VERSION ""

NS_ :

BS_:

BU_: XXX DSU HCU EPS IPAS XX X

BO_ 359 STEERING_IPAS_COMMA: 8 IPAS

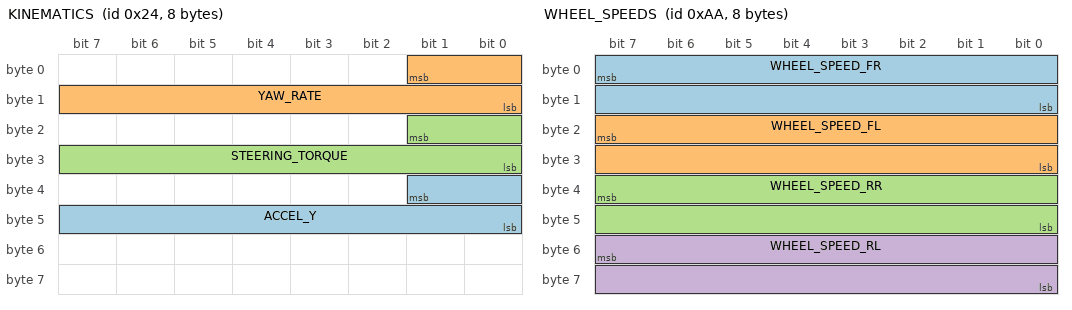
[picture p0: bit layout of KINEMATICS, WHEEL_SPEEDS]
BO_ 36 KINEMATICS: 8 XXX
 SG_ ACCEL_Y : 33|10@0+ (1,-512) [0|65535] "" XXX
 SG_ YAW_RATE : 1|10@0+ (1,-512) [0|65535] "" XXX
 SG_ STEERING_TORQUE : 17|10@0+ (1,-512) [0|65535] "" XXX

BO_ 166 BRAKE: 8 XXX
 SG_ BRAKE_AMOUNT : 7|8@0+ (1,0) [0|255] "" XXX
 SG_ BRAKE_PEDAL : 23|8@0+ (1,0) [0|255] "" XXX

BO_ 170 WHEEL_SPEEDS: 8 XXX
 SG_ WHEEL_SPEED_FR : 7|16@0+ (0.01,-67.67) [0|250] "kph" XXX
 SG_ WHEEL_SPEED_FL : 23|16@0+ (0.01,-67.67) [0|250] "kph" XXX
 SG_ WHEEL_SPEED_RR : 39|16@0+ (0.01,-67.67) [0|250] "kph" XXX
 SG_ WHEEL_SPEED_RL : 55|16@0+ (0.01,-67.67) [0|250] "kph" XXX

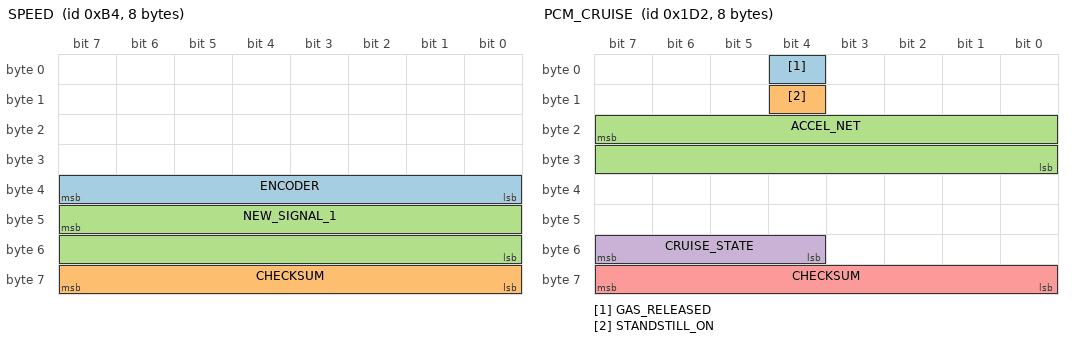
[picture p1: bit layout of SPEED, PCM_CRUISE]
BO_ 180 SPEED: 8 XXX
 SG_ ENCODER : 39|8@0+ (1,0) [0|255] "" XXX
 SG_ CHECKSUM : 63|8@0+ (1,0) [0|255] "" XXX
 SG_ NEW_SIGNAL_1 : 47|16@0+ (0.01,0) [0|65535] "" XXX

BO_ 466 PCM_CRUISE: 8 XXX
 SG_ GAS_RELEASED : 4|1@0+ (1,0) [0|1] "" XXX
 SG_ STANDSTILL_ON : 12|1@0+ (1,0) [0|1] "" XXX
 SG_ ACCEL_NET : 23|16@0- (0.001,0) [-20|20] "m/s2" XXX
 SG_ CRUISE_STATE : 55|4@0+ (1,0) [0|15] "" XXX
 SG_ CHECKSUM : 63|8@0+ (1,0) [0|255] "" XXX

BO_ 552 ACCELEROMETER: 8 XXX
 SG_ ACCEL_Z : 22|15@0- (1,0) [0|32767] "" XXX
 SG_ ACCEL_X : 6|15@0- (0.001,0) [-20|20] "m/s2" XXX

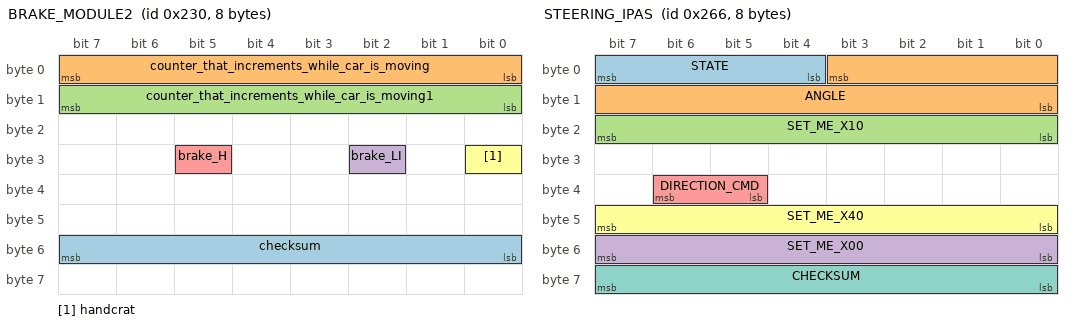
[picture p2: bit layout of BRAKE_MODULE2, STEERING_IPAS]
BO_ 560 BRAKE_MODULE2: 8 XXX
 SG_ checksum : 55|8@0+ (1,0) [0|255] "" XXX
 SG_ counter_that_increments_while_car_is_moving : 7|8@0+ (1,0) [0|255] "" XXX
 SG_ counter_that_increments_while_car_is_moving1 : 15|8@0+ (1,0) [0|255] "" XXX
 SG_ brake_LI : 26|1@1+ (1,0) [0|1] "" XXX
 SG_ brake_H : 29|1@0+ (1,0) [0|1] "" XXX
 SG_ handcrat : 24|1@1+ (1,0) [0|3] "" XXX

BO_ 614 STEERING_IPAS: 8 IPAS
 SG_ STATE : 7|4@0+ (1,0) [0|15] "" XXX
 SG_ ANGLE : 3|12@0- (1.5,0) [-510|510] "deg" XXX
 SG_ SET_ME_X10 : 23|8@0+ (1,0) [0|255] "" XXX
 SG_ SET_ME_X00 : 55|8@0+ (1,0) [0|255] "" XXX
 SG_ DIRECTION_CMD : 38|2@0+ (1,0) [0|3] "" XXX
 SG_ SET_ME_X40 : 47|8@0+ (1,0) [0|255] "" XXX
 SG_ CHECKSUM : 63|8@0+ (1,0) [0|255] "" XXX

BO_ 643 PRE_COLLISION: 8 XXX

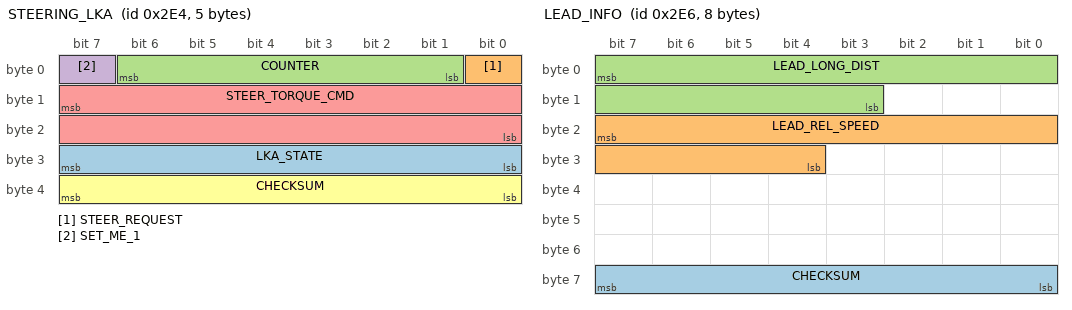
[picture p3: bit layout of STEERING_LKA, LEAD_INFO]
BO_ 740 STEERING_LKA: 5 XXX
 SG_ LKA_STATE : 31|8@0+ (1,0) [0|255] "" XXX
 SG_ STEER_REQUEST : 0|1@0+ (1,0) [0|1] "" XXX
 SG_ COUNTER : 6|6@0+ (1,0) [0|63] "" XXX
 SG_ SET_ME_1 : 7|1@0+ (1,0) [0|1] "" XXX
 SG_ STEER_TORQUE_CMD : 15|16@0- (1,0) [0|65535] "" XXX
 SG_ CHECKSUM : 39|8@0+ (1,0) [0|255] "" XXX

BO_ 742 LEAD_INFO: 8 DSU
 SG_ CHECKSUM : 63|8@0+ (1,0) [0|255] "" HCU
 SG_ LEAD_REL_SPEED : 23|12@0- (0.025,0) [-100|100] "m/s" HCU
 SG_ LEAD_LONG_DIST : 7|13@0+ (0.05,0) [0|300] "m" HCU

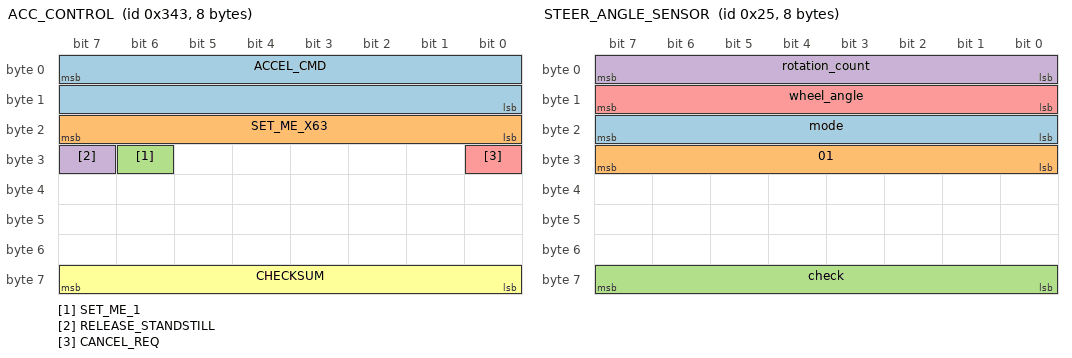
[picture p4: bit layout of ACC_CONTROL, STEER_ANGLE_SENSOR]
BO_ 835 ACC_CONTROL: 8 DSU
 SG_ ACCEL_CMD : 7|16@0- (0.001,0) [-20|20] "m/s2" HCU
 SG_ SET_ME_X63 : 23|8@0+ (1,0) [0|255] "" HCU
 SG_ SET_ME_1 : 30|1@0+ (1,0) [0|1] "" HCU
 SG_ RELEASE_STANDSTILL : 31|1@0+ (1,0) [0|1] "" HCU
 SG_ CANCEL_REQ : 24|1@0+ (1,0) [0|1] "" HCU
 SG_ CHECKSUM : 63|8@0+ (1,0) [0|255] "" XXX

BO_ 1556 STEERING_LEVERS: 8 XXX
 SG_ TURN_SIGNALS : 29|2@0+ (1,0) [0|3] "" XXX

BO_ 37 STEER_ANGLE_SENSOR: 8 XXX
 SG_ mode : 23|8@0+ (1,0) [0|255] "" XXX
 SG_ 01 : 31|8@0+ (1,0) [0|255] "" XXX
 SG_ check : 63|8@0+ (1,0) [0|255] "" XXX
 SG_ rotation_count : 7|8@0+ (1,0) [0|255] "" XXX
 SG_ wheel_angle : 15|8@0- (1,0) [0|255] "" XXX

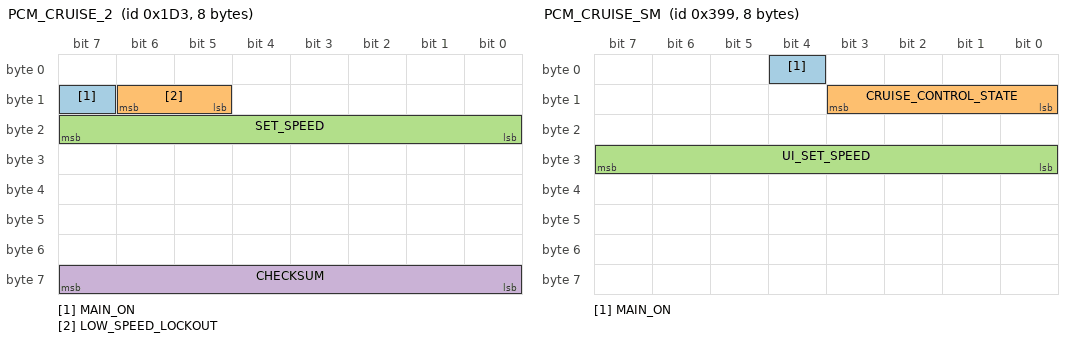
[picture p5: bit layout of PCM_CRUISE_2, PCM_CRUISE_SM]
BO_ 467 PCM_CRUISE_2: 8 XXX
 SG_ MAIN_ON : 15|1@0+ (1,0) [0|1] "" XXX
 SG_ LOW_SPEED_LOCKOUT : 14|2@0+ (1,0) [0|3] "kph" XXX
 SG_ SET_SPEED : 23|8@0+ (1,0) [0|255] "kph" XXX
 SG_ CHECKSUM : 63|8@0+ (1,0) [0|255] "" XXX

BO_ 921 PCM_CRUISE_SM: 8 XXX
 SG_ MAIN_ON : 4|1@0+ (1,0) [0|1] "" XXX
 SG_ CRUISE_CONTROL_STATE : 11|4@0+ (1,0) [0|15] "" XXX
 SG_ UI_SET_SPEED : 31|8@0+ (1,0) [0|255] "" XXX

BO_ 951 ESP_CONTROL: 8 ESP
 SG_ TC_DISABLED : 13|1@0+ (1,0) [0|1] "" XXX
 SG_ BRAKE_LIGHTS_ACC : 18|1@0+ (1,0) [0|1] "" XXX

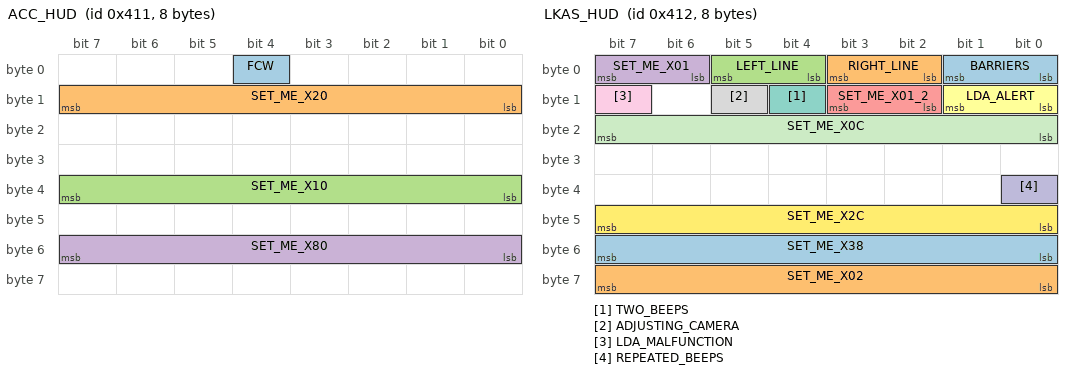
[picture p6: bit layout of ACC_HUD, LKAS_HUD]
BO_ 1041 ACC_HUD: 8 DSU
 SG_ FCW : 4|1@0+ (1,0) [0|1] "" XXX
 SG_ SET_ME_X20 : 15|8@0+ (1,0) [0|1] "" XXX
 SG_ SET_ME_X10 : 39|8@0+ (1,0) [0|1] "" XXX
 SG_ SET_ME_X80 : 55|8@0+ (1,0) [0|1] "" XXX

BO_ 1042 LKAS_HUD: 8 XXX
 SG_ BARRIERS : 1|2@0+ (1,0) [0|3] "" XXX
 SG_ RIGHT_LINE : 3|2@0+ (1,0) [0|3] "" XXX
 SG_ LEFT_LINE : 5|2@0+ (1,0) [0|3] "" XXX
 SG_ SET_ME_X01 : 7|2@0+ (1,0) [0|3] "" XXX
 SG_ SET_ME_X01_2 : 11|2@0+ (1,0) [0|3] "" XXX
 SG_ LDA_ALERT : 9|2@0+ (1,0) [0|3] "" XXX
 SG_ TWO_BEEPS : 12|1@0+ (1,0) [0|1] "" XXX
 SG_ ADJUSTING_CAMERA : 13|1@0+ (1,0) [0|1] "" XXX
 SG_ LDA_MALFUNCTION : 15|1@0+ (1,0) [0|1] "" XXX
 SG_ REPEATED_BEEPS : 32|1@0+ (1,0) [0|1] "" XXX
 SG_ SET_ME_X0C : 23|8@0+ (1,0) [0|1] "" XXX
 SG_ SET_ME_X2C : 47|8@0+ (1,0) [0|1] "" XXX
 SG_ SET_ME_X38 : 55|8@0+ (1,0) [0|1] "" XXX
 SG_ SET_ME_X02 : 63|8@0+ (1,0) [0|1] "" XXX

BO_ 1553 UI_SEETING: 8 XXX
 SG_ UNITS : 26|2@0+ (1,0) [0|3] "" XXX

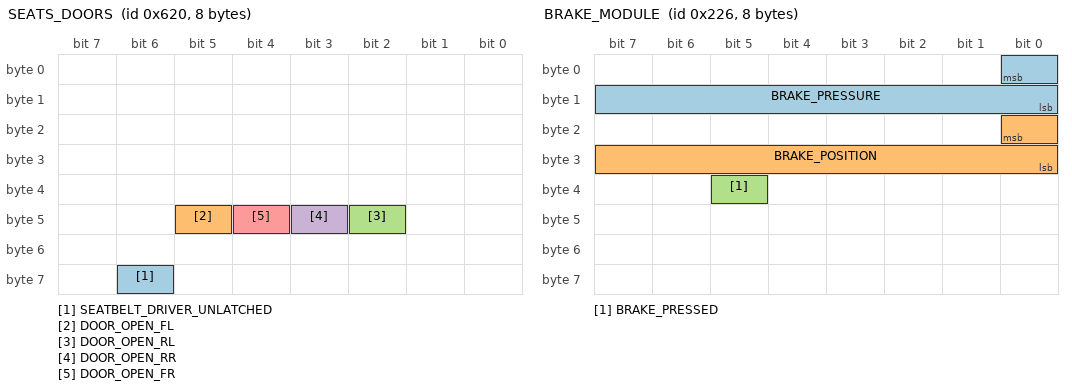
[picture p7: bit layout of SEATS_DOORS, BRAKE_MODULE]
BO_ 1568 SEATS_DOORS: 8 XXX
 SG_ SEATBELT_DRIVER_UNLATCHED : 62|1@0+ (1,0) [0|1] "" XXX
 SG_ DOOR_OPEN_FL : 45|1@0+ (1,0) [0|1] "" XXX
 SG_ DOOR_OPEN_RL : 42|1@0+ (1,0) [0|1] "" XXX
 SG_ DOOR_OPEN_RR : 43|1@0+ (1,0) [0|1] "" XXX
 SG_ DOOR_OPEN_FR : 44|1@0+ (1,0) [0|1] "" XXX

BO_ 1570 LIGHT_STALK: 8 SCM
 SG_ AUTO_HIGH_BEAM : 37|1@0+ (1,0) [0|1] "" XXX

BO_ 295 GEAR_PACKET: 8 XXX

BO_ 550 BRAKE_MODULE: 8 XXX
 SG_ BRAKE_PRESSURE : 0|9@0+ (1,0) [0|511] "" XXX
 SG_ BRAKE_POSITION : 16|9@0+ (1,0) [0|511] "" XXX
 SG_ BRAKE_PRESSED : 37|1@0+ (1,0) [0|1] "" XXX

BO_ 581 GAS_PEDAL: 8 XXX
 SG_ GAS_PEDAL : 23|8@0+ (0.005,0) [0|1] "" XXX

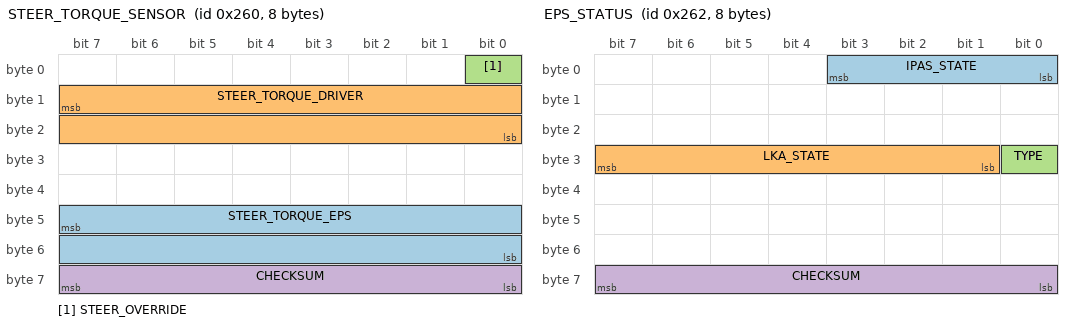
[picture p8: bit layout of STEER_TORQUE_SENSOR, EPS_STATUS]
BO_ 608 STEER_TORQUE_SENSOR: 8 XXX
 SG_ STEER_TORQUE_EPS : 47|16@0- (0.66,0) [-20000|20000] "" XXX
 SG_ STEER_TORQUE_DRIVER : 15|16@0- (1,0) [-32768|32767] "" XXX
 SG_ STEER_OVERRIDE : 0|1@0+ (1,0) [0|1] "" XXX
 SG_ CHECKSUM : 63|8@0+ (1,0) [0|255] "" XXX

BO_ 610 EPS_STATUS: 8 EPS
 SG_ IPAS_STATE : 3|4@0+ (1,0) [0|15] "" XXX
 SG_ LKA_STATE : 31|7@0+ (1,0) [0|127] "" XXX
 SG_ TYPE : 24|1@0+ (1,0) [0|1] "" XXX
 SG_ CHECKSUM : 63|8@0+ (1,0) [0|255] "" XXX

BO_ 1083 AUTOPARK_STATUS: 8 IPAS
 SG_ STATE : 7|4@0+ (1,0) [0|15] "" XXX

BO_ 179 SPEED_2: 8 XXX
 SG_ SPEED : 7|16@0+ (1,0) [0|65535] "" XXX
 SG_ CHECKSUM : 47|8@0+ (1,0) [0|255] "" XXX

BO_ 177 SPEED_1: 8 XXX
 SG_ SPEED : 7|16@0+ (1,0) [0|65535] "" XXX
 SG_ CHECKSUM : 47|8@0+ (1,0) [0|255] "" XXX
 SG_ Uncertain_gear1 : 15|8@0+ (1,0) [0|255] "" XXX
 SG_ Uncertain_gear2 : 35|4@0+ (1,0) [0|255] "" XXX
 SG_ speed : 23|8@0+ (2.5,0) [0|255] "" XXX

BO_ 1792 NEW_MSG_2: 8 XXX
 SG_ NEW_SIGNAL_1 : 7|24@0+ (1,0) [0|16777215] "" XXX

BO_ 1872 NEW_MSG_3: 8 XXX
 SG_ NEW_SIGNAL_1 : 7|24@0+ (1,0) [0|16777215] "" XXX

BO_ 2016 NEW_MSG_4: 8 XXX
 SG_ NEW_SIGNAL_1 : 7|24@0+ (1,0) [0|16777215] "" XXX

BO_ 2018 NEW_MSG_5: 8 XXX
 SG_ NEW_SIGNAL_1 : 7|24@0+ (1,0) [0|16777215] "" XXX

BO_ 2019 NEW_MSG_6: 8 XXX
 SG_ NEW_SIGNAL_1 : 7|24@0+ (1,0) [0|16777215] "" XXX

BO_ 2027 NEW_MSG_7: 8 XXX
 SG_ NEW_SIGNAL_1 : 7|24@0+ (1,0) [0|16777215] "" XXX

BO_ 1462 door: 8 XXX
 SG_ doorpause : 7|8@0+ (1,0) [0|255] "" XXX
 SG_ door_80off : 15|8@0+ (1,0) [0|255] "" XXX

BO_ 1517 NEW_MSG_8: 8 XXX

BO_ 1528 NEW_MSG_9: 8 XXX

BO_ 1538 NEW_MSG_10: 8 XXX

BO_ 1425 NEW_MSG_11: 8 XXX

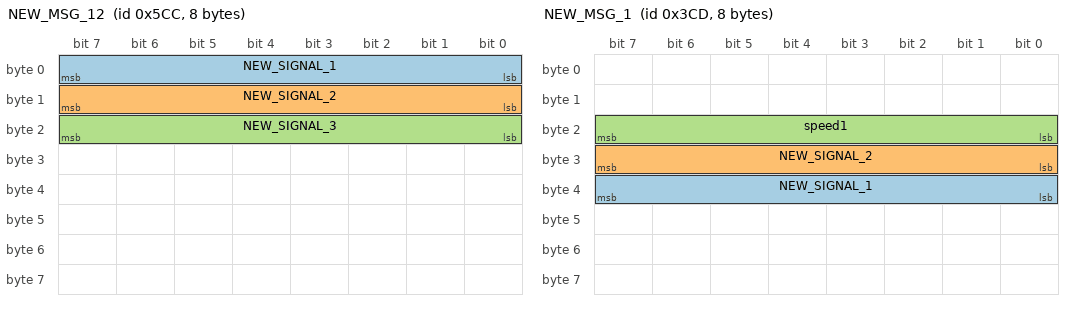
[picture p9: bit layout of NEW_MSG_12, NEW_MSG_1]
BO_ 1484 NEW_MSG_12: 8 XXX
 SG_ NEW_SIGNAL_1 : 7|8@0+ (1,0) [0|255] "" XXX
 SG_ NEW_SIGNAL_2 : 15|8@0+ (1,0) [0|255] "" XXX
 SG_ NEW_SIGNAL_3 : 23|8@0+ (1,0) [0|255] "" XXX

BO_ 1407 NEW_MSG_13: 8 XXX
 SG_ Headlamps_1 : 12|1@0+ (1,0) [0|3] "" XXX
 SG_ Headlamps_3 : 11|1@1+ (1,0) [0|3] "" XXX
 SG_ pause : 7|8@0+ (1,0) [0|255] "" XXX
 SG_ Headlamps_2 : 13|2@0+ (1,0) [0|3] "" XXX
 SG_ dimmed : 20|2@0+ (1,0) [0|3] "" XXX

BO_ 580 NEW_MSG_14: 8 XXX
 SG_ NEW_SIGNAL_1 : 40|8@1+ (1,0) [0|255] "" XXX
 SG_ NEW_SIGNAL_2 : 56|8@1+ (1,0) [0|255] "" XXX

BO_ 840 NEW_MSG_15: 8 XXX
 SG_ NEW_SIGNAL_2 : 15|16@0+ (1,0) [0|255] "" XXX
 SG_ NEW_SIGNAL_1 : 39|16@0+ (0.0012,0) [0|255] "" XXX

BO_ 288 gear: 8 XXX
 SG_ gear_1 : 47|8@0+ (1,0) [0|255] "" XXX
 SG_ gear_2 : 63|8@0+ (1,0) [0|255] "" XXX

BO_ 973 NEW_MSG_1: 8 XXX
 SG_ NEW_SIGNAL_1 : 39|8@0+ (1,0) [0|255] "" XXX
 SG_ NEW_SIGNAL_2 : 31|8@0+ (1,0) [0|255] "" XXX
 SG_ speed1 : 23|8@0+ (2.3,0) [0|255] "" XXX

BO_ 970 speedkm: 8 XXX
 SG_ speedkm : 23|8@0+ (2.4,0) [0|255] "" XXX

BO_ 1324 Engine_coolant_temp: 8 XXX
 SG_ Engine_coolant_temp : 15|8@0+ (0.5,0) [0|255] "" XXX

BO_ 1344 Shift_lever: 8 XXX
 SG_ gear : 15|8@0+ (1,0) [0|255] "" XXX

CM_ SG_ 36 ACCEL_Y "unit is tbd";
CM_ SG_ 36 YAW_RATE "verify";
CM_ SG_ 36 STEERING_TORQUE "does not seem the steer torque, tbd";
CM_ SG_ 466 ACCEL_NET "net acceleration produced by the system, given ACCEL_CMD, road grade and other factors";
CM_ SG_ 614 ANGLE "set to measured angle when ipas control isn't active";
CM_ SG_ 467 LOW_SPEED_LOCKOUT "in low speed lockout, system would always disengage below 28mph";
CM_ SG_ 467 SET_SPEED "43 kph are shown as 28mph, so conversion isnt perfect";
CM_ SG_ 921 UI_SET_SPEED "set speed shown in UI with user set unit";
CM_ SG_ 951 BRAKE_LIGHTS_ACC "brake lights when ACC commands decel";
CM_ SG_ 1042 REPEATED_BEEPS "recommended for fcw and other important alerts";
CM_ SG_ 550 BRAKE_PRESSURE "seems prop to pedal force";
CM_ SG_ 550 BRAKE_POSITION "seems proportional to pedal displacement, unclear the max value of 0x1c8";
CM_ SG_ 581 GAS_PEDAL "it seems slightly filtered";
CM_ SG_ 610 TYPE "seems 1 on Corolla, 0 on all others";
CM_ SG_ 1083 STATE "when the dashboard button is pressed, the value changes from zero to non-zero";
VAL_ 466 CRUISE_STATE 8 "active" 7 "standstill" 1 "off" ;
VAL_ 614 STATE 3 "enabled" 1 "disabled" ;
VAL_ 614 DIRECTION_CMD 3 "right" 2 "center" 1 "left" ;
VAL_ 1556 TURN_SIGNALS 3 "none" 2 "right" 1 "left" ;
VAL_ 467 LOW_SPEED_LOCKOUT 2 "low speed locked" 1 "ok" ;
VAL_ 921 CRUISE_CONTROL_STATE 2 "disabled" 11 "hold" 10 "hold_waiting_user_cmd" 6 "enabled" 5 "faulted" ;
VAL_ 1042 BARRIERS 3 "both" 2 "right" 1 "left" 0 "none" ;
VAL_ 1042 RIGHT_LINE 3 "orange" 2 "double" 1 "solid" 0 "none" ;
VAL_ 1042 LEFT_LINE 3 "orange" 2 "double" 1 "solid" 0 "none" ;
VAL_ 1042 LDA_ALERT 3 "hold with continuous beep" 2 "LDA unavailable" 1 "hold" 0 "none" ;
VAL_ 1553 UNITS 1 "km" 2 "miles" ;
VAL_ 610 IPAS_STATE 5 "override" 3 "enabled" 1 "disabled" ;
VAL_ 610 LKA_STATE 25 "temporary_fault" 9 "temporary_fault2" 5 "active" 1 "standby" ;
CM_ "AUTOGENERATED FILE, DO NOT EDIT"
CM_ "Imported file _comma.dbc s";
CM_ "Imported file _comma.dbc st
CM_ "Imported file _comma.dbc st";
CM_ "Imported file _comma.dbc sta
CM_ "Imported file _comma.dbc st";
CM_ "Imported file _comma.dbc sta
CM_ "Imported file _comma.dbc sta";
CM_ "Imported file _comma.dbc star
CM_ "Imported file _comma.dbc st";
CM_ "Imported file _comma.dbc sta
CM_ "Imported file _comma.dbc sta";
CM_ "Imported file _comma.dbc star
CM_ "Imported file _comma.dbc sta";
CM_ "Imported file _comma.dbc star
CM_ "Imported file _comma.dbc star";
CM_ "Imported file _comma.dbc start
CM_ "Imported file _comma.dbc st";
CM_ "Imported file _comma.dbc sta
CM_ "Imported file _comma.dbc sta";
CM_ "Imported file _comma.dbc star
CM_ "Imported file _comma.dbc sta";
CM_ "Imported file _comma.dbc star
CM_ "Imported file _comma.dbc star";
CM_ "Imported file _comma.dbc start
CM_ "Imported file _comma.dbc sta";
CM_ "Imported file _comma.dbc star
CM_ "Imported file _comma.dbc star";
CM_ "Imported file _comma.dbc start
CM_ "Imported file _comma.dbc star";
CM_ "Imported file _comma.dbc start
CM_ "Imported file _comma.dbc start";
CM_ "Imported file _comma.dbc starts
CM_ "Imported file _comma.dbc s";
CM_ "Imported file _comma.dbc st
CM_ "Imported file _comma.dbc st";
CM_ "Imported file _comma.dbc sta
CM_ "Imported file _comma.dbc st";
CM_ "Imported file _comma.dbc sta
CM_ "Imported file _comma.dbc sta";
CM_ "Imported file _comma.dbc star
CM_ "Imported file _comma.dbc st";
CM_ "Imported file _comma.dbc sta
CM_ "Imported file _comma.dbc sta";
CM_ "Imported file _comma.dbc star
CM_ "Imported file _comma.dbc sta";
CM_ "Imported file _comma.dbc star
CM_ "Imported file _comma.dbc star";
CM_ "Imported file _comma.dbc start
CM_ "Imported file _comma.dbc st";
CM_ "Imported file _comma.dbc sta
CM_ "Imported file _comma.dbc sta";
CM_ "Imported file _comma.dbc star
CM_ "Imported file _comma.dbc sta";
CM_ "Imported file _comma.dbc star
CM_ "Imported file _comma.dbc star";
CM_ "Imported file _comma.dbc start
CM_ "Imported file _comma.dbc sta";
CM_ "Imported file _comma.dbc star
CM_ "Imported file _comma.dbc star";
CM_ "Imported file _comma.dbc start
CM_ "Imported file _comma.dbc star";
CM_ "Imported file _comma.dbc start
CM_ "Imported file _comma.dbc start";
CM_ "Imported file _comma.dbc starts
CM_ "Imported file _comma.dbc st";
CM_ "Imported file _comma.dbc sta
CM_ "Imported file _comma.dbc sta";
CM_ "Imported file _comma.dbc star
CM_ "Imported file _comma.dbc sta";
CM_ "Imported file _comma.dbc star
CM_ "Imported file _comma.dbc star";
CM_ "Imported file _comma.dbc start
CM_ "Imported file _comma.dbc sta";
CM_ "Imported file _comma.dbc star
CM_ "Imported file _comma.dbc star";
CM_ "Imported file _comma.dbc start
CM_ "Imported file _comma.dbc star";
CM_ "Imported file _comma.dbc start
CM_ "Imported file _comma.dbc start";
CM_ "Imported file _comma.dbc starts
CM_ "Imported file _comma.dbc st";
CM_ "Imported file _comma.dbc sta
CM_ "Imported file _comma.dbc sta";
CM_ "Imported file _comma.dbc star
CM_ "Imported file _comma.dbc sta";
CM_ "Imported file _comma.dbc star
CM_ "Imported file _comma.dbc star";
CM_ "Imported file _comma.dbc start
CM_ "Imported file _comma.dbc sta";
CM_ "Imported file _comma.dbc star
CM_ "Imported file _comma.dbc star";
CM_ "Imported file _comma.dbc start
CM_ "Imported file _comma.dbc star";
CM_ "Imported file _comma.dbc start
CM_ "Imported file _comma.dbc start";
CM_ "Imported file _comma.dbc starts
CM_ "Imported file _comma.dbc sta";
CM_ "Imported file _comma.dbc star
CM_ "Imported file _comma.dbc star";
CM_ "Imported file _comma.dbc start
CM_ "Imported file _comma.dbc star";
CM_ "Imported file _comma.dbc start
CM_ "Imported file _comma.dbc start";
CM_ "Imported file _comma.dbc starts
CM_ "Imported file _comma.dbc sta";
CM_ "Imported file _comma.dbc star
CM_ "Imported file _comma.dbc star";
CM_ "Imported file _comma.dbc start
CM_ "Imported file _comma.dbc star";
CM_ "Imported file _comma.dbc start
CM_ "Imported file _comma.dbc start";
CM_ "Imported file _comma.dbc starts
CM_ "Imported file _comma.dbc star";
CM_ "Imported file _comma.dbc start
CM_ "Imported file _comma.dbc start";
CM_ "Imported file _comma.dbc starts
CM_ "Imported file _comma.dbc star";
CM_ "Imported file _comma.dbc start
CM_ "Imported file _comma.dbc start";
CM_ "Imported file _comma.dbc starts
CM_ "Imported file _comma.dbc start";
CM_ "Imported file _comma.dbc starts
CM_ "Imported file _comma.dbc start";
CM_ "Imported file _comma.dbc starts
CM_ "Imported file _comma.dbc starts";
CM_ "Imported file _comma.dbc starts 
CM_ "Imported file _comma.dbc starts ";
CM_ "Imported file _comma.dbc starts h
CM_ "Imported file _comma.dbc st";
CM_ "Imported file _comma.dbc sta
CM_ "Imported file _comma.dbc sta";
CM_ "Imported file _comma.dbc star
CM_ "Imported file _comma.dbc sta";
CM_ "Imported file _comma.dbc star
CM_ "Imported file _comma.dbc star";
CM_ "Imported file _comma.dbc start
CM_ "Imported file _comma.dbc sta";
CM_ "Imported file _comma.dbc star
CM_ "Imported file _comma.dbc star";
CM_ "Imported file _comma.dbc start
CM_ "Imported file _comma.dbc star";
CM_ "Imported file _comma.dbc start
CM_ "Imported file _comma.dbc start";
CM_ "Imported file _comma.dbc starts
CM_ "Imported file _comma.dbc st";
CM_ "Imported file _comma.dbc sta
CM_ "Imported file _comma.dbc sta";
CM_ "Imported file _comma.dbc star
CM_ "Imported file _comma.dbc sta";
CM_ "Imported file _comma.dbc star
CM_ "Imported file _comma.dbc star";
CM_ "Imported file _comma.dbc start
CM_ "Imported file _comma.dbc sta";
CM_ "Imported file _comma.dbc star
CM_ "Imported file _comma.dbc star";
CM_ "Imported file _comma.dbc start
CM_ "Imported file _comma.dbc star";
CM_ "Imported file _comma.dbc start
CM_ "Imported file _comma.dbc start";
CM_ "Imported file _comma.dbc starts
CM_ "Imported file _comma.dbc sta";
CM_ "Imported file _comma.dbc star
CM_ "Imported file _comma.dbc star";
CM_ "Imported file _comma.dbc start
CM_ "Imported file _comma.dbc star";
CM_ "Imported file _comma.dbc start
CM_ "Imported file _comma.dbc start";
CM_ "Imported file _comma.dbc starts
CM_ "Imported file _comma.dbc sta";
CM_ "Imported file _comma.dbc star
CM_ "Imported file _comma.dbc star";
CM_ "Imported file _comma.dbc start
CM_ "Imported file _comma.dbc star";
CM_ "Imported file _comma.dbc start
CM_ "Imported file _comma.dbc start";
CM_ "Imported file _comma.dbc starts
CM_ "Imported file _comma.dbc star";
CM_ "Imported file _comma.dbc start
CM_ "Imported file _comma.dbc start";
CM_ "Imported file _comma.dbc starts
CM_ "Imported file _comma.dbc star";
CM_ "Imported file _comma.dbc start
CM_ "Imported file _comma.dbc start";
CM_ "Imported file _comma.dbc starts
CM_ "Imported file _comma.dbc start";
CM_ "Imported file _comma.dbc starts
CM_ "Imported file _comma.dbc start";
CM_ "Imported file _comma.dbc starts
CM_ "Imported file _comma.dbc starts";
CM_ "Imported file _comma.dbc starts 
CM_ "Imported file _comma.dbc starts ";
CM_ "Imported file _comma.dbc starts h
CM_ "Imported file _comma.dbc sta";
CM_ "Imported file _comma.dbc star
CM_ "Imported file _comma.dbc star";
CM_ "Imported file _comma.dbc start
CM_ "Imported file _comma.dbc star";
CM_ "Imported file _comma.dbc start
CM_ "Imported file _comma.dbc start";
CM_ "Imported file _comma.dbc starts
CM_ "Imported file _comma.dbc sta";
CM_ "Imported file _comma.dbc star
CM_ "Imported file _comma.dbc star";
CM_ "Imported file _comma.dbc start
CM_ "Imported file _comma.dbc star";
CM_ "Imported file _comma.dbc start
CM_ "Imported file _comma.dbc start";
CM_ "Imported file _comma.dbc starts
CM_ "Imported file _comma.dbc star";
CM_ "Imported file _comma.dbc start
CM_ "Imported file _comma.dbc start";
CM_ "Imported file _comma.dbc starts
CM_ "Imported file _comma.dbc star";
CM_ "Imported file _comma.dbc start
CM_ "Imported file _comma.dbc start";
CM_ "Imported file _comma.dbc starts
CM_ "Imported file _comma.dbc start";
CM_ "Imported file _comma.dbc starts
CM_ "Imported file _comma.dbc start";
CM_ "Imported file _comma.dbc starts
CM_ "Imported file _comma.dbc starts";
CM_ "Imported file _comma.dbc starts 
CM_ "Imported file _comma.dbc starts ";
CM_ "Imported file _comma.dbc starts h
CM_ "Imported file _comma.dbc star";
CM_ "Imported file _comma.dbc start
CM_ "Imported file _comma.dbc start";
CM_ "Imported file _comma.dbc starts
CM_ "Imported file _comma.dbc star";
CM_ "Imported file _comma.dbc start
CM_ "Imported file _comma.dbc start";
CM_ "Imported file _comma.dbc starts
CM_ "Imported file _comma.dbc start";
CM_ "Imported file _comma.dbc starts
CM_ "Imported file _comma.dbc start";
CM_ "Imported file _comma.dbc starts
CM_ "Imported file _comma.dbc starts";
CM_ "Imported file _comma.dbc starts 
CM_ "Imported file _comma.dbc starts ";
CM_ "Imported file _comma.dbc starts h
CM_ "Imported file _comma.dbc start";
CM_ "Imported file _comma.dbc starts
CM_ "Imported file _comma.dbc start";
CM_ "Imported file _comma.dbc starts
CM_ "Imported file _comma.dbc starts";
CM_ "Imported file _comma.dbc starts 
CM_ "Imported file _comma.dbc starts ";
CM_ "Imported file _comma.dbc starts h
CM_ "Imported file _comma.dbc starts";
CM_ "Imported file _comma.dbc starts 
CM_ "Imported file _comma.dbc starts ";
CM_ "Imported file _comma.dbc starts h
CM_ "Imported file _comma.dbc starts ";
CM_ "Imported file _comma.dbc starts h
CM_ "Imported file _comma.dbc starts h";
CM_ "Imported file _comma.dbc starts he
CM_ "Imported file _comma.dbc st";
CM_ "Imported file _comma.dbc sta
CM_ "Imported file _comma.dbc sta";
CM_ "Imported file _comma.dbc star
CM_ "Imported file _comma.dbc sta";
CM_ "Imported file _comma.dbc star
CM_ "Imported file _comma.dbc star";
CM_ "Imported file _comma.dbc start
CM_ "Imported file _comma.dbc sta";
CM_ "Imported file _comma.dbc star
CM_ "Imported file _comma.dbc star";
CM_ "Imported file _comma.dbc start
CM_ "Imported file _comma.dbc star";
CM_ "Imported file _comma.dbc start
CM_ "Imported file _comma.dbc start";
CM_ "Imported file _comma.dbc starts
CM_ "Imported file _comma.dbc st";
CM_ "Imported file _comma.dbc sta
CM_ "Imported file _comma.dbc sta";
CM_ "Imported file _comma.dbc star
CM_ "Imported file _comma.dbc sta";
CM_ "Imported file _comma.dbc star
CM_ "Imported file _comma.dbc star";
CM_ "Imported file _comma.dbc start
CM_ "Imported file _comma.dbc sta";
CM_ "Imported file _comma.dbc star
CM_ "Imported file _comma.dbc star";
CM_ "Imported file _comma.dbc start
CM_ "Imported file _comma.dbc star";
CM_ "Imported file _comma.dbc start
CM_ "Imported file _comma.dbc start";
CM_ "Imported file _comma.dbc starts
CM_ "Imported file _comma.dbc sta";
CM_ "Imported file _comma.dbc star
CM_ "Imported file _comma.dbc star";
CM_ "Imported file _comma.dbc start
CM_ "Imported file _comma.dbc star";
CM_ "Imported file _comma.dbc start
CM_ "Imported file _comma.dbc start";
CM_ "Imported file _comma.dbc starts
CM_ "Imported file _comma.dbc sta";
CM_ "Imported file _comma.dbc star
CM_ "Imported file _comma.dbc star";
CM_ "Imported file _comma.dbc start
CM_ "Imported file _comma.dbc star";
CM_ "Imported file _comma.dbc start
CM_ "Imported file _comma.dbc start";
CM_ "Imported file _comma.dbc starts
CM_ "Imported file _comma.dbc star";
CM_ "Imported file _comma.dbc start
CM_ "Imported file _comma.dbc start";
CM_ "Imported file _comma.dbc starts
CM_ "Imported file _comma.dbc star";
CM_ "Imported file _comma.dbc start
CM_ "Imported file _comma.dbc start";
CM_ "Imported file _comma.dbc starts
CM_ "Imported file _comma.dbc start";
CM_ "Imported file _comma.dbc starts
CM_ "Imported file _comma.dbc start";
CM_ "Imported file _comma.dbc starts
CM_ "Imported file _comma.dbc starts";
CM_ "Imported file _comma.dbc starts 
CM_ "Imported file _comma.dbc starts ";
CM_ "Imported file _comma.dbc starts h
CM_ "Imported file _comma.dbc sta";
CM_ "Imported file _comma.dbc star
CM_ "Imported file _comma.dbc star";
CM_ "Imported file _comma.dbc start
CM_ "Imported file _comma.dbc star";
CM_ "Imported file _comma.dbc start
CM_ "Imported file _comma.dbc start";
CM_ "Imported file _comma.dbc starts
CM_ "Imported file _comma.dbc sta";
CM_ "Imported file _comma.dbc star
CM_ "Imported file _comma.dbc star";
CM_ "Imported file _comma.dbc start
CM_ "Imported file _comma.dbc star";
CM_ "Imported file _comma.dbc start
CM_ "Imported file _comma.dbc start";
CM_ "Imported file _comma.dbc starts
CM_ "Imported file _comma.dbc star";
CM_ "Imported file _comma.dbc start
CM_ "Imported file _comma.dbc start";
CM_ "Imported file _comma.dbc starts
CM_ "Imported file _comma.dbc star";
CM_ "Imported file _comma.dbc start
CM_ "Imported file _comma.dbc start";
CM_ "Imported file _comma.dbc starts
CM_ "Imported file _comma.dbc start";
CM_ "Imported file _comma.dbc starts
CM_ "Imported file _comma.dbc start";
CM_ "Imported file _comma.dbc starts
CM_ "Imported file _comma.dbc starts";
CM_ "Imported file _comma.dbc starts 
CM_ "Imported file _comma.dbc starts ";
CM_ "Imported file _comma.dbc starts h
CM_ "Imported file _comma.dbc star";
CM_ "Imported file _comma.dbc start
CM_ "Imported file _comma.dbc start";
CM_ "Imported file _comma.dbc starts
CM_ "Imported file _comma.dbc star";
CM_ "Imported file _comma.dbc start
CM_ "Imported file _comma.dbc start";
CM_ "Imported file _comma.dbc starts
CM_ "Imported file _comma.dbc start";
CM_ "Imported file _comma.dbc starts
CM_ "Imported file _comma.dbc start";
CM_ "Imported file _comma.dbc starts
CM_ "Imported file _comma.dbc starts";
CM_ "Imported file _comma.dbc starts 
CM_ "Imported file _comma.dbc starts ";
CM_ "Imported file _comma.dbc starts h
CM_ "Imported file _comma.dbc start";
CM_ "Imported file _comma.dbc starts
CM_ "Imported file _comma.dbc start";
CM_ "Imported file _comma.dbc starts
CM_ "Imported file _comma.dbc starts";
CM_ "Imported file _comma.dbc starts 
CM_ "Imported file _comma.dbc starts ";
CM_ "Imported file _comma.dbc starts h
CM_ "Imported file _comma.dbc starts";
CM_ "Imported file _comma.dbc starts 
CM_ "Imported file _comma.dbc starts ";
CM_ "Imported file _comma.dbc starts h
CM_ "Imported file _comma.dbc starts ";
CM_ "Imported file _comma.dbc starts h
CM_ "Imported file _comma.dbc starts h";
CM_ "Imported file _comma.dbc starts he
CM_ "Imported file _comma.dbc sta";
CM_ "Imported file _comma.dbc star
CM_ "Imported file _comma.dbc star";
CM_ "Imported file _comma.dbc start
CM_ "Imported file _comma.dbc star";
CM_ "Imported file _comma.dbc start
CM_ "Imported file _comma.dbc start";
CM_ "Imported file _comma.dbc starts
CM_ "Imported file _comma.dbc sta";
CM_ "Imported file _comma.dbc star
CM_ "Imported file _comma.dbc star";
CM_ "Imported file _comma.dbc start
CM_ "Imported file _comma.dbc star";
CM_ "Imported file _comma.dbc start
CM_ "Imported file _comma.dbc start";
CM_ "Imported file _comma.dbc starts
CM_ "Imported file _comma.dbc star";
CM_ "Imported file _comma.dbc start
CM_ "Imported file _comma.dbc start";
CM_ "Imported file _comma.dbc starts
CM_ "Imported file _comma.dbc star";
CM_ "Imported file _comma.dbc start
CM_ "Imported file _comma.dbc start";
CM_ "Imported file _comma.dbc starts
CM_ "Imported file _comma.dbc start";
CM_ "Imported file _comma.dbc starts
CM_ "Imported file _comma.dbc start";
CM_ "Imported file _comma.dbc starts
CM_ "Imported file _comma.dbc starts";
CM_ "Imported file _comma.dbc starts 
CM_ "Imported file _comma.dbc starts ";
CM_ "Imported file _comma.dbc starts h
CM_ "Imported file _comma.dbc star";
CM_ "Imported file _comma.dbc start
CM_ "Imported file _comma.dbc start";
CM_ "Imported file _comma.dbc starts
CM_ "Imported file _comma.dbc star";
CM_ "Imported file _comma.dbc start
CM_ "Imported file _comma.dbc start";
CM_ "Imported file _comma.dbc starts
CM_ "Imported file _comma.dbc start";
CM_ "Imported file _comma.dbc starts
CM_ "Imported file _comma.dbc start";
CM_ "Imported file _comma.dbc starts
CM_ "Imported file _comma.dbc starts";
CM_ "Imported file _comma.dbc starts 
CM_ "Imported file _comma.dbc starts ";
CM_ "Imported file _comma.dbc starts h
CM_ "Imported file _comma.dbc start";
CM_ "Imported file _comma.dbc starts
CM_ "Imported file _comma.dbc start";
CM_ "Imported file _comma.dbc starts
CM_ "Imported file _comma.dbc starts";
CM_ "Imported file _comma.dbc starts 
CM_ "Imported file _comma.dbc starts ";
CM_ "Imported file _comma.dbc starts h
CM_ "Imported file _comma.dbc starts";
CM_ "Imported file _comma.dbc starts 
CM_ "Imported file _comma.dbc starts ";
CM_ "Imported file _comma.dbc starts h
CM_ "Imported file _comma.dbc starts ";
CM_ "Imported file _comma.dbc starts h
CM_ "Imported file _comma.dbc starts h";
CM_ "Imported file _comma.dbc starts he
CM_ "Imported file _comma.dbc star";
CM_ "Imported file _comma.dbc start
CM_ "Imported file _comma.dbc start";
CM_ "Imported file _comma.dbc starts
CM_ "Imported file _comma.dbc star";
CM_ "Imported file _comma.dbc start
CM_ "Imported file _comma.dbc start";
CM_ "Imported file _comma.dbc starts
CM_ "Imported file _comma.dbc start";
CM_ "Imported file _comma.dbc starts
CM_ "Imported file _comma.dbc start";
CM_ "Imported file _comma.dbc starts
CM_ "Imported file _comma.dbc starts";
CM_ "Imported file _comma.dbc starts 
CM_ "Imported file _comma.dbc starts ";
CM_ "Imported file _comma.dbc starts h
CM_ "Imported file _comma.dbc start";
CM_ "Imported file _comma.dbc starts
CM_ "Imported file _comma.dbc start";
CM_ "Imported file _comma.dbc starts
CM_ "Imported file _comma.dbc starts";
CM_ "Imported file _comma.dbc starts 
CM_ "Imported file _comma.dbc starts ";
CM_ "Imported file _comma.dbc starts h
CM_ "Imported file _comma.dbc starts";
CM_ "Imported file _comma.dbc starts 
CM_ "Imported file _comma.dbc starts ";
CM_ "Imported file _comma.dbc starts h
CM_ "Imported file _comma.dbc starts ";
CM_ "Imported file _comma.dbc starts h
CM_ "Imported file _comma.dbc starts h";
CM_ "Imported file _comma.dbc starts he
CM_ "Imported file _comma.dbc start";
CM_ "Imported file _comma.dbc starts
CM_ "Imported file _comma.dbc start";
CM_ "Imported file _comma.dbc starts
CM_ "Imported file _comma.dbc starts";
CM_ "Imported file _comma.dbc starts 
CM_ "Imported file _comma.dbc starts ";
CM_ "Imported file _comma.dbc starts h
CM_ "Imported file _comma.dbc starts";
CM_ "Imported file _comma.dbc starts 
CM_ "Imported file _comma.dbc starts ";
CM_ "Imported file _comma.dbc starts h
CM_ "Imported file _comma.dbc starts ";
CM_ "Imported file _comma.dbc starts h
CM_ "Imported file _comma.dbc starts h";
CM_ "Imported file _comma.dbc starts he
CM_ "Imported file _comma.dbc starts";
CM_ "Imported file _comma.dbc starts 
CM_ "Imported file _comma.dbc starts ";
CM_ "Imported file _comma.dbc starts h
CM_ "Imported file _comma.dbc starts ";
CM_ "Imported file _comma.dbc starts h
CM_ "Imported file _comma.dbc starts h";
CM_ "Imported file _comma.dbc starts he
CM_ "Imported file _comma.dbc starts ";
CM_ "Imported file _comma.dbc starts h
CM_ "Imported file _comma.dbc starts h";
CM_ "Imported file _comma.dbc starts he
CM_ "Imported file _comma.dbc starts h";
CM_ "Imported file _comma.dbc starts he
CM_ "Imported file _comma.dbc starts he";
CM_ "Imported file _comma.dbc starts her
CM_ "Imported file _comma.dbc st";
CM_ "Imported file _comma.dbc sta
CM_ "Imported file _comma.dbc sta";
CM_ "Imported file _comma.dbc star
CM_ "Imported file _comma.dbc sta";
CM_ "Imported file _comma.dbc star
CM_ "Imported file _comma.dbc star";
CM_ "Imported file _comma.dbc start
CM_ "Imported file _comma.dbc sta";
CM_ "Imported file _comma.dbc star
CM_ "Imported file _comma.dbc star";
CM_ "Imported file _comma.dbc start
CM_ "Imported file _comma.dbc star";
CM_ "Imported file _comma.dbc start
CM_ "Imported file _comma.dbc start";
CM_ "Imported file _comma.dbc starts
CM_ "Imported file _comma.dbc st";
CM_ "Imported file _comma.dbc sta
CM_ "Imported file _comma.dbc sta";
CM_ "Imported file _comma.dbc star
CM_ "Imported file _comma.dbc sta";
CM_ "Imported file _comma.dbc star
CM_ "Imported file _comma.dbc star";
CM_ "Imported file _comma.dbc start
CM_ "Imported file _comma.dbc sta";
CM_ "Imported file _comma.dbc star
CM_ "Imported file _comma.dbc star";
CM_ "Imported file _comma.dbc start
CM_ "Imported file _comma.dbc star";
CM_ "Imported file _comma.dbc start
CM_ "Imported file _comma.dbc start";
CM_ "Imported file _comma.dbc starts
CM_ "Imported file _comma.dbc sta";
CM_ "Imported file _comma.dbc star
CM_ "Imported file _comma.dbc star";
CM_ "Imported file _comma.dbc start
CM_ "Imported file _comma.dbc star";
CM_ "Imported file _comma.dbc start
CM_ "Imported file _comma.dbc start";
CM_ "Imported file _comma.dbc starts
CM_ "Imported file _comma.dbc sta";
CM_ "Imported file _comma.dbc star
CM_ "Imported file _comma.dbc star";
CM_ "Imported file _comma.dbc start
CM_ "Imported file _comma.dbc star";
CM_ "Imported file _comma.dbc start
CM_ "Imported file _comma.dbc start";
CM_ "Imported file _comma.dbc starts
CM_ "Imported file _comma.dbc star";
CM_ "Imported file _comma.dbc start
CM_ "Imported file _comma.dbc start";
CM_ "Imported file _comma.dbc starts
CM_ "Imported file _comma.dbc star";
CM_ "Imported file _comma.dbc start
CM_ "Imported file _comma.dbc start";
CM_ "Imported file _comma.dbc starts
CM_ "Imported file _comma.dbc start";
CM_ "Imported file _comma.dbc starts
CM_ "Imported file _comma.dbc start";
CM_ "Imported file _comma.dbc starts
CM_ "Imported file _comma.dbc starts";
CM_ "Imported file _comma.dbc starts 
CM_ "Imported file _comma.dbc starts ";
CM_ "Imported file _comma.dbc starts h
CM_ "Imported file _comma.dbc sta";
CM_ "Imported file _comma.dbc star
CM_ "Imported file _comma.dbc star";
CM_ "Imported file _comma.dbc start
CM_ "Imported file _comma.dbc star";
CM_ "Imported file _comma.dbc start
CM_ "Imported file _comma.dbc start";
CM_ "Imported file _comma.dbc starts
CM_ "Imported file _comma.dbc sta";
CM_ "Imported file _comma.dbc star
CM_ "Imported file _comma.dbc star";
CM_ "Imported file _comma.dbc start
CM_ "Imported file _comma.dbc star";
CM_ "Imported file _comma.dbc start
CM_ "Imported file _comma.dbc start";
CM_ "Imported file _comma.dbc starts
CM_ "Imported file _comma.dbc star";
CM_ "Imported file _comma.dbc start
CM_ "Imported file _comma.dbc start";
CM_ "Imported file _comma.dbc starts
CM_ "Imported file _comma.dbc star";
CM_ "Imported file _comma.dbc start
CM_ "Imported file _comma.dbc start";
CM_ "Imported file _comma.dbc starts
CM_ "Imported file _comma.dbc start";
CM_ "Imported file _comma.dbc starts
CM_ "Imported file _comma.dbc start";
CM_ "Imported file _comma.dbc starts
CM_ "Imported file _comma.dbc starts";
CM_ "Imported file _comma.dbc starts 
CM_ "Imported file _comma.dbc starts ";
CM_ "Imported file _comma.dbc starts h
CM_ "Imported file _comma.dbc star";
CM_ "Imported file _comma.dbc start
CM_ "Imported file _comma.dbc start";
CM_ "Imported file _comma.dbc starts
CM_ "Imported file _comma.dbc star";
CM_ "Imported file _comma.dbc start
CM_ "Imported file _comma.dbc start";
CM_ "Imported file _comma.dbc starts
CM_ "Imported file _comma.dbc start";
CM_ "Imported file _comma.dbc starts
CM_ "Imported file _comma.dbc start";
CM_ "Imported file _comma.dbc starts
CM_ "Imported file _comma.dbc starts";
CM_ "Imported file _comma.dbc starts 
CM_ "Imported file _comma.dbc starts ";
CM_ "Imported file _comma.dbc starts h
CM_ "Imported file _comma.dbc start";
CM_ "Imported file _comma.dbc starts
CM_ "Imported file _comma.dbc start";
CM_ "Imported file _comma.dbc starts
CM_ "Imported file _comma.dbc starts";
CM_ "Imported file _comma.dbc starts 
CM_ "Imported file _comma.dbc starts ";
CM_ "Imported file _comma.dbc starts h
CM_ "Imported file _comma.dbc starts";
CM_ "Imported file _comma.dbc starts 
CM_ "Imported file _comma.dbc starts ";
CM_ "Imported file _comma.dbc starts h
CM_ "Imported file _comma.dbc starts ";
CM_ "Imported file _comma.dbc starts h
CM_ "Imported file _comma.dbc starts h";
CM_ "Imported file _comma.dbc starts he
CM_ "Imported file _comma.dbc sta";
CM_ "Imported file _comma.dbc star
CM_ "Imported file _comma.dbc star";
CM_ "Imported file _comma.dbc start
CM_ "Imported file _comma.dbc star";
CM_ "Imported file _comma.dbc start
CM_ "Imported file _comma.dbc start";
CM_ "Imported file _comma.dbc starts
CM_ "Imported file _comma.dbc sta";
CM_ "Imported file _comma.dbc star
CM_ "Imported file _comma.dbc star";
CM_ "Imported file _comma.dbc start
CM_ "Imported file _comma.dbc star";
CM_ "Imported file _comma.dbc start
CM_ "Imported file _comma.dbc start";
CM_ "Imported file _comma.dbc starts
CM_ "Imported file _comma.dbc star";
CM_ "Imported file _comma.dbc start
CM_ "Imported file _comma.dbc start";
CM_ "Imported file _comma.dbc starts
CM_ "Imported file _comma.dbc star";
CM_ "Imported file _comma.dbc start
CM_ "Imported file _comma.dbc start";
CM_ "Imported file _comma.dbc starts
CM_ "Imported file _comma.dbc start";
CM_ "Imported file _comma.dbc starts
CM_ "Imported file _comma.dbc start";
CM_ "Imported file _comma.dbc starts
CM_ "Imported file _comma.dbc starts";
CM_ "Imported file _comma.dbc starts 
CM_ "Imported file _comma.dbc starts ";
CM_ "Imported file _comma.dbc starts h
CM_ "Imported file _comma.dbc star";
CM_ "Imported file _comma.dbc start
CM_ "Imported file _comma.dbc start";
CM_ "Imported file _comma.dbc starts
CM_ "Imported file _comma.dbc star";
CM_ "Imported file _comma.dbc start
CM_ "Imported file _comma.dbc start";
CM_ "Imported file _comma.dbc starts
CM_ "Imported file _comma.dbc start";
CM_ "Imported file _comma.dbc starts
CM_ "Imported file _comma.dbc start";
CM_ "Imported file _comma.dbc starts
CM_ "Imported file _comma.dbc starts";
CM_ "Imported file _comma.dbc starts 
CM_ "Imported file _comma.dbc starts ";
CM_ "Imported file _comma.dbc starts h
CM_ "Imported file _comma.dbc start";
CM_ "Imported file _comma.dbc starts
CM_ "Imported file _comma.dbc start";
CM_ "Imported file _comma.dbc starts
CM_ "Imported file _comma.dbc starts";
CM_ "Imported file _comma.dbc starts 
CM_ "Imported file _comma.dbc starts ";
CM_ "Imported file _comma.dbc starts h
CM_ "Imported file _comma.dbc starts";
CM_ "Imported file _comma.dbc starts 
CM_ "Imported file _comma.dbc starts ";
CM_ "Imported file _comma.dbc starts h
CM_ "Imported file _comma.dbc starts ";
CM_ "Imported file _comma.dbc starts h
CM_ "Imported file _comma.dbc starts h";
CM_ "Imported file _comma.dbc starts he
CM_ "Imported file _comma.dbc star";
CM_ "Imported file _comma.dbc start
CM_ "Imported file _comma.dbc start";
CM_ "Imported file _comma.dbc starts
CM_ "Imported file _comma.dbc star";
CM_ "Imported file _comma.dbc start
CM_ "Imported file _comma.dbc start";
CM_ "Imported file _comma.dbc starts
CM_ "Imported file _comma.dbc start";
CM_ "Imported file _comma.dbc starts
CM_ "Imported file _comma.dbc start";
CM_ "Imported file _comma.dbc starts
CM_ "Imported file _comma.dbc starts";
CM_ "Imported file _comma.dbc starts 
CM_ "Imported file _comma.dbc starts ";
CM_ "Imported file _comma.dbc starts h
CM_ "Imported file _comma.dbc start";
CM_ "Imported file _comma.dbc starts
CM_ "Imported file _comma.dbc start";
CM_ "Imported file _comma.dbc starts
CM_ "Imported file _comma.dbc starts";
CM_ "Imported file _comma.dbc starts 
CM_ "Imported file _comma.dbc starts ";
CM_ "Imported file _comma.dbc starts h
CM_ "Imported file _comma.dbc starts";
CM_ "Imported file _comma.dbc starts 
CM_ "Imported file _comma.dbc starts ";
CM_ "Imported file _comma.dbc starts h
CM_ "Imported file _comma.dbc starts ";
CM_ "Imported file _comma.dbc starts h
CM_ "Imported file _comma.dbc starts h";
CM_ "Imported file _comma.dbc starts he
CM_ "Imported file _comma.dbc start";
CM_ "Imported file _comma.dbc starts
CM_ "Imported file _comma.dbc start";
CM_ "Imported file _comma.dbc starts
CM_ "Imported file _comma.dbc starts";
CM_ "Imported file _comma.dbc starts 
CM_ "Imported file _comma.dbc starts ";
CM_ "Imported file _comma.dbc starts h
CM_ "Imported file _comma.dbc starts";
CM_ "Imported file _comma.dbc starts 
CM_ "Imported file _comma.dbc starts ";
CM_ "Imported file _comma.dbc starts h
CM_ "Imported file _comma.dbc starts ";
CM_ "Imported file _comma.dbc starts h
CM_ "Imported file _comma.dbc starts h";
CM_ "Imported file _comma.dbc starts he
CM_ "Imported file _comma.dbc starts";
CM_ "Imported file _comma.dbc starts 
CM_ "Imported file _comma.dbc starts ";
CM_ "Imported file _comma.dbc starts h
CM_ "Imported file _comma.dbc starts ";
CM_ "Imported file _comma.dbc starts h
CM_ "Imported file _comma.dbc starts h";
CM_ "Imported file _comma.dbc starts he
CM_ "Imported file _comma.dbc starts ";
CM_ "Imported file _comma.dbc starts h
CM_ "Imported file _comma.dbc starts h";
CM_ "Imported file _comma.dbc starts he
CM_ "Imported file _comma.dbc starts h";
CM_ "Imported file _comma.dbc starts he
CM_ "Imported file _comma.dbc starts he";
CM_ "Imported file _comma.dbc starts her
CM_ "Imported file _comma.dbc sta";
CM_ "Imported file _comma.dbc star
CM_ "Imported file _comma.dbc star";
CM_ "Imported file _comma.dbc start
CM_ "Imported file _comma.dbc star";
CM_ "Imported file _comma.dbc start
CM_ "Imported file _comma.dbc start";
CM_ "Imported file _comma.dbc starts
CM_ "Imported file _comma.dbc sta";
CM_ "Imported file _comma.dbc star
CM_ "Imported file _comma.dbc star";
CM_ "Imported file _comma.dbc start
CM_ "Imported file _comma.dbc star";
CM_ "Imported file _comma.dbc start
CM_ "Imported file _comma.dbc start";
CM_ "Imported file _comma.dbc starts
CM_ "Imported file _comma.dbc star";
CM_ "Imported file _comma.dbc start
CM_ "Imported file _comma.dbc start";
CM_ "Imported file _comma.dbc starts
CM_ "Imported file _comma.dbc star";
CM_ "Imported file _comma.dbc start
CM_ "Imported file _comma.dbc start";
CM_ "Imported file _comma.dbc starts
CM_ "Imported file _comma.dbc start";
CM_ "Imported file _comma.dbc starts
CM_ "Imported file _comma.dbc start";
CM_ "Imported file _comma.dbc starts
CM_ "Imported file _comma.dbc starts";
CM_ "Imported file _comma.dbc starts 
CM_ "Imported file _comma.dbc starts ";
CM_ "Imported file _comma.dbc starts h
CM_ "Imported file _comma.dbc star";
CM_ "Imported file _comma.dbc start
CM_ "Imported file _comma.dbc start";
CM_ "Imported file _comma.dbc starts
CM_ "Imported file _comma.dbc star";
CM_ "Imported file _comma.dbc start
CM_ "Imported file _comma.dbc start";
CM_ "Imported file _comma.dbc starts
CM_ "Imported file _comma.dbc start";
CM_ "Imported file _comma.dbc starts
CM_ "Imported file _comma.dbc start";
CM_ "Imported file _comma.dbc starts
CM_ "Imported file _comma.dbc starts";
CM_ "Imported file _comma.dbc starts 
CM_ "Imported file _comma.dbc starts ";
CM_ "Imported file _comma.dbc starts h
CM_ "Imported file _comma.dbc start";
CM_ "Imported file _comma.dbc starts
CM_ "Imported file _comma.dbc start";
CM_ "Imported file _comma.dbc starts
CM_ "Imported file _comma.dbc starts";
CM_ "Imported file _comma.dbc starts 
CM_ "Imported file _comma.dbc starts ";
CM_ "Imported file _comma.dbc starts h
CM_ "Imported file _comma.dbc starts";
CM_ "Imported file _comma.dbc starts 
CM_ "Imported file _comma.dbc starts ";
CM_ "Imported file _comma.dbc starts h
CM_ "Imported file _comma.dbc starts ";
CM_ "Imported file _comma.dbc starts h
CM_ "Imported file _comma.dbc starts h";
CM_ "Imported file _comma.dbc starts he
CM_ "Imported file _comma.dbc star";
CM_ "Imported file _comma.dbc start
CM_ "Imported file _comma.dbc start";
CM_ "Imported file _comma.dbc starts
CM_ "Imported file _comma.dbc star";
CM_ "Imported file _comma.dbc start
CM_ "Imported file _comma.dbc start";
CM_ "Imported file _comma.dbc starts
CM_ "Imported file _comma.dbc start";
CM_ "Imported file _comma.dbc starts
CM_ "Imported file _comma.dbc start";
CM_ "Imported file _comma.dbc starts
CM_ "Imported file _comma.dbc starts";
CM_ "Imported file _comma.dbc starts 
CM_ "Imported file _comma.dbc starts ";
CM_ "Imported file _comma.dbc starts h
CM_ "Imported file _comma.dbc start";
CM_ "Imported file _comma.dbc starts
CM_ "Imported file _comma.dbc start";
CM_ "Imported file _comma.dbc starts
CM_ "Imported file _comma.dbc starts";
CM_ "Imported file _comma.dbc starts 
CM_ "Imported file _comma.dbc starts ";
CM_ "Imported file _comma.dbc starts h
CM_ "Imported file _comma.dbc starts";
CM_ "Imported file _comma.dbc starts 
CM_ "Imported file _comma.dbc starts ";
CM_ "Imported file _comma.dbc starts h
CM_ "Imported file _comma.dbc starts ";
CM_ "Imported file _comma.dbc starts h
CM_ "Imported file _comma.dbc starts h";
CM_ "Imported file _comma.dbc starts he
CM_ "Imported file _comma.dbc start";
CM_ "Imported file _comma.dbc starts
CM_ "Imported file _comma.dbc start";
CM_ "Imported file _comma.dbc starts
CM_ "Imported file _comma.dbc starts";
CM_ "Imported file _comma.dbc starts 
CM_ "Imported file _comma.dbc starts ";
CM_ "Imported file _comma.dbc starts h
CM_ "Imported file _comma.dbc starts";
CM_ "Imported file _comma.dbc starts 
CM_ "Imported file _comma.dbc starts ";
CM_ "Imported file _comma.dbc starts h
CM_ "Imported file _comma.dbc starts ";
CM_ "Imported file _comma.dbc starts h
CM_ "Imported file _comma.dbc starts h";
CM_ "Imported file _comma.dbc starts he
CM_ "Imported file _comma.dbc starts";
CM_ "Imported file _comma.dbc starts 
CM_ "Imported file _comma.dbc starts ";
CM_ "Imported file _comma.dbc starts h
CM_ "Imported file _comma.dbc starts ";
CM_ "Imported file _comma.dbc starts h
CM_ "Imported file _comma.dbc starts h";
CM_ "Imported file _comma.dbc starts he
CM_ "Imported file _comma.dbc starts ";
CM_ "Imported file _comma.dbc starts h
CM_ "Imported file _comma.dbc starts h";
CM_ "Imported file _comma.dbc starts he
CM_ "Imported file _comma.dbc starts h";
CM_ "Imported file _comma.dbc starts he
CM_ "Imported file _comma.dbc starts he";
CM_ "Imported file _comma.dbc starts her
CM_ "Imported file _comma.dbc star";
CM_ "Imported file _comma.dbc start
CM_ "Imported file _comma.dbc start";
CM_ "Imported file _comma.dbc starts
CM_ "Imported file _comma.dbc star";
CM_ "Imported file _comma.dbc start
CM_ "Imported file _comma.dbc start";
CM_ "Imported file _comma.dbc starts
CM_ "Imported file _comma.dbc start";
CM_ "Imported file _comma.dbc starts
CM_ "Imported file _comma.dbc start";
CM_ "Imported file _comma.dbc starts
CM_ "Imported file _comma.dbc starts";
CM_ "Imported file _comma.dbc starts 
CM_ "Imported file _comma.dbc starts ";
CM_ "Imported file _comma.dbc starts h
CM_ "Imported file _comma.dbc start";
CM_ "Imported file _comma.dbc starts
CM_ "Imported file _comma.dbc start";
CM_ "Imported file _comma.dbc starts
CM_ "Imported file _comma.dbc starts";
CM_ "Imported file _comma.dbc starts 
CM_ "Imported file _comma.dbc starts ";
CM_ "Imported file _comma.dbc starts h
CM_ "Imported file _comma.dbc starts";
CM_ "Imported file _comma.dbc starts 
CM_ "Imported file _comma.dbc starts ";
CM_ "Imported file _comma.dbc starts h
CM_ "Imported file _comma.dbc starts ";
CM_ "Imported file _comma.dbc starts h
CM_ "Imported file _comma.dbc starts h";
CM_ "Imported file _comma.dbc starts he
CM_ "Imported file _comma.dbc start";
CM_ "Imported file _comma.dbc starts
CM_ "Imported file _comma.dbc start";
CM_ "Imported file _comma.dbc starts
CM_ "Imported file _comma.dbc starts";
CM_ "Imported file _comma.dbc starts 
CM_ "Imported file _comma.dbc starts ";
CM_ "Imported file _comma.dbc starts h
CM_ "Imported file _comma.dbc starts";
CM_ "Imported file _comma.dbc starts 
CM_ "Imported file _comma.dbc starts ";
CM_ "Imported file _comma.dbc starts h
CM_ "Imported file _comma.dbc starts ";
CM_ "Imported file _comma.dbc starts h
CM_ "Imported file _comma.dbc starts h";
CM_ "Imported file _comma.dbc starts he
CM_ "Imported file _comma.dbc starts";
CM_ "Imported file _comma.dbc starts 
CM_ "Imported file _comma.dbc starts ";
CM_ "Imported file _comma.dbc starts h
CM_ "Imported file _comma.dbc starts ";
CM_ "Imported file _comma.dbc starts h
CM_ "Imported file _comma.dbc starts h";
CM_ "Imported file _comma.dbc starts he
CM_ "Imported file _comma.dbc starts ";
CM_ "Imported file _comma.dbc starts h
CM_ "Imported file _comma.dbc starts h";
CM_ "Imported file _comma.dbc starts he
CM_ "Imported file _comma.dbc starts h";
CM_ "Imported file _comma.dbc starts he
CM_ "Imported file _comma.dbc starts he";
CM_ "Imported file _comma.dbc starts her
CM_ "Imported file _comma.dbc start";
CM_ "Imported file _comma.dbc starts
CM_ "Imported file _comma.dbc start";
CM_ "Imported file _comma.dbc starts
CM_ "Imported file _comma.dbc starts";
CM_ "Imported file _comma.dbc starts 
CM_ "Imported file _comma.dbc starts ";
CM_ "Imported file _comma.dbc starts h
CM_ "Imported file _comma.dbc starts";
CM_ "Imported file _comma.dbc starts 
CM_ "Imported file _comma.dbc starts ";
CM_ "Imported file _comma.dbc starts h
CM_ "Imported file _comma.dbc starts ";
CM_ "Imported file _comma.dbc starts h
CM_ "Imported file _comma.dbc starts h";
CM_ "Imported file _comma.dbc starts he
CM_ "Imported file _comma.dbc starts";
CM_ "Imported file _comma.dbc starts 
CM_ "Imported file _comma.dbc starts ";
CM_ "Imported file _comma.dbc starts h
CM_ "Imported file _comma.dbc starts ";
CM_ "Imported file _comma.dbc starts h
CM_ "Imported file _comma.dbc starts h";
CM_ "Imported file _comma.dbc starts he
CM_ "Imported file _comma.dbc starts ";
CM_ "Imported file _comma.dbc starts h
CM_ "Imported file _comma.dbc starts h";
CM_ "Imported file _comma.dbc starts he
CM_ "Imported file _comma.dbc starts h";
CM_ "Imported file _comma.dbc starts he
CM_ "Imported file _comma.dbc starts he";
CM_ "Imported file _comma.dbc starts her
CM_ "Imported file _comma.dbc starts";
CM_ "Imported file _comma.dbc starts 
CM_ "Imported file _comma.dbc starts ";
CM_ "Imported file _comma.dbc starts h
CM_ "Imported file _comma.dbc starts ";
CM_ "Imported file _comma.dbc starts h
CM_ "Imported file _comma.dbc starts h";
CM_ "Imported file _comma.dbc starts he
CM_ "Imported file _comma.dbc starts ";
CM_ "Imported file _comma.dbc starts h
CM_ "Imported file _comma.dbc starts h";
CM_ "Imported file _comma.dbc starts he
CM_ "Imported file _comma.dbc starts h";
CM_ "Imported file _comma.dbc starts he
CM_ "Imported file _comma.dbc starts he";
CM_ "Imported file _comma.dbc starts her
CM_ "Imported file _comma.dbc starts ";
CM_ "Imported file _comma.dbc starts h
CM_ "Imported file _comma.dbc starts h";
CM_ "Imported file _comma.dbc starts he
CM_ "Imported file _comma.dbc starts h";
CM_ "Imported file _comma.dbc starts he
CM_ "Imported file _comma.dbc starts he";
CM_ "Imported file _comma.dbc starts her
CM_ "Imported file _comma.dbc starts h";
CM_ "Imported file _comma.dbc starts he
CM_ "Imported file _comma.dbc starts he";
CM_ "Imported file _comma.dbc starts her
CM_ "Imported file _comma.dbc starts he";
CM_ "Imported file _comma.dbc starts her
CM_ "Imported file _comma.dbc starts her";
CM_ "Imported file _comma.dbc starts here
CM_ "Imported file _comma.dbc st";
CM_ "Imported file _comma.dbc sta
CM_ "Imported file _comma.dbc sta";
CM_ "Imported file _comma.dbc star
CM_ "Imported file _comma.dbc sta";
CM_ "Imported file _comma.dbc star
CM_ "Imported file _comma.dbc star";
CM_ "Imported file _comma.dbc start
CM_ "Imported file _comma.dbc sta";
CM_ "Imported file _comma.dbc star
CM_ "Imported file _comma.dbc star";
CM_ "Imported file _comma.dbc start
CM_ "Imported file _comma.dbc star";
CM_ "Imported file _comma.dbc start
CM_ "Imported file _comma.dbc start";
CM_ "Imported file _comma.dbc starts
CM_ "Imported file _comma.dbc st";
CM_ "Imported file _comma.dbc sta
CM_ "Imported file _comma.dbc sta";
CM_ "Imported file _comma.dbc star
CM_ "Imported file _comma.dbc sta";
CM_ "Imported file _comma.dbc star
CM_ "Imported file _comma.dbc star";
CM_ "Imported file _comma.dbc start
CM_ "Imported file _comma.dbc sta";
CM_ "Imported file _comma.dbc star
CM_ "Imported file _comma.dbc star";
CM_ "Imported file _comma.dbc start
CM_ "Imported file _comma.dbc star";
CM_ "Imported file _comma.dbc start
CM_ "Imported file _comma.dbc start";
CM_ "Imported file _comma.dbc starts
CM_ "Imported file _comma.dbc sta";
CM_ "Imported file _comma.dbc star
CM_ "Imported file _comma.dbc star";
CM_ "Imported file _comma.dbc start
CM_ "Imported file _comma.dbc star";
CM_ "Imported file _comma.dbc start
CM_ "Imported file _comma.dbc start";
CM_ "Imported file _comma.dbc starts
CM_ "Imported file _comma.dbc sta";
CM_ "Imported file _comma.dbc star
CM_ "Imported file _comma.dbc star";
CM_ "Imported file _comma.dbc start
CM_ "Imported file _comma.dbc star";
CM_ "Imported file _comma.dbc start
CM_ "Imported file _comma.dbc start";
CM_ "Imported file _comma.dbc starts
CM_ "Imported file _comma.dbc star";
CM_ "Imported file _comma.dbc start
CM_ "Imported file _comma.dbc start";
CM_ "Imported file _comma.dbc starts
CM_ "Imported file _comma.dbc star";
CM_ "Imported file _comma.dbc start
CM_ "Imported file _comma.dbc start";
CM_ "Imported file _comma.dbc starts
CM_ "Imported file _comma.dbc start";
CM_ "Imported file _comma.dbc starts
CM_ "Imported file _comma.dbc start";
CM_ "Imported file _comma.dbc starts
CM_ "Imported file _comma.dbc starts";
CM_ "Imported file _comma.dbc starts 
CM_ "Imported file _comma.dbc starts ";
CM_ "Imported file _comma.dbc starts h
CM_ "Imported file _comma.dbc sta";
CM_ "Imported file _comma.dbc star
CM_ "Imported file _comma.dbc star";
CM_ "Imported file _comma.dbc start
CM_ "Imported file _comma.dbc star";
CM_ "Imported file _comma.dbc start
CM_ "Imported file _comma.dbc start";
CM_ "Imported file _comma.dbc starts
CM_ "Imported file _comma.dbc sta";
CM_ "Imported file _comma.dbc star
CM_ "Imported file _comma.dbc star";
CM_ "Imported file _comma.dbc start
CM_ "Imported file _comma.dbc star";
CM_ "Imported file _comma.dbc start
CM_ "Imported file _comma.dbc start";
CM_ "Imported file _comma.dbc starts
CM_ "Imported file _comma.dbc star";
CM_ "Imported file _comma.dbc start
CM_ "Imported file _comma.dbc start";
CM_ "Imported file _comma.dbc starts
CM_ "Imported file _comma.dbc star";
CM_ "Imported file _comma.dbc start
CM_ "Imported file _comma.dbc start";
CM_ "Imported file _comma.dbc starts
CM_ "Imported file _comma.dbc start";
CM_ "Imported file _comma.dbc starts
CM_ "Imported file _comma.dbc start";
CM_ "Imported file _comma.dbc starts
CM_ "Imported file _comma.dbc starts";
CM_ "Imported file _comma.dbc starts 
CM_ "Imported file _comma.dbc starts ";
CM_ "Imported file _comma.dbc starts h
CM_ "Imported file _comma.dbc star";
CM_ "Imported file _comma.dbc start
CM_ "Imported file _comma.dbc start";
CM_ "Imported file _comma.dbc starts
CM_ "Imported file _comma.dbc star";
CM_ "Imported file _comma.dbc start
CM_ "Imported file _comma.dbc start";
CM_ "Imported file _comma.dbc starts
CM_ "Imported file _comma.dbc start";
CM_ "Imported file _comma.dbc starts
CM_ "Imported file _comma.dbc start";
CM_ "Imported file _comma.dbc starts
CM_ "Imported file _comma.dbc starts";
CM_ "Imported file _comma.dbc starts 
CM_ "Imported file _comma.dbc starts ";
CM_ "Imported file _comma.dbc starts h
CM_ "Imported file _comma.dbc start";
CM_ "Imported file _comma.dbc starts
CM_ "Imported file _comma.dbc start";
CM_ "Imported file _comma.dbc starts
CM_ "Imported file _comma.dbc starts";
CM_ "Imported file _comma.dbc starts 
CM_ "Imported file _comma.dbc starts ";
CM_ "Imported file _comma.dbc starts h
CM_ "Imported file _comma.dbc starts";
CM_ "Imported file _comma.dbc starts 
CM_ "Imported file _comma.dbc starts ";
CM_ "Imported file _comma.dbc starts h
CM_ "Imported file _comma.dbc starts ";
CM_ "Imported file _comma.dbc starts h
CM_ "Imported file _comma.dbc starts h";
CM_ "Imported file _comma.dbc starts he
CM_ "Imported file _comma.dbc sta";
CM_ "Imported file _comma.dbc star
CM_ "Imported file _comma.dbc star";
CM_ "Imported file _comma.dbc start
CM_ "Imported file _comma.dbc star";
CM_ "Imported file _comma.dbc start
CM_ "Imported file _comma.dbc start";
CM_ "Imported file _comma.dbc starts
CM_ "Imported file _comma.dbc sta";
CM_ "Imported file _comma.dbc star
CM_ "Imported file _comma.dbc star";
CM_ "Imported file _comma.dbc start
CM_ "Imported file _comma.dbc star";
CM_ "Imported file _comma.dbc start
CM_ "Imported file _comma.dbc start";
CM_ "Imported file _comma.dbc starts
CM_ "Imported file _comma.dbc star";
CM_ "Imported file _comma.dbc start
CM_ "Imported file _comma.dbc start";
CM_ "Imported file _comma.dbc starts
CM_ "Imported file _comma.dbc star";
CM_ "Imported file _comma.dbc start
CM_ "Imported file _comma.dbc start";
CM_ "Imported file _comma.dbc starts
CM_ "Imported file _comma.dbc start";
CM_ "Imported file _comma.dbc starts
CM_ "Imported file _comma.dbc start";
CM_ "Imported file _comma.dbc starts
CM_ "Imported file _comma.dbc starts";
CM_ "Imported file _comma.dbc starts 
CM_ "Imported file _comma.dbc starts ";
CM_ "Imported file _comma.dbc starts h
CM_ "Imported file _comma.dbc star";
CM_ "Imported file _comma.dbc start
CM_ "Imported file _comma.dbc start";
CM_ "Imported file _comma.dbc starts
CM_ "Imported file _comma.dbc star";
CM_ "Imported file _comma.dbc start
CM_ "Imported file _comma.dbc start";
CM_ "Imported file _comma.dbc starts
CM_ "Imported file _comma.dbc start";
CM_ "Imported file _comma.dbc starts
CM_ "Imported file _comma.dbc start";
CM_ "Imported file _comma.dbc starts
CM_ "Imported file _comma.dbc starts";
CM_ "Imported file _comma.dbc starts 
CM_ "Imported file _comma.dbc starts ";
CM_ "Imported file _comma.dbc starts h
CM_ "Imported file _comma.dbc start";
CM_ "Imported file _comma.dbc starts
CM_ "Imported file _comma.dbc start";
CM_ "Imported file _comma.dbc starts
CM_ "Imported file _comma.dbc starts";
CM_ "Imported file _comma.dbc starts 
CM_ "Imported file _comma.dbc starts ";
CM_ "Imported file _comma.dbc starts h
CM_ "Imported file _comma.dbc starts";
CM_ "Imported file _comma.dbc starts 
CM_ "Imported file _comma.dbc starts ";
CM_ "Imported file _comma.dbc starts h
CM_ "Imported file _comma.dbc starts ";
CM_ "Imported file _comma.dbc starts h
CM_ "Imported file _comma.dbc starts h";
CM_ "Imported file _comma.dbc starts he
CM_ "Imported file _comma.dbc star";
CM_ "Imported file _comma.dbc start
CM_ "Imported file _comma.dbc start";
CM_ "Imported file _comma.dbc starts
CM_ "Imported file _comma.dbc star";
CM_ "Imported file _comma.dbc start
CM_ "Imported file _comma.dbc start";
CM_ "Imported file _comma.dbc starts
CM_ "Imported file _comma.dbc start";
CM_ "Imported file _comma.dbc starts
CM_ "Imported file _comma.dbc start";
CM_ "Imported file _comma.dbc starts
CM_ "Imported file _comma.dbc starts";
CM_ "Imported file _comma.dbc starts 
CM_ "Imported file _comma.dbc starts ";
CM_ "Imported file _comma.dbc starts h
CM_ "Imported file _comma.dbc start";
CM_ "Imported file _comma.dbc starts
CM_ "Imported file _comma.dbc start";
CM_ "Imported file _comma.dbc starts
CM_ "Imported file _comma.dbc starts";
CM_ "Imported file _comma.dbc starts 
CM_ "Imported file _comma.dbc starts ";
CM_ "Imported file _comma.dbc starts h
CM_ "Imported file _comma.dbc starts";
CM_ "Imported file _comma.dbc starts 
CM_ "Imported file _comma.dbc starts ";
CM_ "Imported file _comma.dbc starts h
CM_ "Imported file _comma.dbc starts ";
CM_ "Imported file _comma.dbc starts h
CM_ "Imported file _comma.dbc starts h";
CM_ "Imported file _comma.dbc starts he
CM_ "Imported file _comma.dbc start";
CM_ "Imported file _comma.dbc starts
CM_ "Imported file _comma.dbc start";
CM_ "Imported file _comma.dbc starts
CM_ "Imported file _comma.dbc starts";
CM_ "Imported file _comma.dbc starts 
CM_ "Imported file _comma.dbc starts ";
CM_ "Imported file _comma.dbc starts h
CM_ "Imported file _comma.dbc starts";
CM_ "Imported file _comma.dbc starts 
CM_ "Imported file _comma.dbc starts ";
CM_ "Imported file _comma.dbc starts h
CM_ "Imported file _comma.dbc starts ";
CM_ "Imported file _comma.dbc starts h
CM_ "Imported file _comma.dbc starts h";
CM_ "Imported file _comma.dbc starts he
CM_ "Imported file _comma.dbc starts";
CM_ "Imported file _comma.dbc starts 
CM_ "Imported file _comma.dbc starts ";
CM_ "Imported file _comma.dbc starts h
CM_ "Imported file _comma.dbc starts ";
CM_ "Imported file _comma.dbc starts h
CM_ "Imported file _comma.dbc starts h";
CM_ "Imported file _comma.dbc starts he
CM_ "Imported file _comma.dbc starts ";
CM_ "Imported file _comma.dbc starts h
CM_ "Imported file _comma.dbc starts h";
CM_ "Imported file _comma.dbc starts he
CM_ "Imported file _comma.dbc starts h";
CM_ "Imported file _comma.dbc starts he
CM_ "Imported file _comma.dbc starts he";
CM_ "Imported file _comma.dbc starts her
CM_ "Imported file _comma.dbc sta";
CM_ "Imported file _comma.dbc star
CM_ "Imported file _comma.dbc star";
CM_ "Imported file _comma.dbc start
CM_ "Imported file _comma.dbc star";
CM_ "Imported file _comma.dbc start
CM_ "Imported file _comma.dbc start";
CM_ "Imported file _comma.dbc starts
CM_ "Imported file _comma.dbc sta";
CM_ "Imported file _comma.dbc star
CM_ "Imported file _comma.dbc star";
CM_ "Imported file _comma.dbc start
CM_ "Imported file _comma.dbc star";
CM_ "Imported file _comma.dbc start
CM_ "Imported file _comma.dbc start";
CM_ "Imported file _comma.dbc starts
CM_ "Imported file _comma.dbc star";
CM_ "Imported file _comma.dbc start
CM_ "Imported file _comma.dbc start";
CM_ "Imported file _comma.dbc starts
CM_ "Imported file _comma.dbc star";
CM_ "Imported file _comma.dbc start
CM_ "Imported file _comma.dbc start";
CM_ "Imported file _comma.dbc starts
CM_ "Imported file _comma.dbc start";
CM_ "Imported file _comma.dbc starts
CM_ "Imported file _comma.dbc start";
CM_ "Imported file _comma.dbc starts
CM_ "Imported file _comma.dbc starts";
CM_ "Imported file _comma.dbc starts 
CM_ "Imported file _comma.dbc starts ";
CM_ "Imported file _comma.dbc starts h
CM_ "Imported file _comma.dbc star";
CM_ "Imported file _comma.dbc start
CM_ "Imported file _comma.dbc start";
CM_ "Imported file _comma.dbc starts
CM_ "Imported file _comma.dbc star";
CM_ "Imported file _comma.dbc start
CM_ "Imported file _comma.dbc start";
CM_ "Imported file _comma.dbc starts
CM_ "Imported file _comma.dbc start";
CM_ "Imported file _comma.dbc starts
CM_ "Imported file _comma.dbc start";
CM_ "Imported file _comma.dbc starts
CM_ "Imported file _comma.dbc starts";
CM_ "Imported file _comma.dbc starts 
CM_ "Imported file _comma.dbc starts ";
CM_ "Imported file _comma.dbc starts h
CM_ "Imported file _comma.dbc start";
CM_ "Imported file _comma.dbc starts
CM_ "Imported file _comma.dbc start";
CM_ "Imported file _comma.dbc starts
CM_ "Imported file _comma.dbc starts";
CM_ "Imported file _comma.dbc starts 
CM_ "Imported file _comma.dbc starts ";
CM_ "Imported file _comma.dbc starts h
CM_ "Imported file _comma.dbc starts";
CM_ "Imported file _comma.dbc starts 
CM_ "Imported file _comma.dbc starts ";
CM_ "Imported file _comma.dbc starts h
CM_ "Imported file _comma.dbc starts ";
CM_ "Imported file _comma.dbc starts h
CM_ "Imported file _comma.dbc starts h";
CM_ "Imported file _comma.dbc starts he
CM_ "Imported file _comma.dbc star";
CM_ "Imported file _comma.dbc start
CM_ "Imported file _comma.dbc start";
CM_ "Imported file _comma.dbc starts
CM_ "Imported file _comma.dbc star";
CM_ "Imported file _comma.dbc start
CM_ "Imported file _comma.dbc start";
CM_ "Imported file _comma.dbc starts
CM_ "Imported file _comma.dbc start";
CM_ "Imported file _comma.dbc starts
CM_ "Imported file _comma.dbc start";
CM_ "Imported file _comma.dbc starts
CM_ "Imported file _comma.dbc starts";
CM_ "Imported file _comma.dbc starts 
CM_ "Imported file _comma.dbc starts ";
CM_ "Imported file _comma.dbc starts h
CM_ "Imported file _comma.dbc start";
CM_ "Imported file _comma.dbc starts
CM_ "Imported file _comma.dbc start";
CM_ "Imported file _comma.dbc starts
CM_ "Imported file _comma.dbc starts";
CM_ "Imported file _comma.dbc starts 
CM_ "Imported file _comma.dbc starts ";
CM_ "Imported file _comma.dbc starts h
CM_ "Imported file _comma.dbc starts";
CM_ "Imported file _comma.dbc starts 
CM_ "Imported file _comma.dbc starts ";
CM_ "Imported file _comma.dbc starts h
CM_ "Imported file _comma.dbc starts ";
CM_ "Imported file _comma.dbc starts h
CM_ "Imported file _comma.dbc starts h";
CM_ "Imported file _comma.dbc starts he
CM_ "Imported file _comma.dbc start";
CM_ "Imported file _comma.dbc starts
CM_ "Imported file _comma.dbc start";
CM_ "Imported file _comma.dbc starts
CM_ "Imported file _comma.dbc starts";
CM_ "Imported file _comma.dbc starts 
CM_ "Imported file _comma.dbc starts ";
CM_ "Imported file _comma.dbc starts h
CM_ "Imported file _comma.dbc starts";
CM_ "Imported file _comma.dbc starts 
CM_ "Imported file _comma.dbc starts ";
CM_ "Imported file _comma.dbc starts h
CM_ "Imported file _comma.dbc starts ";
CM_ "Imported file _comma.dbc starts h
CM_ "Imported file _comma.dbc starts h";
CM_ "Imported file _comma.dbc starts he
CM_ "Imported file _comma.dbc starts";
CM_ "Imported file _comma.dbc starts 
CM_ "Imported file _comma.dbc starts ";
CM_ "Imported file _comma.dbc starts h
CM_ "Imported file _comma.dbc starts ";
CM_ "Imported file _comma.dbc starts h
CM_ "Imported file _comma.dbc starts h";
CM_ "Imported file _comma.dbc starts he
CM_ "Imported file _comma.dbc starts ";
CM_ "Imported file _comma.dbc starts h
CM_ "Imported file _comma.dbc starts h";
CM_ "Imported file _comma.dbc starts he
CM_ "Imported file _comma.dbc starts h";
CM_ "Imported file _comma.dbc starts he
CM_ "Imported file _comma.dbc starts he";
CM_ "Imported file _comma.dbc starts her
CM_ "Imported file _comma.dbc star";
CM_ "Imported file _comma.dbc start
CM_ "Imported file _comma.dbc start";
CM_ "Imported file _comma.dbc starts
CM_ "Imported file _comma.dbc star";
CM_ "Imported file _comma.dbc start
CM_ "Imported file _comma.dbc start";
CM_ "Imported file _comma.dbc starts
CM_ "Imported file _comma.dbc start";
CM_ "Imported file _comma.dbc starts
CM_ "Imported file _comma.dbc start";
CM_ "Imported file _comma.dbc starts
CM_ "Imported file _comma.dbc starts";
CM_ "Imported file _comma.dbc starts 
CM_ "Imported file _comma.dbc starts ";
CM_ "Imported file _comma.dbc starts h
CM_ "Imported file _comma.dbc start";
CM_ "Imported file _comma.dbc starts
CM_ "Imported file _comma.dbc start";
CM_ "Imported file _comma.dbc starts
CM_ "Imported file _comma.dbc starts";
CM_ "Imported file _comma.dbc starts 
CM_ "Imported file _comma.dbc starts ";
CM_ "Imported file _comma.dbc starts h
CM_ "Imported file _comma.dbc starts";
CM_ "Imported file _comma.dbc starts 
CM_ "Imported file _comma.dbc starts ";
CM_ "Imported file _comma.dbc starts h
CM_ "Imported file _comma.dbc starts ";
CM_ "Imported file _comma.dbc starts h
CM_ "Imported file _comma.dbc starts h";
CM_ "Imported file _comma.dbc starts he
CM_ "Imported file _comma.dbc start";
CM_ "Imported file _comma.dbc starts
CM_ "Imported file _comma.dbc start";
CM_ "Imported file _comma.dbc starts
CM_ "Imported file _comma.dbc starts";
CM_ "Imported file _comma.dbc starts 
CM_ "Imported file _comma.dbc starts ";
CM_ "Imported file _comma.dbc starts h
CM_ "Imported file _comma.dbc starts";
CM_ "Imported file _comma.dbc starts 
CM_ "Imported file _comma.dbc starts ";
CM_ "Imported file _comma.dbc starts h
CM_ "Imported file _comma.dbc starts ";
CM_ "Imported file _comma.dbc starts h
CM_ "Imported file _comma.dbc starts h";
CM_ "Imported file _comma.dbc starts he
CM_ "Imported file _comma.dbc starts";
CM_ "Imported file _comma.dbc starts 
CM_ "Imported file _comma.dbc starts ";
CM_ "Imported file _comma.dbc starts h
CM_ "Imported file _comma.dbc starts ";
CM_ "Imported file _comma.dbc starts h
CM_ "Imported file _comma.dbc starts h";
CM_ "Imported file _comma.dbc starts he
CM_ "Imported file _comma.dbc starts ";
CM_ "Imported file _comma.dbc starts h
CM_ "Imported file _comma.dbc starts h";
CM_ "Imported file _comma.dbc starts he
CM_ "Imported file _comma.dbc starts h";
CM_ "Imported file _comma.dbc starts he
CM_ "Imported file _comma.dbc starts he";
CM_ "Imported file _comma.dbc starts her
CM_ "Imported file _comma.dbc start";
CM_ "Imported file _comma.dbc starts
CM_ "Imported file _comma.dbc start";
CM_ "Imported file _comma.dbc starts
CM_ "Imported file _comma.dbc starts";
CM_ "Imported file _comma.dbc starts 
CM_ "Imported file _comma.dbc starts ";
CM_ "Imported file _comma.dbc starts h
CM_ "Imported file _comma.dbc starts";
CM_ "Imported file _comma.dbc starts 
CM_ "Imported file _comma.dbc starts ";
CM_ "Imported file _comma.dbc starts h
CM_ "Imported file _comma.dbc starts ";
CM_ "Imported file _comma.dbc starts h
CM_ "Imported file _comma.dbc starts h";
CM_ "Imported file _comma.dbc starts he
CM_ "Imported file _comma.dbc starts";
CM_ "Imported file _comma.dbc starts 
CM_ "Imported file _comma.dbc starts ";
CM_ "Imported file _comma.dbc starts h
CM_ "Imported file _comma.dbc starts ";
CM_ "Imported file _comma.dbc starts h
CM_ "Imported file _comma.dbc starts h";
CM_ "Imported file _comma.dbc starts he
CM_ "Imported file _comma.dbc starts ";
CM_ "Imported file _comma.dbc starts h
CM_ "Imported file _comma.dbc starts h";
CM_ "Imported file _comma.dbc starts he
CM_ "Imported file _comma.dbc starts h";
CM_ "Imported file _comma.dbc starts he
CM_ "Imported file _comma.dbc starts he";
CM_ "Imported file _comma.dbc starts her
CM_ "Imported file _comma.dbc starts";
CM_ "Imported file _comma.dbc starts 
CM_ "Imported file _comma.dbc starts ";
CM_ "Imported file _comma.dbc starts h
CM_ "Imported file _comma.dbc starts ";
CM_ "Imported file _comma.dbc starts h
CM_ "Imported file _comma.dbc starts h";
CM_ "Imported file _comma.dbc starts he
CM_ "Imported file _comma.dbc starts ";
CM_ "Imported file _comma.dbc starts h
CM_ "Imported file _comma.dbc starts h";
CM_ "Imported file _comma.dbc starts he
CM_ "Imported file _comma.dbc starts h";
CM_ "Imported file _comma.dbc starts he
CM_ "Imported file _comma.dbc starts he";
CM_ "Imported file _comma.dbc starts her
CM_ "Imported file _comma.dbc starts ";
CM_ "Imported file _comma.dbc starts h
CM_ "Imported file _comma.dbc starts h";
CM_ "Imported file _comma.dbc starts he
CM_ "Imported file _comma.dbc starts h";
CM_ "Imported file _comma.dbc starts he
CM_ "Imported file _comma.dbc starts he";
CM_ "Imported file _comma.dbc starts her
CM_ "Imported file _comma.dbc starts h";
CM_ "Imported file _comma.dbc starts he
CM_ "Imported file _comma.dbc starts he";
CM_ "Imported file _comma.dbc starts her
CM_ "Imported file _comma.dbc starts he";
CM_ "Imported file _comma.dbc starts her
CM_ "Imported file _comma.dbc starts her";
CM_ "Imported file _comma.dbc starts here
CM_ "Imported file _comma.dbc sta";
CM_ "Imported file _comma.dbc star
CM_ "Imported file _comma.dbc star";
CM_ "Imported file _comma.dbc start
CM_ "Imported file _comma.dbc star";
CM_ "Imported file _comma.dbc start
CM_ "Imported file _comma.dbc start";
CM_ "Imported file _comma.dbc starts
CM_ "Imported file _comma.dbc sta";
CM_ "Imported file _comma.dbc star
CM_ "Imported file _comma.dbc star";
CM_ "Imported file _comma.dbc start
CM_ "Imported file _comma.dbc star";
CM_ "Imported file _comma.dbc start
CM_ "Imported file _comma.dbc start";
CM_ "Imported file _comma.dbc starts
CM_ "Imported file _comma.dbc star";
CM_ "Imported file _comma.dbc start
CM_ "Imported file _comma.dbc start";
CM_ "Imported file _comma.dbc starts
CM_ "Imported file _comma.dbc star";
CM_ "Imported file _comma.dbc start
CM_ "Imported file _comma.dbc start";
CM_ "Imported file _comma.dbc starts
CM_ "Imported file _comma.dbc start";
CM_ "Imported file _comma.dbc starts
CM_ "Imported file _comma.dbc start";
CM_ "Imported file _comma.dbc starts
CM_ "Imported file _comma.dbc starts";
CM_ "Imported file _comma.dbc starts 
CM_ "Imported file _comma.dbc starts ";
CM_ "Imported file _comma.dbc starts h
CM_ "Imported file _comma.dbc star";
CM_ "Imported file _comma.dbc start
CM_ "Imported file _comma.dbc start";
CM_ "Imported file _comma.dbc starts
CM_ "Imported file _comma.dbc star";
CM_ "Imported file _comma.dbc start
CM_ "Imported file _comma.dbc start";
CM_ "Imported file _comma.dbc starts
CM_ "Imported file _comma.dbc start";
CM_ "Imported file _comma.dbc starts
CM_ "Imported file _comma.dbc start";
CM_ "Imported file _comma.dbc starts
CM_ "Imported file _comma.dbc starts";
CM_ "Imported file _comma.dbc starts 
CM_ "Imported file _comma.dbc starts ";
CM_ "Imported file _comma.dbc starts h
CM_ "Imported file _comma.dbc start";
CM_ "Imported file _comma.dbc starts
CM_ "Imported file _comma.dbc start";
CM_ "Imported file _comma.dbc starts
CM_ "Imported file _comma.dbc starts";
CM_ "Imported file _comma.dbc starts 
CM_ "Imported file _comma.dbc starts ";
CM_ "Imported file _comma.dbc starts h
CM_ "Imported file _comma.dbc starts";
CM_ "Imported file _comma.dbc starts 
CM_ "Imported file _comma.dbc starts ";
CM_ "Imported file _comma.dbc starts h
CM_ "Imported file _comma.dbc starts ";
CM_ "Imported file _comma.dbc starts h
CM_ "Imported file _comma.dbc starts h";
CM_ "Imported file _comma.dbc starts he
CM_ "Imported file _comma.dbc star";
CM_ "Imported file _comma.dbc start
CM_ "Imported file _comma.dbc start";
CM_ "Imported file _comma.dbc starts
CM_ "Imported file _comma.dbc star";
CM_ "Imported file _comma.dbc start
CM_ "Imported file _comma.dbc start";
CM_ "Imported file _comma.dbc starts
CM_ "Imported file _comma.dbc start";
CM_ "Imported file _comma.dbc starts
CM_ "Imported file _comma.dbc start";
CM_ "Imported file _comma.dbc starts
CM_ "Imported file _comma.dbc starts";
CM_ "Imported file _comma.dbc starts 
CM_ "Imported file _comma.dbc starts ";
CM_ "Imported file _comma.dbc starts h
CM_ "Imported file _comma.dbc start";
CM_ "Imported file _comma.dbc starts
CM_ "Imported file _comma.dbc start";
CM_ "Imported file _comma.dbc starts
CM_ "Imported file _comma.dbc starts";
CM_ "Imported file _comma.dbc starts 
CM_ "Imported file _comma.dbc starts ";
CM_ "Imported file _comma.dbc starts h
CM_ "Imported file _comma.dbc starts";
CM_ "Imported file _comma.dbc starts 
CM_ "Imported file _comma.dbc starts ";
CM_ "Imported file _comma.dbc starts h
CM_ "Imported file _comma.dbc starts ";
CM_ "Imported file _comma.dbc starts h
CM_ "Imported file _comma.dbc starts h";
CM_ "Imported file _comma.dbc starts he
CM_ "Imported file _comma.dbc start";
CM_ "Imported file _comma.dbc starts
CM_ "Imported file _comma.dbc start";
CM_ "Imported file _comma.dbc starts
CM_ "Imported file _comma.dbc starts";
CM_ "Imported file _comma.dbc starts 
CM_ "Imported file _comma.dbc starts ";
CM_ "Imported file _comma.dbc starts h
CM_ "Imported file _comma.dbc starts";
CM_ "Imported file _comma.dbc starts 
CM_ "Imported file _comma.dbc starts ";
CM_ "Imported file _comma.dbc starts h
CM_ "Imported file _comma.dbc starts ";
CM_ "Imported file _comma.dbc starts h
CM_ "Imported file _comma.dbc starts h";
CM_ "Imported file _comma.dbc starts he
CM_ "Imported file _comma.dbc starts";
CM_ "Imported file _comma.dbc starts 
CM_ "Imported file _comma.dbc starts ";
CM_ "Imported file _comma.dbc starts h
CM_ "Imported file _comma.dbc starts ";
CM_ "Imported file _comma.dbc starts h
CM_ "Imported file _comma.dbc starts h";
CM_ "Imported file _comma.dbc starts he
CM_ "Imported file _comma.dbc starts ";
CM_ "Imported file _comma.dbc starts h
CM_ "Imported file _comma.dbc starts h";
CM_ "Imported file _comma.dbc starts he
CM_ "Imported file _comma.dbc starts h";
CM_ "Imported file _comma.dbc starts he
CM_ "Imported file _comma.dbc starts he";
CM_ "Imported file _comma.dbc starts her
CM_ "Imported file _comma.dbc star";
CM_ "Imported file _comma.dbc start
CM_ "Imported file _comma.dbc start";
CM_ "Imported file _comma.dbc starts
CM_ "Imported file _comma.dbc star";
CM_ "Imported file _comma.dbc start
CM_ "Imported file _comma.dbc start";
CM_ "Imported file _comma.dbc starts
CM_ "Imported file _comma.dbc start";
CM_ "Imported file _comma.dbc starts
CM_ "Imported file _comma.dbc start";
CM_ "Imported file _comma.dbc starts
CM_ "Imported file _comma.dbc starts";
CM_ "Imported file _comma.dbc starts 
CM_ "Imported file _comma.dbc starts ";
CM_ "Imported file _comma.dbc starts h
CM_ "Imported file _comma.dbc start";
CM_ "Imported file _comma.dbc starts
CM_ "Imported file _comma.dbc start";
CM_ "Imported file _comma.dbc starts
CM_ "Imported file _comma.dbc starts";
CM_ "Imported file _comma.dbc starts 
CM_ "Imported file _comma.dbc starts ";
CM_ "Imported file _comma.dbc starts h
CM_ "Imported file _comma.dbc starts";
CM_ "Imported file _comma.dbc starts 
CM_ "Imported file _comma.dbc starts ";
CM_ "Imported file _comma.dbc starts h
CM_ "Imported file _comma.dbc starts ";
CM_ "Imported file _comma.dbc starts h
CM_ "Imported file _comma.dbc starts h";
CM_ "Imported file _comma.dbc starts he
CM_ "Imported file _comma.dbc start";
CM_ "Imported file _comma.dbc starts
CM_ "Imported file _comma.dbc start";
CM_ "Imported file _comma.dbc starts
CM_ "Imported file _comma.dbc starts";
CM_ "Imported file _comma.dbc starts 
CM_ "Imported file _comma.dbc starts ";
CM_ "Imported file _comma.dbc starts h
CM_ "Imported file _comma.dbc starts";
CM_ "Imported file _comma.dbc starts 
CM_ "Imported file _comma.dbc starts ";
CM_ "Imported file _comma.dbc starts h
CM_ "Imported file _comma.dbc starts ";
CM_ "Imported file _comma.dbc starts h
CM_ "Imported file _comma.dbc starts h";
CM_ "Imported file _comma.dbc starts he
CM_ "Imported file _comma.dbc starts";
CM_ "Imported file _comma.dbc starts 
CM_ "Imported file _comma.dbc starts ";
CM_ "Imported file _comma.dbc starts h
CM_ "Imported file _comma.dbc starts ";
CM_ "Imported file _comma.dbc starts h
CM_ "Imported file _comma.dbc starts h";
CM_ "Imported file _comma.dbc starts he
CM_ "Imported file _comma.dbc starts ";
CM_ "Imported file _comma.dbc starts h
CM_ "Imported file _comma.dbc starts h";
CM_ "Imported file _comma.dbc starts he
CM_ "Imported file _comma.dbc starts h";
CM_ "Imported file _comma.dbc starts he
CM_ "Imported file _comma.dbc starts he";
CM_ "Imported file _comma.dbc starts her
CM_ "Imported file _comma.dbc start";
CM_ "Imported file _comma.dbc starts
CM_ "Imported file _comma.dbc start";
CM_ "Imported file _comma.dbc starts
CM_ "Imported file _comma.dbc starts";
CM_ "Imported file _comma.dbc starts 
CM_ "Imported file _comma.dbc starts ";
CM_ "Imported file _comma.dbc starts h
CM_ "Imported file _comma.dbc starts";
CM_ "Imported file _comma.dbc starts 
CM_ "Imported file _comma.dbc starts ";
CM_ "Imported file _comma.dbc starts h
CM_ "Imported file _comma.dbc starts ";
CM_ "Imported file _comma.dbc starts h
CM_ "Imported file _comma.dbc starts h";
CM_ "Imported file _comma.dbc starts he
CM_ "Imported file _comma.dbc starts";
CM_ "Imported file _comma.dbc starts 
CM_ "Imported file _comma.dbc starts ";
CM_ "Imported file _comma.dbc starts h
CM_ "Imported file _comma.dbc starts ";
CM_ "Imported file _comma.dbc starts h
CM_ "Imported file _comma.dbc starts h";
CM_ "Imported file _comma.dbc starts he
CM_ "Imported file _comma.dbc starts ";
CM_ "Imported file _comma.dbc starts h
CM_ "Imported file _comma.dbc starts h";
CM_ "Imported file _comma.dbc starts he
CM_ "Imported file _comma.dbc starts h";
CM_ "Imported file _comma.dbc starts he
CM_ "Imported file _comma.dbc starts he";
CM_ "Imported file _comma.dbc starts her
CM_ "Imported file _comma.dbc starts";
CM_ "Imported file _comma.dbc starts 
CM_ "Imported file _comma.dbc starts ";
CM_ "Imported file _comma.dbc starts h
CM_ "Imported file _comma.dbc starts ";
CM_ "Imported file _comma.dbc starts h
CM_ "Imported file _comma.dbc starts h";
CM_ "Imported file _comma.dbc starts he
CM_ "Imported file _comma.dbc starts ";
CM_ "Imported file _comma.dbc starts h
CM_ "Imported file _comma.dbc starts h";
CM_ "Imported file _comma.dbc starts he
CM_ "Imported file _comma.dbc starts h";
CM_ "Imported file _comma.dbc starts he
CM_ "Imported file _comma.dbc starts he";
CM_ "Imported file _comma.dbc starts her
CM_ "Imported file _comma.dbc starts ";
CM_ "Imported file _comma.dbc starts h
CM_ "Imported file _comma.dbc starts h";
CM_ "Imported file _comma.dbc starts he
CM_ "Imported file _comma.dbc starts h";
CM_ "Imported file _comma.dbc starts he
CM_ "Imported file _comma.dbc starts he";
CM_ "Imported file _comma.dbc starts her
CM_ "Imported file _comma.dbc starts h";
CM_ "Imported file _comma.dbc starts he
CM_ "Imported file _comma.dbc starts he";
CM_ "Imported file _comma.dbc starts her
CM_ "Imported file _comma.dbc starts he";
CM_ "Imported file _comma.dbc starts her
CM_ "Imported file _comma.dbc starts her";
CM_ "Imported file _comma.dbc starts here
CM_ "Imported file _comma.dbc star";
CM_ "Imported file _comma.dbc start
CM_ "Imported file _comma.dbc start";
CM_ "Imported file _comma.dbc starts
CM_ "Imported file _comma.dbc star";
CM_ "Imported file _comma.dbc start
CM_ "Imported file _comma.dbc start";
CM_ "Imported file _comma.dbc starts
CM_ "Imported file _comma.dbc start";
CM_ "Imported file _comma.dbc starts
CM_ "Imported file _comma.dbc start";
CM_ "Imported file _comma.dbc starts
CM_ "Imported file _comma.dbc starts";
CM_ "Imported file _comma.dbc starts 
CM_ "Imported file _comma.dbc starts ";
CM_ "Imported file _comma.dbc starts h
CM_ "Imported file _comma.dbc start";
CM_ "Imported file _comma.dbc starts
CM_ "Imported file _comma.dbc start";
CM_ "Imported file _comma.dbc starts
CM_ "Imported file _comma.dbc starts";
CM_ "Imported file _comma.dbc starts 
CM_ "Imported file _comma.dbc starts ";
CM_ "Imported file _comma.dbc starts h
CM_ "Imported file _comma.dbc starts";
CM_ "Imported file _comma.dbc starts 
CM_ "Imported file _comma.dbc starts ";
CM_ "Imported file _comma.dbc starts h
CM_ "Imported file _comma.dbc starts ";
CM_ "Imported file _comma.dbc starts h
CM_ "Imported file _comma.dbc starts h";
CM_ "Imported file _comma.dbc starts he
CM_ "Imported file _comma.dbc start";
CM_ "Imported file _comma.dbc starts
CM_ "Imported file _comma.dbc start";
CM_ "Imported file _comma.dbc starts
CM_ "Imported file _comma.dbc starts";
CM_ "Imported file _comma.dbc starts 
CM_ "Imported file _comma.dbc starts ";
CM_ "Imported file _comma.dbc starts h
CM_ "Imported file _comma.dbc starts";
CM_ "Imported file _comma.dbc starts 
CM_ "Imported file _comma.dbc starts ";
CM_ "Imported file _comma.dbc starts h
CM_ "Imported file _comma.dbc starts ";
CM_ "Imported file _comma.dbc starts h
CM_ "Imported file _comma.dbc starts h";
CM_ "Imported file _comma.dbc starts he
CM_ "Imported file _comma.dbc starts";
CM_ "Imported file _comma.dbc starts 
CM_ "Imported file _comma.dbc starts ";
CM_ "Imported file _comma.dbc starts h
CM_ "Imported file _comma.dbc starts ";
CM_ "Imported file _comma.dbc starts h
CM_ "Imported file _comma.dbc starts h";
CM_ "Imported file _comma.dbc starts he
CM_ "Imported file _comma.dbc starts ";
CM_ "Imported file _comma.dbc starts h
CM_ "Imported file _comma.dbc starts h";
CM_ "Imported file _comma.dbc starts he
CM_ "Imported file _comma.dbc starts h";
CM_ "Imported file _comma.dbc starts he
CM_ "Imported file _comma.dbc starts he";
CM_ "Imported file _comma.dbc starts her
CM_ "Imported file _comma.dbc start";
CM_ "Imported file _comma.dbc starts
CM_ "Imported file _comma.dbc start";
CM_ "Imported file _comma.dbc starts
CM_ "Imported file _comma.dbc starts";
CM_ "Imported file _comma.dbc starts 
CM_ "Imported file _comma.dbc starts ";
CM_ "Imported file _comma.dbc starts h
CM_ "Imported file _comma.dbc starts";
CM_ "Imported file _comma.dbc starts 
CM_ "Imported file _comma.dbc starts ";
CM_ "Imported file _comma.dbc starts h
CM_ "Imported file _comma.dbc starts ";
CM_ "Imported file _comma.dbc starts h
CM_ "Imported file _comma.dbc starts h";
CM_ "Imported file _comma.dbc starts he
CM_ "Imported file _comma.dbc starts";
CM_ "Imported file _comma.dbc starts 
CM_ "Imported file _comma.dbc starts ";
CM_ "Imported file _comma.dbc starts h
CM_ "Imported file _comma.dbc starts ";
CM_ "Imported file _comma.dbc starts h
CM_ "Imported file _comma.dbc starts h";
CM_ "Imported file _comma.dbc starts he
CM_ "Imported file _comma.dbc starts ";
CM_ "Imported file _comma.dbc starts h
CM_ "Imported file _comma.dbc starts h";
CM_ "Imported file _comma.dbc starts he
CM_ "Imported file _comma.dbc starts h";
CM_ "Imported file _comma.dbc starts he
CM_ "Imported file _comma.dbc starts he";
CM_ "Imported file _comma.dbc starts her
CM_ "Imported file _comma.dbc starts";
CM_ "Imported file _comma.dbc starts 
CM_ "Imported file _comma.dbc starts ";
CM_ "Imported file _comma.dbc starts h
CM_ "Imported file _comma.dbc starts ";
CM_ "Imported file _comma.dbc starts h
CM_ "Imported file _comma.dbc starts h";
CM_ "Imported file _comma.dbc starts he
CM_ "Imported file _comma.dbc starts ";
CM_ "Imported file _comma.dbc starts h
CM_ "Imported file _comma.dbc starts h";
CM_ "Imported file _comma.dbc starts he
CM_ "Imported file _comma.dbc starts h";
CM_ "Imported file _comma.dbc starts he
CM_ "Imported file _comma.dbc starts he";
CM_ "Imported file _comma.dbc starts her
CM_ "Imported file _comma.dbc starts ";
CM_ "Imported file _comma.dbc starts h
CM_ "Imported file _comma.dbc starts h";
CM_ "Imported file _comma.dbc starts he
CM_ "Imported file _comma.dbc starts h";
CM_ "Imported file _comma.dbc starts he
CM_ "Imported file _comma.dbc starts he";
CM_ "Imported file _comma.dbc starts her
CM_ "Imported file _comma.dbc starts h";
CM_ "Imported file _comma.dbc starts he
CM_ "Imported file _comma.dbc starts he";
CM_ "Imported file _comma.dbc starts her
CM_ "Imported file _comma.dbc starts he";
CM_ "Imported file _comma.dbc starts her
CM_ "Imported file _comma.dbc starts her";
CM_ "Imported file _comma.dbc starts here
CM_ "Imported file _comma.dbc start";
CM_ "Imported file _comma.dbc starts
CM_ "Imported file _comma.dbc start";
CM_ "Imported file _comma.dbc starts
CM_ "Imported file _comma.dbc starts";
CM_ "Imported file _comma.dbc starts 
CM_ "Imported file _comma.dbc starts ";
CM_ "Imported file _comma.dbc starts h
CM_ "Imported file _comma.dbc starts";
CM_ "Imported file _comma.dbc starts 
CM_ "Imported file _comma.dbc starts ";
CM_ "Imported file _comma.dbc starts h
CM_ "Imported file _comma.dbc starts ";
CM_ "Imported file _comma.dbc starts h
CM_ "Imported file _comma.dbc starts h";
CM_ "Imported file _comma.dbc starts he
CM_ "Imported file _comma.dbc starts";
CM_ "Imported file _comma.dbc starts 
CM_ "Imported file _comma.dbc starts ";
CM_ "Imported file _comma.dbc starts h
CM_ "Imported file _comma.dbc starts ";
CM_ "Imported file _comma.dbc starts h
CM_ "Imported file _comma.dbc starts h";
CM_ "Imported file _comma.dbc starts he
CM_ "Imported file _comma.dbc starts ";
CM_ "Imported file _comma.dbc starts h
CM_ "Imported file _comma.dbc starts h";
CM_ "Imported file _comma.dbc starts he
CM_ "Imported file _comma.dbc starts h";
CM_ "Imported file _comma.dbc starts he
CM_ "Imported file _comma.dbc starts he";
CM_ "Imported file _comma.dbc starts her
CM_ "Imported file _comma.dbc starts";
CM_ "Imported file _comma.dbc starts 
CM_ "Imported file _comma.dbc starts ";
CM_ "Imported file _comma.dbc starts h
CM_ "Imported file _comma.dbc starts ";
CM_ "Imported file _comma.dbc starts h
CM_ "Imported file _comma.dbc starts h";
CM_ "Imported file _comma.dbc starts he
CM_ "Imported file _comma.dbc starts ";
CM_ "Imported file _comma.dbc starts h
CM_ "Imported file _comma.dbc starts h";
CM_ "Imported file _comma.dbc starts he
CM_ "Imported file _comma.dbc starts h";
CM_ "Imported file _comma.dbc starts he
CM_ "Imported file _comma.dbc starts he";
CM_ "Imported file _comma.dbc starts her
CM_ "Imported file _comma.dbc starts ";
CM_ "Imported file _comma.dbc starts h
CM_ "Imported file _comma.dbc starts h";
CM_ "Imported file _comma.dbc starts he
CM_ "Imported file _comma.dbc starts h";
CM_ "Imported file _comma.dbc starts he
CM_ "Imported file _comma.dbc starts he";
CM_ "Imported file _comma.dbc starts her
CM_ "Imported file _comma.dbc starts h";
CM_ "Imported file _comma.dbc starts he
CM_ "Imported file _comma.dbc starts he";
CM_ "Imported file _comma.dbc starts her
CM_ "Imported file _comma.dbc starts he";
CM_ "Imported file _comma.dbc starts her
CM_ "Imported file _comma.dbc starts her";
CM_ "Imported file _comma.dbc starts here
CM_ "Imported file _comma.dbc starts";
CM_ "Imported file _comma.dbc starts 
CM_ "Imported file _comma.dbc starts ";
CM_ "Imported file _comma.dbc starts h
CM_ "Imported file _comma.dbc starts ";
CM_ "Imported file _comma.dbc starts h
CM_ "Imported file _comma.dbc starts h";
CM_ "Imported file _comma.dbc starts he
CM_ "Imported file _comma.dbc starts ";
CM_ "Imported file _comma.dbc starts h
CM_ "Imported file _comma.dbc starts h";
CM_ "Imported file _comma.dbc starts he
CM_ "Imported file _comma.dbc starts h";
CM_ "Imported file _comma.dbc starts he
CM_ "Imported file _comma.dbc starts he";
CM_ "Imported file _comma.dbc starts her
CM_ "Imported file _comma.dbc starts ";
CM_ "Imported file _comma.dbc starts h
CM_ "Imported file _comma.dbc starts h";
CM_ "Imported file _comma.dbc starts he
CM_ "Imported file _comma.dbc starts h";
CM_ "Imported file _comma.dbc starts he
CM_ "Imported file _comma.dbc starts he";
CM_ "Imported file _comma.dbc starts her
CM_ "Imported file _comma.dbc starts h";
CM_ "Imported file _comma.dbc starts he
CM_ "Imported file _comma.dbc starts he";
CM_ "Imported file _comma.dbc starts her
CM_ "Imported file _comma.dbc starts he";
CM_ "Imported file _comma.dbc starts her
CM_ "Imported file _comma.dbc starts her";
CM_ "Imported file _comma.dbc starts here
CM_ "Imported file _comma.dbc starts ";
CM_ "Imported file _comma.dbc starts h
CM_ "Imported file _comma.dbc starts h";
CM_ "Imported file _comma.dbc starts he
CM_ "Imported file _comma.dbc starts h";
CM_ "Imported file _comma.dbc starts he
CM_ "Imported file _comma.dbc starts he";
CM_ "Imported file _comma.dbc starts her
CM_ "Imported file _comma.dbc starts h";
CM_ "Imported file _comma.dbc starts he
CM_ "Imported file _comma.dbc starts he";
CM_ "Imported file _comma.dbc starts her
CM_ "Imported file _comma.dbc starts he";
CM_ "Imported file _comma.dbc starts her
CM_ "Imported file _comma.dbc starts her";
CM_ "Imported file _comma.dbc starts here
CM_ "Imported file _comma.dbc starts h";
CM_ "Imported file _comma.dbc starts he
CM_ "Imported file _comma.dbc starts he";
CM_ "Imported file _comma.dbc starts her
CM_ "Imported file _comma.dbc starts he";
CM_ "Imported file _comma.dbc starts her
CM_ "Imported file _comma.dbc starts her";
CM_ "Imported file _comma.dbc starts here
CM_ "Imported file _comma.dbc starts he";
CM_ "Imported file _comma.dbc starts her
CM_ "Imported file _comma.dbc starts her";
CM_ "Imported file _comma.dbc starts here
CM_ "Imported file _comma.dbc starts her";
CM_ "Imported file _comma.dbc starts here
CM_ "Imported file _comma.dbc starts here";
CM_ "Imported file _comma.dbc starts here"
BO_ 359 STEERING_IPAS_COMMA: 8 IPAS
SG_ STATE : 7|4@0+ (1,0) [0|15]
CM_ "Imported file _toyota_2017.dbc starts ";
CM_ "Imported file _toyota_2017.dbc starts h
CM_ "Imported file _toyota_2017.dbc starts h";
CM_ "Imported file _toyota_2017.dbc starts he
CM_ "Imported file _toyota_2017.dbc starts h";
CM_ "Imported file _toyota_2017.dbc starts he
CM_ "Imported file _toyota_2017.dbc starts he";
CM_ "Imported file _toyota_2017.dbc starts her
CM_ "Imported file _toyota_2017.dbc starts h";
CM_ "Imported file _toyota_2017.dbc starts he
CM_ "Imported file _toyota_2017.dbc starts he";
CM_ "Imported file _toyota_2017.dbc starts her
CM_ "Imported file _toyota_2017.dbc starts he";
CM_ "Imported file _toyota_2017.dbc starts her
CM_ "Imported file _toyota_2017.dbc starts her";
CM_ "Imported file _toyota_2017.dbc starts here
CM_ "Imported file _toyota_2017.dbc starts h";
CM_ "Imported file _toyota_2017.dbc starts he
CM_ "Imported file _toyota_2017.dbc starts he";
CM_ "Imported file _toyota_2017.dbc starts her
CM_ "Imported file _toyota_2017.dbc starts he";
CM_ "Imported file _toyota_2017.dbc starts her
CM_ "Imported file _toyota_2017.dbc starts her";
CM_ "Imported file _toyota_2017.dbc starts here
CM_ "Imported file _toyota_2017.dbc starts he";
CM_ "Imported file _toyota_2017.dbc starts her
CM_ "Imported file _toyota_2017.dbc starts her";
CM_ "Imported file _toyota_2017.dbc starts here
CM_ "Imported file _toyota_2017.dbc starts her";
CM_ "Imported file _toyota_2017.dbc starts here
CM_ "Imported file _toyota_2017.dbc starts here";
CM_ "Imported file _toyota_2017.dbc starts here"
VERSION
CM_ "CHFFR_METRIC 37 STEER_ANGLE STEER_ANGLE";
CM_ "CHFFR_METRIC 37 STEER_ANGLE STEER_ANGLE 
CM_ "CHFFR_METRIC 37 STEER_ANGLE STEER_ANGLE ";
CM_ "CHFFR_METRIC 37 STEER_ANGLE STEER_ANGLE 0
CM_ "CHFFR_METRIC 37 STEER_ANGLE STEER_ANGLE ";
CM_ "CHFFR_METRIC 37 STEER_ANGLE STEER_ANGLE 0
CM_ "CHFFR_METRIC 37 STEER_ANGLE STEER_ANGLE 0";
CM_ "CHFFR_METRIC 37 STEER_ANGLE STEER_ANGLE 0.
CM_ "CHFFR_METRIC 37 STEER_ANGLE STEER_ANGLE ";
CM_ "CHFFR_METRIC 37 STEER_ANGLE STEER_ANGLE 0
CM_ "CHFFR_METRIC 37 STEER_ANGLE STEER_ANGLE 0";
CM_ "CHFFR_METRIC 37 STEER_ANGLE STEER_ANGLE 0.
CM_ "CHFFR_METRIC 37 STEER_ANGLE STEER_ANGLE 0";
CM_ "CHFFR_METRIC 37 STEER_ANGLE STEER_ANGLE 0.
CM_ "CHFFR_METRIC 37 STEER_ANGLE STEER_ANGLE 0.";
CM_ "CHFFR_METRIC 37 STEER_ANGLE STEER_ANGLE 0.3
CM_ "CHFFR_METRIC 37 STEER_ANGLE STEER_ANGLE ";
CM_ "CHFFR_METRIC 37 STEER_ANGLE STEER_ANGLE 0
CM_ "CHFFR_METRIC 37 STEER_ANGLE STEER_ANGLE 0";
CM_ "CHFFR_METRIC 37 STEER_ANGLE STEER_ANGLE 0.
CM_ "CHFFR_METRIC 37 STEER_ANGLE STEER_ANGLE 0";
CM_ "CHFFR_METRIC 37 STEER_ANGLE STEER_ANGLE 0.
CM_ "CHFFR_METRIC 37 STEER_ANGLE STEER_ANGLE 0.";
CM_ "CHFFR_METRIC 37 STEER_ANGLE STEER_ANGLE 0.3
CM_ "CHFFR_METRIC 37 STEER_ANGLE STEER_ANGLE 0";
CM_ "CHFFR_METRIC 37 STEER_ANGLE STEER_ANGLE 0.
CM_ "CHFFR_METRIC 37 STEER_ANGLE STEER_ANGLE 0.";
CM_ "CHFFR_METRIC 37 STEER_ANGLE STEER_ANGLE 0.3
CM_ "CHFFR_METRIC 37 STEER_ANGLE STEER_ANGLE 0.";
CM_ "CHFFR_METRIC 37 STEER_ANGLE STEER_ANGLE 0.3
CM_ "CHFFR_METRIC 37 STEER_ANGLE STEER_ANGLE 0.3";
CM_ "CHFFR_METRIC 37 STEER_ANGLE STEER_ANGLE 0.36
CM_ "CHFFR_METRIC 37 STEER_ANGLE STEER_ANGLE";
CM_ "CHFFR_METRIC 37 STEER_ANGLE STEER_ANGLE 
CM_ "CHFFR_METRIC 37 STEER_ANGLE STEER_ANGLE ";
CM_ "CHFFR_METRIC 37 STEER_ANGLE STEER_ANGLE 0
CM_ "CHFFR_METRIC 37 STEER_ANGLE STEER_ANGLE ";
CM_ "CHFFR_METRIC 37 STEER_ANGLE STEER_ANGLE 0
CM_ "CHFFR_METRIC 37 STEER_ANGLE STEER_ANGLE 0";
CM_ "CHFFR_METRIC 37 STEER_ANGLE STEER_ANGLE 0.
CM_ "CHFFR_METRIC 37 STEER_ANGLE STEER_ANGLE ";
CM_ "CHFFR_METRIC 37 STEER_ANGLE STEER_ANGLE 0
CM_ "CHFFR_METRIC 37 STEER_ANGLE STEER_ANGLE 0";
CM_ "CHFFR_METRIC 37 STEER_ANGLE STEER_ANGLE 0.
CM_ "CHFFR_METRIC 37 STEER_ANGLE STEER_ANGLE 0";
CM_ "CHFFR_METRIC 37 STEER_ANGLE STEER_ANGLE 0.
CM_ "CHFFR_METRIC 37 STEER_ANGLE STEER_ANGLE 0.";
CM_ "CHFFR_METRIC 37 STEER_ANGLE STEER_ANGLE 0.3
CM_ "CHFFR_METRIC 37 STEER_ANGLE STEER_ANGLE ";
CM_ "CHFFR_METRIC 37 STEER_ANGLE STEER_ANGLE 0
CM_ "CHFFR_METRIC 37 STEER_ANGLE STEER_ANGLE 0";
CM_ "CHFFR_METRIC 37 STEER_ANGLE STEER_ANGLE 0.
CM_ "CHFFR_METRIC 37 STEER_ANGLE STEER_ANGLE 0";
CM_ "CHFFR_METRIC 37 STEER_ANGLE STEER_ANGLE 0.
CM_ "CHFFR_METRIC 37 STEER_ANGLE STEER_ANGLE 0.";
CM_ "CHFFR_METRIC 37 STEER_ANGLE STEER_ANGLE 0.3
CM_ "CHFFR_METRIC 37 STEER_ANGLE STEER_ANGLE 0";
CM_ "CHFFR_METRIC 37 STEER_ANGLE STEER_ANGLE 0.
CM_ "CHFFR_METRIC 37 STEER_ANGLE STEER_ANGLE 0.";
CM_ "CHFFR_METRIC 37 STEER_ANGLE STEER_ANGLE 0.3
CM_ "CHFFR_METRIC 37 STEER_ANGLE STEER_ANGLE 0.";
CM_ "CHFFR_METRIC 37 STEER_ANGLE STEER_ANGLE 0.3
CM_ "CHFFR_METRIC 37 STEER_ANGLE STEER_ANGLE 0.3";
CM_ "CHFFR_METRIC 37 STEER_ANGLE STEER_ANGLE 0.36
CM_ "CHFFR_METRIC 37 STEER_ANGLE STEER_ANGLE ";
CM_ "CHFFR_METRIC 37 STEER_ANGLE STEER_ANGLE 0
CM_ "CHFFR_METRIC 37 STEER_ANGLE STEER_ANGLE 0";
CM_ "CHFFR_METRIC 37 STEER_ANGLE STEER_ANGLE 0.
CM_ "CHFFR_METRIC 37 STEER_ANGLE STEER_ANGLE 0";
CM_ "CHFFR_METRIC 37 STEER_ANGLE STEER_ANGLE 0.
CM_ "CHFFR_METRIC 37 STEER_ANGLE STEER_ANGLE 0.";
CM_ "CHFFR_METRIC 37 STEER_ANGLE STEER_ANGLE 0.3
CM_ "CHFFR_METRIC 37 STEER_ANGLE STEER_ANGLE 0";
CM_ "CHFFR_METRIC 37 STEER_ANGLE STEER_ANGLE 0.
CM_ "CHFFR_METRIC 37 STEER_ANGLE STEER_ANGLE 0.";
CM_ "CHFFR_METRIC 37 STEER_ANGLE STEER_ANGLE 0.3
CM_ "CHFFR_METRIC 37 STEER_ANGLE STEER_ANGLE 0.";
CM_ "CHFFR_METRIC 37 STEER_ANGLE STEER_ANGLE 0.3
CM_ "CHFFR_METRIC 37 STEER_ANGLE STEER_ANGLE 0.3";
CM_ "CHFFR_METRIC 37 STEER_ANGLE STEER_ANGLE 0.36
CM_ "CHFFR_METRIC 37 STEER_ANGLE STEER_ANGLE ";
CM_ "CHFFR_METRIC 37 STEER_ANGLE STEER_ANGLE 0
CM_ "CHFFR_METRIC 37 STEER_ANGLE STEER_ANGLE 0";
CM_ "CHFFR_METRIC 37 STEER_ANGLE STEER_ANGLE 0.
CM_ "CHFFR_METRIC 37 STEER_ANGLE STEER_ANGLE 0";
CM_ "CHFFR_METRIC 37 STEER_ANGLE STEER_ANGLE 0.
CM_ "CHFFR_METRIC 37 STEER_ANGLE STEER_ANGLE 0.";
CM_ "CHFFR_METRIC 37 STEER_ANGLE STEER_ANGLE 0.3
CM_ "CHFFR_METRIC 37 STEER_ANGLE STEER_ANGLE 0";
CM_ "CHFFR_METRIC 37 STEER_ANGLE STEER_ANGLE 0.
CM_ "CHFFR_METRIC 37 STEER_ANGLE STEER_ANGLE 0.";
CM_ "CHFFR_METRIC 37 STEER_ANGLE STEER_ANGLE 0.3
CM_ "CHFFR_METRIC 37 STEER_ANGLE STEER_ANGLE 0.";
CM_ "CHFFR_METRIC 37 STEER_ANGLE STEER_ANGLE 0.3
CM_ "CHFFR_METRIC 37 STEER_ANGLE STEER_ANGLE 0.3";
CM_ "CHFFR_METRIC 37 STEER_ANGLE STEER_ANGLE 0.36
CM_ "CHFFR_METRIC 37 STEER_ANGLE STEER_ANGLE 0";
CM_ "CHFFR_METRIC 37 STEER_ANGLE STEER_ANGLE 0.
CM_ "CHFFR_METRIC 37 STEER_ANGLE STEER_ANGLE 0.";
CM_ "CHFFR_METRIC 37 STEER_ANGLE STEER_ANGLE 0.3
CM_ "CHFFR_METRIC 37 STEER_ANGLE STEER_ANGLE 0.";
CM_ "CHFFR_METRIC 37 STEER_ANGLE STEER_ANGLE 0.3
CM_ "CHFFR_METRIC 37 STEER_ANGLE STEER_ANGLE 0.3";
CM_ "CHFFR_METRIC 37 STEER_ANGLE STEER_ANGLE 0.36
CM_ "CHFFR_METRIC 37 STEER_ANGLE STEER_ANGLE 0";
CM_ "CHFFR_METRIC 37 STEER_ANGLE STEER_ANGLE 0.
CM_ "CHFFR_METRIC 37 STEER_ANGLE STEER_ANGLE 0.";
CM_ "CHFFR_METRIC 37 STEER_ANGLE STEER_ANGLE 0.3
CM_ "CHFFR_METRIC 37 STEER_ANGLE STEER_ANGLE 0.";
CM_ "CHFFR_METRIC 37 STEER_ANGLE STEER_ANGLE 0.3
CM_ "CHFFR_METRIC 37 STEER_ANGLE STEER_ANGLE 0.3";
CM_ "CHFFR_METRIC 37 STEER_ANGLE STEER_ANGLE 0.36
CM_ "CHFFR_METRIC 37 STEER_ANGLE STEER_ANGLE 0.";
CM_ "CHFFR_METRIC 37 STEER_ANGLE STEER_ANGLE 0.3
CM_ "CHFFR_METRIC 37 STEER_ANGLE STEER_ANGLE 0.3";
CM_ "CHFFR_METRIC 37 STEER_ANGLE STEER_ANGLE 0.36
CM_ "CHFFR_METRIC 37 STEER_ANGLE STEER_ANGLE 0.";
CM_ "CHFFR_METRIC 37 STEER_ANGLE STEER_ANGLE 0.3
CM_ "CHFFR_METRIC 37 STEER_ANGLE STEER_ANGLE 0.3";
CM_ "CHFFR_METRIC 37 STEER_ANGLE STEER_ANGLE 0.36
CM_ "CHFFR_METRIC 37 STEER_ANGLE STEER_ANGLE 0.3";
CM_ "CHFFR_METRIC 37 STEER_ANGLE STEER_ANGLE 0.36
CM_ "CHFFR_METRIC 37 STEER_ANGLE STEER_ANGLE 0.3";
CM_ "CHFFR_METRIC 37 STEER_ANGLE STEER_ANGLE 0.36
CM_ "CHFFR_METRIC 37 STEER_ANGLE STEER_ANGLE 0.36";
CM_ "CHFFR_METRIC 37 STEER_ANGLE STEER_ANGLE 0.36 
CM_ "CHFFR_METRIC 37 STEER_ANGLE STEER_ANGLE 0.36 ";
CM_ "CHFFR_METRIC 37 STEER_ANGLE STEER_ANGLE 0.36 1
CM_ "CHFFR_METRIC 37 STEER_ANGLE STEER_ANGLE ";
CM_ "CHFFR_METRIC 37 STEER_ANGLE STEER_ANGLE 0
CM_ "CHFFR_METRIC 37 STEER_ANGLE STEER_ANGLE 0";
CM_ "CHFFR_METRIC 37 STEER_ANGLE STEER_ANGLE 0.
CM_ "CHFFR_METRIC 37 STEER_ANGLE STEER_ANGLE 0";
CM_ "CHFFR_METRIC 37 STEER_ANGLE STEER_ANGLE 0.
CM_ "CHFFR_METRIC 37 STEER_ANGLE STEER_ANGLE 0.";
CM_ "CHFFR_METRIC 37 STEER_ANGLE STEER_ANGLE 0.3
CM_ "CHFFR_METRIC 37 STEER_ANGLE STEER_ANGLE 0";
CM_ "CHFFR_METRIC 37 STEER_ANGLE STEER_ANGLE 0.
CM_ "CHFFR_METRIC 37 STEER_ANGLE STEER_ANGLE 0.";
CM_ "CHFFR_METRIC 37 STEER_ANGLE STEER_ANGLE 0.3
CM_ "CHFFR_METRIC 37 STEER_ANGLE STEER_ANGLE 0.";
CM_ "CHFFR_METRIC 37 STEER_ANGLE STEER_ANGLE 0.3
CM_ "CHFFR_METRIC 37 STEER_ANGLE STEER_ANGLE 0.3";
CM_ "CHFFR_METRIC 37 STEER_ANGLE STEER_ANGLE 0.36
CM_ "CHFFR_METRIC 37 STEER_ANGLE STEER_ANGLE ";
CM_ "CHFFR_METRIC 37 STEER_ANGLE STEER_ANGLE 0
CM_ "CHFFR_METRIC 37 STEER_ANGLE STEER_ANGLE 0";
CM_ "CHFFR_METRIC 37 STEER_ANGLE STEER_ANGLE 0.
CM_ "CHFFR_METRIC 37 STEER_ANGLE STEER_ANGLE 0";
CM_ "CHFFR_METRIC 37 STEER_ANGLE STEER_ANGLE 0.
CM_ "CHFFR_METRIC 37 STEER_ANGLE STEER_ANGLE 0.";
CM_ "CHFFR_METRIC 37 STEER_ANGLE STEER_ANGLE 0.3
CM_ "CHFFR_METRIC 37 STEER_ANGLE STEER_ANGLE 0";
CM_ "CHFFR_METRIC 37 STEER_ANGLE STEER_ANGLE 0.
CM_ "CHFFR_METRIC 37 STEER_ANGLE STEER_ANGLE 0.";
CM_ "CHFFR_METRIC 37 STEER_ANGLE STEER_ANGLE 0.3
CM_ "CHFFR_METRIC 37 STEER_ANGLE STEER_ANGLE 0.";
CM_ "CHFFR_METRIC 37 STEER_ANGLE STEER_ANGLE 0.3
CM_ "CHFFR_METRIC 37 STEER_ANGLE STEER_ANGLE 0.3";
CM_ "CHFFR_METRIC 37 STEER_ANGLE STEER_ANGLE 0.36
CM_ "CHFFR_METRIC 37 STEER_ANGLE STEER_ANGLE 0";
CM_ "CHFFR_METRIC 37 STEER_ANGLE STEER_ANGLE 0.
CM_ "CHFFR_METRIC 37 STEER_ANGLE STEER_ANGLE 0.";
CM_ "CHFFR_METRIC 37 STEER_ANGLE STEER_ANGLE 0.3
CM_ "CHFFR_METRIC 37 STEER_ANGLE STEER_ANGLE 0.";
CM_ "CHFFR_METRIC 37 STEER_ANGLE STEER_ANGLE 0.3
CM_ "CHFFR_METRIC 37 STEER_ANGLE STEER_ANGLE 0.3";
CM_ "CHFFR_METRIC 37 STEER_ANGLE STEER_ANGLE 0.36
CM_ "CHFFR_METRIC 37 STEER_ANGLE STEER_ANGLE 0";
CM_ "CHFFR_METRIC 37 STEER_ANGLE STEER_ANGLE 0.
CM_ "CHFFR_METRIC 37 STEER_ANGLE STEER_ANGLE 0.";
CM_ "CHFFR_METRIC 37 STEER_ANGLE STEER_ANGLE 0.3
CM_ "CHFFR_METRIC 37 STEER_ANGLE STEER_ANGLE 0.";
CM_ "CHFFR_METRIC 37 STEER_ANGLE STEER_ANGLE 0.3
CM_ "CHFFR_METRIC 37 STEER_ANGLE STEER_ANGLE 0.3";
CM_ "CHFFR_METRIC 37 STEER_ANGLE STEER_ANGLE 0.36
CM_ "CHFFR_METRIC 37 STEER_ANGLE STEER_ANGLE 0.";
CM_ "CHFFR_METRIC 37 STEER_ANGLE STEER_ANGLE 0.3
CM_ "CHFFR_METRIC 37 STEER_ANGLE STEER_ANGLE 0.3";
CM_ "CHFFR_METRIC 37 STEER_ANGLE STEER_ANGLE 0.36
CM_ "CHFFR_METRIC 37 STEER_ANGLE STEER_ANGLE 0.";
CM_ "CHFFR_METRIC 37 STEER_ANGLE STEER_ANGLE 0.3
CM_ "CHFFR_METRIC 37 STEER_ANGLE STEER_ANGLE 0.3";
CM_ "CHFFR_METRIC 37 STEER_ANGLE STEER_ANGLE 0.36
CM_ "CHFFR_METRIC 37 STEER_ANGLE STEER_ANGLE 0.3";
CM_ "CHFFR_METRIC 37 STEER_ANGLE STEER_ANGLE 0.36
CM_ "CHFFR_METRIC 37 STEER_ANGLE STEER_ANGLE 0.3";
CM_ "CHFFR_METRIC 37 STEER_ANGLE STEER_ANGLE 0.36
CM_ "CHFFR_METRIC 37 STEER_ANGLE STEER_ANGLE 0.36";
CM_ "CHFFR_METRIC 37 STEER_ANGLE STEER_ANGLE 0.36 
CM_ "CHFFR_METRIC 37 STEER_ANGLE STEER_ANGLE 0.36 ";
CM_ "CHFFR_METRIC 37 STEER_ANGLE STEER_ANGLE 0.36 1
CM_ "CHFFR_METRIC 37 STEER_ANGLE STEER_ANGLE 0";
CM_ "CHFFR_METRIC 37 STEER_ANGLE STEER_ANGLE 0.
CM_ "CHFFR_METRIC 37 STEER_ANGLE STEER_ANGLE 0.";
CM_ "CHFFR_METRIC 37 STEER_ANGLE STEER_ANGLE 0.3
CM_ "CHFFR_METRIC 37 STEER_ANGLE STEER_ANGLE 0.";
CM_ "CHFFR_METRIC 37 STEER_ANGLE STEER_ANGLE 0.3
CM_ "CHFFR_METRIC 37 STEER_ANGLE STEER_ANGLE 0.3";
CM_ "CHFFR_METRIC 37 STEER_ANGLE STEER_ANGLE 0.36
CM_ "CHFFR_METRIC 37 STEER_ANGLE STEER_ANGLE 0";
CM_ "CHFFR_METRIC 37 STEER_ANGLE STEER_ANGLE 0.
CM_ "CHFFR_METRIC 37 STEER_ANGLE STEER_ANGLE 0.";
CM_ "CHFFR_METRIC 37 STEER_ANGLE STEER_ANGLE 0.3
CM_ "CHFFR_METRIC 37 STEER_ANGLE STEER_ANGLE 0.";
CM_ "CHFFR_METRIC 37 STEER_ANGLE STEER_ANGLE 0.3
CM_ "CHFFR_METRIC 37 STEER_ANGLE STEER_ANGLE 0.3";
CM_ "CHFFR_METRIC 37 STEER_ANGLE STEER_ANGLE 0.36
CM_ "CHFFR_METRIC 37 STEER_ANGLE STEER_ANGLE 0.";
CM_ "CHFFR_METRIC 37 STEER_ANGLE STEER_ANGLE 0.3
CM_ "CHFFR_METRIC 37 STEER_ANGLE STEER_ANGLE 0.3";
CM_ "CHFFR_METRIC 37 STEER_ANGLE STEER_ANGLE 0.36
CM_ "CHFFR_METRIC 37 STEER_ANGLE STEER_ANGLE 0.";
CM_ "CHFFR_METRIC 37 STEER_ANGLE STEER_ANGLE 0.3
CM_ "CHFFR_METRIC 37 STEER_ANGLE STEER_ANGLE 0.3";
CM_ "CHFFR_METRIC 37 STEER_ANGLE STEER_ANGLE 0.36
CM_ "CHFFR_METRIC 37 STEER_ANGLE STEER_ANGLE 0.3";
CM_ "CHFFR_METRIC 37 STEER_ANGLE STEER_ANGLE 0.36
CM_ "CHFFR_METRIC 37 STEER_ANGLE STEER_ANGLE 0.3";
CM_ "CHFFR_METRIC 37 STEER_ANGLE STEER_ANGLE 0.36
CM_ "CHFFR_METRIC 37 STEER_ANGLE STEER_ANGLE 0.36";
CM_ "CHFFR_METRIC 37 STEER_ANGLE STEER_ANGLE 0.36 
CM_ "CHFFR_METRIC 37 STEER_ANGLE STEER_ANGLE 0.36 ";
CM_ "CHFFR_METRIC 37 STEER_ANGLE STEER_ANGLE 0.36 1
CM_ "CHFFR_METRIC 37 STEER_ANGLE STEER_ANGLE 0.";
CM_ "CHFFR_METRIC 37 STEER_ANGLE STEER_ANGLE 0.3
CM_ "CHFFR_METRIC 37 STEER_ANGLE STEER_ANGLE 0.3";
CM_ "CHFFR_METRIC 37 STEER_ANGLE STEER_ANGLE 0.36
CM_ "CHFFR_METRIC 37 STEER_ANGLE STEER_ANGLE 0.";
CM_ "CHFFR_METRIC 37 STEER_ANGLE STEER_ANGLE 0.3
CM_ "CHFFR_METRIC 37 STEER_ANGLE STEER_ANGLE 0.3";
CM_ "CHFFR_METRIC 37 STEER_ANGLE STEER_ANGLE 0.36
CM_ "CHFFR_METRIC 37 STEER_ANGLE STEER_ANGLE 0.3";
CM_ "CHFFR_METRIC 37 STEER_ANGLE STEER_ANGLE 0.36
CM_ "CHFFR_METRIC 37 STEER_ANGLE STEER_ANGLE 0.3";
CM_ "CHFFR_METRIC 37 STEER_ANGLE STEER_ANGLE 0.36
CM_ "CHFFR_METRIC 37 STEER_ANGLE STEER_ANGLE 0.36";
CM_ "CHFFR_METRIC 37 STEER_ANGLE STEER_ANGLE 0.36 
CM_ "CHFFR_METRIC 37 STEER_ANGLE STEER_ANGLE 0.36 ";
CM_ "CHFFR_METRIC 37 STEER_ANGLE STEER_ANGLE 0.36 1
CM_ "CHFFR_METRIC 37 STEER_ANGLE STEER_ANGLE 0.3";
CM_ "CHFFR_METRIC 37 STEER_ANGLE STEER_ANGLE 0.36
CM_ "CHFFR_METRIC 37 STEER_ANGLE STEER_ANGLE 0.3";
CM_ "CHFFR_METRIC 37 STEER_ANGLE STEER_ANGLE 0.36
CM_ "CHFFR_METRIC 37 STEER_ANGLE STEER_ANGLE 0.36";
CM_ "CHFFR_METRIC 37 STEER_ANGLE STEER_ANGLE 0.36 
CM_ "CHFFR_METRIC 37 STEER_ANGLE STEER_ANGLE 0.36 ";
CM_ "CHFFR_METRIC 37 STEER_ANGLE STEER_ANGLE 0.36 1
CM_ "CHFFR_METRIC 37 STEER_ANGLE STEER_ANGLE 0.36";
CM_ "CHFFR_METRIC 37 STEER_ANGLE STEER_ANGLE 0.36 
CM_ "CHFFR_METRIC 37 STEER_ANGLE STEER_ANGLE 0.36 ";
CM_ "CHFFR_METRIC 37 STEER_ANGLE STEER_ANGLE 0.36 1
CM_ "CHFFR_METRIC 37 STEER_ANGLE STEER_ANGLE 0.36 ";
CM_ "CHFFR_METRIC 37 STEER_ANGLE STEER_ANGLE 0.36 1
CM_ "CHFFR_METRIC 37 STEER_ANGLE STEER_ANGLE 0.36 1";
CM_ "CHFFR_METRIC 37 STEER_ANGLE STEER_ANGLE 0.36 18
CM_ "CHFFR_METRIC 37 STEER_ANGLE STEER_ANGLE ";
CM_ "CHFFR_METRIC 37 STEER_ANGLE STEER_ANGLE 0
CM_ "CHFFR_METRIC 37 STEER_ANGLE STEER_ANGLE 0";
CM_ "CHFFR_METRIC 37 STEER_ANGLE STEER_ANGLE 0.
CM_ "CHFFR_METRIC 37 STEER_ANGLE STEER_ANGLE 0";
CM_ "CHFFR_METRIC 37 STEER_ANGLE STEER_ANGLE 0.
CM_ "CHFFR_METRIC 37 STEER_ANGLE STEER_ANGLE 0.";
CM_ "CHFFR_METRIC 37 STEER_ANGLE STEER_ANGLE 0.3
CM_ "CHFFR_METRIC 37 STEER_ANGLE STEER_ANGLE 0";
CM_ "CHFFR_METRIC 37 STEER_ANGLE STEER_ANGLE 0.
CM_ "CHFFR_METRIC 37 STEER_ANGLE STEER_ANGLE 0.";
CM_ "CHFFR_METRIC 37 STEER_ANGLE STEER_ANGLE 0.3
CM_ "CHFFR_METRIC 37 STEER_ANGLE STEER_ANGLE 0.";
CM_ "CHFFR_METRIC 37 STEER_ANGLE STEER_ANGLE 0.3
CM_ "CHFFR_METRIC 37 STEER_ANGLE STEER_ANGLE 0.3";
CM_ "CHFFR_METRIC 37 STEER_ANGLE STEER_ANGLE 0.36
CM_ "CHFFR_METRIC 37 STEER_ANGLE STEER_ANGLE ";
CM_ "CHFFR_METRIC 37 STEER_ANGLE STEER_ANGLE 0
CM_ "CHFFR_METRIC 37 STEER_ANGLE STEER_ANGLE 0";
CM_ "CHFFR_METRIC 37 STEER_ANGLE STEER_ANGLE 0.
CM_ "CHFFR_METRIC 37 STEER_ANGLE STEER_ANGLE 0";
CM_ "CHFFR_METRIC 37 STEER_ANGLE STEER_ANGLE 0.
CM_ "CHFFR_METRIC 37 STEER_ANGLE STEER_ANGLE 0.";
CM_ "CHFFR_METRIC 37 STEER_ANGLE STEER_ANGLE 0.3
CM_ "CHFFR_METRIC 37 STEER_ANGLE STEER_ANGLE 0";
CM_ "CHFFR_METRIC 37 STEER_ANGLE STEER_ANGLE 0.
CM_ "CHFFR_METRIC 37 STEER_ANGLE STEER_ANGLE 0.";
CM_ "CHFFR_METRIC 37 STEER_ANGLE STEER_ANGLE 0.3
CM_ "CHFFR_METRIC 37 STEER_ANGLE STEER_ANGLE 0.";
CM_ "CHFFR_METRIC 37 STEER_ANGLE STEER_ANGLE 0.3
CM_ "CHFFR_METRIC 37 STEER_ANGLE STEER_ANGLE 0.3";
CM_ "CHFFR_METRIC 37 STEER_ANGLE STEER_ANGLE 0.36
CM_ "CHFFR_METRIC 37 STEER_ANGLE STEER_ANGLE 0";
CM_ "CHFFR_METRIC 37 STEER_ANGLE STEER_ANGLE 0.
CM_ "CHFFR_METRIC 37 STEER_ANGLE STEER_ANGLE 0.";
CM_ "CHFFR_METRIC 37 STEER_ANGLE STEER_ANGLE 0.3
CM_ "CHFFR_METRIC 37 STEER_ANGLE STEER_ANGLE 0.";
CM_ "CHFFR_METRIC 37 STEER_ANGLE STEER_ANGLE 0.3
CM_ "CHFFR_METRIC 37 STEER_ANGLE STEER_ANGLE 0.3";
CM_ "CHFFR_METRIC 37 STEER_ANGLE STEER_ANGLE 0.36
CM_ "CHFFR_METRIC 37 STEER_ANGLE STEER_ANGLE 0";
CM_ "CHFFR_METRIC 37 STEER_ANGLE STEER_ANGLE 0.
CM_ "CHFFR_METRIC 37 STEER_ANGLE STEER_ANGLE 0.";
CM_ "CHFFR_METRIC 37 STEER_ANGLE STEER_ANGLE 0.3
CM_ "CHFFR_METRIC 37 STEER_ANGLE STEER_ANGLE 0.";
CM_ "CHFFR_METRIC 37 STEER_ANGLE STEER_ANGLE 0.3
CM_ "CHFFR_METRIC 37 STEER_ANGLE STEER_ANGLE 0.3";
CM_ "CHFFR_METRIC 37 STEER_ANGLE STEER_ANGLE 0.36
CM_ "CHFFR_METRIC 37 STEER_ANGLE STEER_ANGLE 0.";
CM_ "CHFFR_METRIC 37 STEER_ANGLE STEER_ANGLE 0.3
CM_ "CHFFR_METRIC 37 STEER_ANGLE STEER_ANGLE 0.3";
CM_ "CHFFR_METRIC 37 STEER_ANGLE STEER_ANGLE 0.36
CM_ "CHFFR_METRIC 37 STEER_ANGLE STEER_ANGLE 0.";
CM_ "CHFFR_METRIC 37 STEER_ANGLE STEER_ANGLE 0.3
CM_ "CHFFR_METRIC 37 STEER_ANGLE STEER_ANGLE 0.3";
CM_ "CHFFR_METRIC 37 STEER_ANGLE STEER_ANGLE 0.36
CM_ "CHFFR_METRIC 37 STEER_ANGLE STEER_ANGLE 0.3";
CM_ "CHFFR_METRIC 37 STEER_ANGLE STEER_ANGLE 0.36
CM_ "CHFFR_METRIC 37 STEER_ANGLE STEER_ANGLE 0.3";
CM_ "CHFFR_METRIC 37 STEER_ANGLE STEER_ANGLE 0.36
CM_ "CHFFR_METRIC 37 STEER_ANGLE STEER_ANGLE 0.36";
CM_ "CHFFR_METRIC 37 STEER_ANGLE STEER_ANGLE 0.36 
CM_ "CHFFR_METRIC 37 STEER_ANGLE STEER_ANGLE 0.36 ";
CM_ "CHFFR_METRIC 37 STEER_ANGLE STEER_ANGLE 0.36 1
CM_ "CHFFR_METRIC 37 STEER_ANGLE STEER_ANGLE 0";
CM_ "CHFFR_METRIC 37 STEER_ANGLE STEER_ANGLE 0.
CM_ "CHFFR_METRIC 37 STEER_ANGLE STEER_ANGLE 0.";
CM_ "CHFFR_METRIC 37 STEER_ANGLE STEER_ANGLE 0.3
CM_ "CHFFR_METRIC 37 STEER_ANGLE STEER_ANGLE 0.";
CM_ "CHFFR_METRIC 37 STEER_ANGLE STEER_ANGLE 0.3
CM_ "CHFFR_METRIC 37 STEER_ANGLE STEER_ANGLE 0.3";
CM_ "CHFFR_METRIC 37 STEER_ANGLE STEER_ANGLE 0.36
CM_ "CHFFR_METRIC 37 STEER_ANGLE STEER_ANGLE 0";
CM_ "CHFFR_METRIC 37 STEER_ANGLE STEER_ANGLE 0.
CM_ "CHFFR_METRIC 37 STEER_ANGLE STEER_ANGLE 0.";
CM_ "CHFFR_METRIC 37 STEER_ANGLE STEER_ANGLE 0.3
CM_ "CHFFR_METRIC 37 STEER_ANGLE STEER_ANGLE 0.";
CM_ "CHFFR_METRIC 37 STEER_ANGLE STEER_ANGLE 0.3
CM_ "CHFFR_METRIC 37 STEER_ANGLE STEER_ANGLE 0.3";
CM_ "CHFFR_METRIC 37 STEER_ANGLE STEER_ANGLE 0.36
CM_ "CHFFR_METRIC 37 STEER_ANGLE STEER_ANGLE 0.";
CM_ "CHFFR_METRIC 37 STEER_ANGLE STEER_ANGLE 0.3
CM_ "CHFFR_METRIC 37 STEER_ANGLE STEER_ANGLE 0.3";
CM_ "CHFFR_METRIC 37 STEER_ANGLE STEER_ANGLE 0.36
CM_ "CHFFR_METRIC 37 STEER_ANGLE STEER_ANGLE 0.";
CM_ "CHFFR_METRIC 37 STEER_ANGLE STEER_ANGLE 0.3
CM_ "CHFFR_METRIC 37 STEER_ANGLE STEER_ANGLE 0.3";
CM_ "CHFFR_METRIC 37 STEER_ANGLE STEER_ANGLE 0.36
CM_ "CHFFR_METRIC 37 STEER_ANGLE STEER_ANGLE 0.3";
CM_ "CHFFR_METRIC 37 STEER_ANGLE STEER_ANGLE 0.36
CM_ "CHFFR_METRIC 37 STEER_ANGLE STEER_ANGLE 0.3";
CM_ "CHFFR_METRIC 37 STEER_ANGLE STEER_ANGLE 0.36
CM_ "CHFFR_METRIC 37 STEER_ANGLE STEER_ANGLE 0.36";
CM_ "CHFFR_METRIC 37 STEER_ANGLE STEER_ANGLE 0.36 
CM_ "CHFFR_METRIC 37 STEER_ANGLE STEER_ANGLE 0.36 ";
CM_ "CHFFR_METRIC 37 STEER_ANGLE STEER_ANGLE 0.36 1
CM_ "CHFFR_METRIC 37 STEER_ANGLE STEER_ANGLE 0.";
CM_ "CHFFR_METRIC 37 STEER_ANGLE STEER_ANGLE 0.3
CM_ "CHFFR_METRIC 37 STEER_ANGLE STEER_ANGLE 0.3";
CM_ "CHFFR_METRIC 37 STEER_ANGLE STEER_ANGLE 0.36
CM_ "CHFFR_METRIC 37 STEER_ANGLE STEER_ANGLE 0.";
CM_ "CHFFR_METRIC 37 STEER_ANGLE STEER_ANGLE 0.3
CM_ "CHFFR_METRIC 37 STEER_ANGLE STEER_ANGLE 0.3";
CM_ "CHFFR_METRIC 37 STEER_ANGLE STEER_ANGLE 0.36
CM_ "CHFFR_METRIC 37 STEER_ANGLE STEER_ANGLE 0.3";
CM_ "CHFFR_METRIC 37 STEER_ANGLE STEER_ANGLE 0.36
CM_ "CHFFR_METRIC 37 STEER_ANGLE STEER_ANGLE 0.3";
CM_ "CHFFR_METRIC 37 STEER_ANGLE STEER_ANGLE 0.36
CM_ "CHFFR_METRIC 37 STEER_ANGLE STEER_ANGLE 0.36";
CM_ "CHFFR_METRIC 37 STEER_ANGLE STEER_ANGLE 0.36 
CM_ "CHFFR_METRIC 37 STEER_ANGLE STEER_ANGLE 0.36 ";
CM_ "CHFFR_METRIC 37 STEER_ANGLE STEER_ANGLE 0.36 1
CM_ "CHFFR_METRIC 37 STEER_ANGLE STEER_ANGLE 0.3";
CM_ "CHFFR_METRIC 37 STEER_ANGLE STEER_ANGLE 0.36
CM_ "CHFFR_METRIC 37 STEER_ANGLE STEER_ANGLE 0.3";
CM_ "CHFFR_METRIC 37 STEER_ANGLE STEER_ANGLE 0.36
CM_ "CHFFR_METRIC 37 STEER_ANGLE STEER_ANGLE 0.36";
CM_ "CHFFR_METRIC 37 STEER_ANGLE STEER_ANGLE 0.36 
CM_ "CHFFR_METRIC 37 STEER_ANGLE STEER_ANGLE 0.36 ";
CM_ "CHFFR_METRIC 37 STEER_ANGLE STEER_ANGLE 0.36 1
CM_ "CHFFR_METRIC 37 STEER_ANGLE STEER_ANGLE 0.36";
CM_ "CHFFR_METRIC 37 STEER_ANGLE STEER_ANGLE 0.36 
CM_ "CHFFR_METRIC 37 STEER_ANGLE STEER_ANGLE 0.36 ";
CM_ "CHFFR_METRIC 37 STEER_ANGLE STEER_ANGLE 0.36 1
CM_ "CHFFR_METRIC 37 STEER_ANGLE STEER_ANGLE 0.36 ";
CM_ "CHFFR_METRIC 37 STEER_ANGLE STEER_ANGLE 0.36 1
CM_ "CHFFR_METRIC 37 STEER_ANGLE STEER_ANGLE 0.36 1";
CM_ "CHFFR_METRIC 37 STEER_ANGLE STEER_ANGLE 0.36 18
CM_ "CHFFR_METRIC 37 STEER_ANGLE STEER_ANGLE 0";
CM_ "CHFFR_METRIC 37 STEER_ANGLE STEER_ANGLE 0.
CM_ "CHFFR_METRIC 37 STEER_ANGLE STEER_ANGLE 0.";
CM_ "CHFFR_METRIC 37 STEER_ANGLE STEER_ANGLE 0.3
CM_ "CHFFR_METRIC 37 STEER_ANGLE STEER_ANGLE 0.";
CM_ "CHFFR_METRIC 37 STEER_ANGLE STEER_ANGLE 0.3
CM_ "CHFFR_METRIC 37 STEER_ANGLE STEER_ANGLE 0.3";
CM_ "CHFFR_METRIC 37 STEER_ANGLE STEER_ANGLE 0.36
CM_ "CHFFR_METRIC 37 STEER_ANGLE STEER_ANGLE 0";
CM_ "CHFFR_METRIC 37 STEER_ANGLE STEER_ANGLE 0.
CM_ "CHFFR_METRIC 37 STEER_ANGLE STEER_ANGLE 0.";
CM_ "CHFFR_METRIC 37 STEER_ANGLE STEER_ANGLE 0.3
CM_ "CHFFR_METRIC 37 STEER_ANGLE STEER_ANGLE 0.";
CM_ "CHFFR_METRIC 37 STEER_ANGLE STEER_ANGLE 0.3
CM_ "CHFFR_METRIC 37 STEER_ANGLE STEER_ANGLE 0.3";
CM_ "CHFFR_METRIC 37 STEER_ANGLE STEER_ANGLE 0.36
CM_ "CHFFR_METRIC 37 STEER_ANGLE STEER_ANGLE 0.";
CM_ "CHFFR_METRIC 37 STEER_ANGLE STEER_ANGLE 0.3
CM_ "CHFFR_METRIC 37 STEER_ANGLE STEER_ANGLE 0.3";
CM_ "CHFFR_METRIC 37 STEER_ANGLE STEER_ANGLE 0.36
CM_ "CHFFR_METRIC 37 STEER_ANGLE STEER_ANGLE 0.";
CM_ "CHFFR_METRIC 37 STEER_ANGLE STEER_ANGLE 0.3
CM_ "CHFFR_METRIC 37 STEER_ANGLE STEER_ANGLE 0.3";
CM_ "CHFFR_METRIC 37 STEER_ANGLE STEER_ANGLE 0.36
CM_ "CHFFR_METRIC 37 STEER_ANGLE STEER_ANGLE 0.3";
CM_ "CHFFR_METRIC 37 STEER_ANGLE STEER_ANGLE 0.36
CM_ "CHFFR_METRIC 37 STEER_ANGLE STEER_ANGLE 0.3";
CM_ "CHFFR_METRIC 37 STEER_ANGLE STEER_ANGLE 0.36
CM_ "CHFFR_METRIC 37 STEER_ANGLE STEER_ANGLE 0.36";
CM_ "CHFFR_METRIC 37 STEER_ANGLE STEER_ANGLE 0.36 
CM_ "CHFFR_METRIC 37 STEER_ANGLE STEER_ANGLE 0.36 ";
CM_ "CHFFR_METRIC 37 STEER_ANGLE STEER_ANGLE 0.36 1
CM_ "CHFFR_METRIC 37 STEER_ANGLE STEER_ANGLE 0.";
CM_ "CHFFR_METRIC 37 STEER_ANGLE STEER_ANGLE 0.3
CM_ "CHFFR_METRIC 37 STEER_ANGLE STEER_ANGLE 0.3";
CM_ "CHFFR_METRIC 37 STEER_ANGLE STEER_ANGLE 0.36
CM_ "CHFFR_METRIC 37 STEER_ANGLE STEER_ANGLE 0.";
CM_ "CHFFR_METRIC 37 STEER_ANGLE STEER_ANGLE 0.3
CM_ "CHFFR_METRIC 37 STEER_ANGLE STEER_ANGLE 0.3";
CM_ "CHFFR_METRIC 37 STEER_ANGLE STEER_ANGLE 0.36
CM_ "CHFFR_METRIC 37 STEER_ANGLE STEER_ANGLE 0.3";
CM_ "CHFFR_METRIC 37 STEER_ANGLE STEER_ANGLE 0.36
CM_ "CHFFR_METRIC 37 STEER_ANGLE STEER_ANGLE 0.3";
CM_ "CHFFR_METRIC 37 STEER_ANGLE STEER_ANGLE 0.36
CM_ "CHFFR_METRIC 37 STEER_ANGLE STEER_ANGLE 0.36";
CM_ "CHFFR_METRIC 37 STEER_ANGLE STEER_ANGLE 0.36 
CM_ "CHFFR_METRIC 37 STEER_ANGLE STEER_ANGLE 0.36 ";
CM_ "CHFFR_METRIC 37 STEER_ANGLE STEER_ANGLE 0.36 1
CM_ "CHFFR_METRIC 37 STEER_ANGLE STEER_ANGLE 0.3";
CM_ "CHFFR_METRIC 37 STEER_ANGLE STEER_ANGLE 0.36
CM_ "CHFFR_METRIC 37 STEER_ANGLE STEER_ANGLE 0.3";
CM_ "CHFFR_METRIC 37 STEER_ANGLE STEER_ANGLE 0.36
CM_ "CHFFR_METRIC 37 STEER_ANGLE STEER_ANGLE 0.36";
CM_ "CHFFR_METRIC 37 STEER_ANGLE STEER_ANGLE 0.36 
CM_ "CHFFR_METRIC 37 STEER_ANGLE STEER_ANGLE 0.36 ";
CM_ "CHFFR_METRIC 37 STEER_ANGLE STEER_ANGLE 0.36 1
CM_ "CHFFR_METRIC 37 STEER_ANGLE STEER_ANGLE 0.36";
CM_ "CHFFR_METRIC 37 STEER_ANGLE STEER_ANGLE 0.36 
CM_ "CHFFR_METRIC 37 STEER_ANGLE STEER_ANGLE 0.36 ";
CM_ "CHFFR_METRIC 37 STEER_ANGLE STEER_ANGLE 0.36 1
CM_ "CHFFR_METRIC 37 STEER_ANGLE STEER_ANGLE 0.36 ";
CM_ "CHFFR_METRIC 37 STEER_ANGLE STEER_ANGLE 0.36 1
CM_ "CHFFR_METRIC 37 STEER_ANGLE STEER_ANGLE 0.36 1";
CM_ "CHFFR_METRIC 37 STEER_ANGLE STEER_ANGLE 0.36 18
CM_ "CHFFR_METRIC 37 STEER_ANGLE STEER_ANGLE 0.";
CM_ "CHFFR_METRIC 37 STEER_ANGLE STEER_ANGLE 0.3
CM_ "CHFFR_METRIC 37 STEER_ANGLE STEER_ANGLE 0.3";
CM_ "CHFFR_METRIC 37 STEER_ANGLE STEER_ANGLE 0.36
CM_ "CHFFR_METRIC 37 STEER_ANGLE STEER_ANGLE 0.";
CM_ "CHFFR_METRIC 37 STEER_ANGLE STEER_ANGLE 0.3
CM_ "CHFFR_METRIC 37 STEER_ANGLE STEER_ANGLE 0.3";
CM_ "CHFFR_METRIC 37 STEER_ANGLE STEER_ANGLE 0.36
CM_ "CHFFR_METRIC 37 STEER_ANGLE STEER_ANGLE 0.3";
CM_ "CHFFR_METRIC 37 STEER_ANGLE STEER_ANGLE 0.36
CM_ "CHFFR_METRIC 37 STEER_ANGLE STEER_ANGLE 0.3";
CM_ "CHFFR_METRIC 37 STEER_ANGLE STEER_ANGLE 0.36
CM_ "CHFFR_METRIC 37 STEER_ANGLE STEER_ANGLE 0.36";
CM_ "CHFFR_METRIC 37 STEER_ANGLE STEER_ANGLE 0.36 
CM_ "CHFFR_METRIC 37 STEER_ANGLE STEER_ANGLE 0.36 ";
CM_ "CHFFR_METRIC 37 STEER_ANGLE STEER_ANGLE 0.36 1
CM_ "CHFFR_METRIC 37 STEER_ANGLE STEER_ANGLE 0.3";
CM_ "CHFFR_METRIC 37 STEER_ANGLE STEER_ANGLE 0.36
CM_ "CHFFR_METRIC 37 STEER_ANGLE STEER_ANGLE 0.3";
CM_ "CHFFR_METRIC 37 STEER_ANGLE STEER_ANGLE 0.36
CM_ "CHFFR_METRIC 37 STEER_ANGLE STEER_ANGLE 0.36";
CM_ "CHFFR_METRIC 37 STEER_ANGLE STEER_ANGLE 0.36 
CM_ "CHFFR_METRIC 37 STEER_ANGLE STEER_ANGLE 0.36 ";
CM_ "CHFFR_METRIC 37 STEER_ANGLE STEER_ANGLE 0.36 1
CM_ "CHFFR_METRIC 37 STEER_ANGLE STEER_ANGLE 0.36";
CM_ "CHFFR_METRIC 37 STEER_ANGLE STEER_ANGLE 0.36 
CM_ "CHFFR_METRIC 37 STEER_ANGLE STEER_ANGLE 0.36 ";
CM_ "CHFFR_METRIC 37 STEER_ANGLE STEER_ANGLE 0.36 1
CM_ "CHFFR_METRIC 37 STEER_ANGLE STEER_ANGLE 0.36 ";
CM_ "CHFFR_METRIC 37 STEER_ANGLE STEER_ANGLE 0.36 1
CM_ "CHFFR_METRIC 37 STEER_ANGLE STEER_ANGLE 0.36 1";
CM_ "CHFFR_METRIC 37 STEER_ANGLE STEER_ANGLE 0.36 18
CM_ "CHFFR_METRIC 37 STEER_ANGLE STEER_ANGLE 0.3";
CM_ "CHFFR_METRIC 37 STEER_ANGLE STEER_ANGLE 0.36
CM_ "CHFFR_METRIC 37 STEER_ANGLE STEER_ANGLE 0.3";
CM_ "CHFFR_METRIC 37 STEER_ANGLE STEER_ANGLE 0.36
CM_ "CHFFR_METRIC 37 STEER_ANGLE STEER_ANGLE 0.36";
CM_ "CHFFR_METRIC 37 STEER_ANGLE STEER_ANGLE 0.36 
CM_ "CHFFR_METRIC 37 STEER_ANGLE STEER_ANGLE 0.36 ";
CM_ "CHFFR_METRIC 37 STEER_ANGLE STEER_ANGLE 0.36 1
CM_ "CHFFR_METRIC 37 STEER_ANGLE STEER_ANGLE 0.36";
CM_ "CHFFR_METRIC 37 STEER_ANGLE STEER_ANGLE 0.36 
CM_ "CHFFR_METRIC 37 STEER_ANGLE STEER_ANGLE 0.36 ";
CM_ "CHFFR_METRIC 37 STEER_ANGLE STEER_ANGLE 0.36 1
CM_ "CHFFR_METRIC 37 STEER_ANGLE STEER_ANGLE 0.36 ";
CM_ "CHFFR_METRIC 37 STEER_ANGLE STEER_ANGLE 0.36 1
CM_ "CHFFR_METRIC 37 STEER_ANGLE STEER_ANGLE 0.36 1";
CM_ "CHFFR_METRIC 37 STEER_ANGLE STEER_ANGLE 0.36 18
CM_ "CHFFR_METRIC 37 STEER_ANGLE STEER_ANGLE 0.36";
CM_ "CHFFR_METRIC 37 STEER_ANGLE STEER_ANGLE 0.36 
CM_ "CHFFR_METRIC 37 STEER_ANGLE STEER_ANGLE 0.36 ";
CM_ "CHFFR_METRIC 37 STEER_ANGLE STEER_ANGLE 0.36 1
CM_ "CHFFR_METRIC 37 STEER_ANGLE STEER_ANGLE 0.36 ";
CM_ "CHFFR_METRIC 37 STEER_ANGLE STEER_ANGLE 0.36 1
CM_ "CHFFR_METRIC 37 STEER_ANGLE STEER_ANGLE 0.36 1";
CM_ "CHFFR_METRIC 37 STEER_ANGLE STEER_ANGLE 0.36 18
CM_ "CHFFR_METRIC 37 STEER_ANGLE STEER_ANGLE 0.36 ";
CM_ "CHFFR_METRIC 37 STEER_ANGLE STEER_ANGLE 0.36 1
CM_ "CHFFR_METRIC 37 STEER_ANGLE STEER_ANGLE 0.36 1";
CM_ "CHFFR_METRIC 37 STEER_ANGLE STEER_ANGLE 0.36 18
CM_ "CHFFR_METRIC 37 STEER_ANGLE STEER_ANGLE 0.36 1";
CM_ "CHFFR_METRIC 37 STEER_ANGLE STEER_ANGLE 0.36 18
CM_ "CHFFR_METRIC 37 STEER_ANGLE STEER_ANGLE 0.36 18";
CM_ "CHFFR_METRIC 37 STEER_ANGLE STEER_ANGLE 0.36 180
CM_ "toyota_prius_2017_pt.dbc sta";
CM_ "toyota_prius_2017_pt.dbc star
CM_ "toyota_prius_2017_pt.dbc star";
CM_ "toyota_prius_2017_pt.dbc start
CM_ "toyota_prius_2017_pt.dbc star";
CM_ "toyota_prius_2017_pt.dbc start
CM_ "toyota_prius_2017_pt.dbc start";
CM_ "toyota_prius_2017_pt.dbc starts
CM_ "toyota_prius_2017_pt.dbc sta";
CM_ "toyota_prius_2017_pt.dbc star
CM_ "toyota_prius_2017_pt.dbc star";
CM_ "toyota_prius_2017_pt.dbc start
CM_ "toyota_prius_2017_pt.dbc star";
CM_ "toyota_prius_2017_pt.dbc start
CM_ "toyota_prius_2017_pt.dbc start";
CM_ "toyota_prius_2017_pt.dbc starts
CM_ "toyota_prius_2017_pt.dbc star";
CM_ "toyota_prius_2017_pt.dbc start
CM_ "toyota_prius_2017_pt.dbc start";
CM_ "toyota_prius_2017_pt.dbc starts
CM_ "toyota_prius_2017_pt.dbc star";
CM_ "toyota_prius_2017_pt.dbc start
CM_ "toyota_prius_2017_pt.dbc start";
CM_ "toyota_prius_2017_pt.dbc starts
CM_ "toyota_prius_2017_pt.dbc start";
CM_ "toyota_prius_2017_pt.dbc starts
CM_ "toyota_prius_2017_pt.dbc start";
CM_ "toyota_prius_2017_pt.dbc starts
CM_ "toyota_prius_2017_pt.dbc starts";
CM_ "toyota_prius_2017_pt.dbc starts 
CM_ "toyota_prius_2017_pt.dbc starts ";
CM_ "toyota_prius_2017_pt.dbc starts h
CM_ "toyota_prius_2017_pt.dbc star";
CM_ "toyota_prius_2017_pt.dbc start
CM_ "toyota_prius_2017_pt.dbc start";
CM_ "toyota_prius_2017_pt.dbc starts
CM_ "toyota_prius_2017_pt.dbc star";
CM_ "toyota_prius_2017_pt.dbc start
CM_ "toyota_prius_2017_pt.dbc start";
CM_ "toyota_prius_2017_pt.dbc starts
CM_ "toyota_prius_2017_pt.dbc start";
CM_ "toyota_prius_2017_pt.dbc starts
CM_ "toyota_prius_2017_pt.dbc start";
CM_ "toyota_prius_2017_pt.dbc starts
CM_ "toyota_prius_2017_pt.dbc starts";
CM_ "toyota_prius_2017_pt.dbc starts 
CM_ "toyota_prius_2017_pt.dbc starts ";
CM_ "toyota_prius_2017_pt.dbc starts h
CM_ "toyota_prius_2017_pt.dbc start";
CM_ "toyota_prius_2017_pt.dbc starts
CM_ "toyota_prius_2017_pt.dbc start";
CM_ "toyota_prius_2017_pt.dbc starts
CM_ "toyota_prius_2017_pt.dbc starts";
CM_ "toyota_prius_2017_pt.dbc starts 
CM_ "toyota_prius_2017_pt.dbc starts ";
CM_ "toyota_prius_2017_pt.dbc starts h
CM_ "toyota_prius_2017_pt.dbc starts";
CM_ "toyota_prius_2017_pt.dbc starts 
CM_ "toyota_prius_2017_pt.dbc starts ";
CM_ "toyota_prius_2017_pt.dbc starts h
CM_ "toyota_prius_2017_pt.dbc starts ";
CM_ "toyota_prius_2017_pt.dbc starts h
CM_ "toyota_prius_2017_pt.dbc starts h";
CM_ "toyota_prius_2017_pt.dbc starts he
CM_ "toyota_prius_2017_pt.dbc star";
CM_ "toyota_prius_2017_pt.dbc start
CM_ "toyota_prius_2017_pt.dbc start";
CM_ "toyota_prius_2017_pt.dbc starts
CM_ "toyota_prius_2017_pt.dbc star";
CM_ "toyota_prius_2017_pt.dbc start
CM_ "toyota_prius_2017_pt.dbc start";
CM_ "toyota_prius_2017_pt.dbc starts
CM_ "toyota_prius_2017_pt.dbc start";
CM_ "toyota_prius_2017_pt.dbc starts
CM_ "toyota_prius_2017_pt.dbc start";
CM_ "toyota_prius_2017_pt.dbc starts
CM_ "toyota_prius_2017_pt.dbc starts";
CM_ "toyota_prius_2017_pt.dbc starts 
CM_ "toyota_prius_2017_pt.dbc starts ";
CM_ "toyota_prius_2017_pt.dbc starts h
CM_ "toyota_prius_2017_pt.dbc start";
CM_ "toyota_prius_2017_pt.dbc starts
CM_ "toyota_prius_2017_pt.dbc start";
CM_ "toyota_prius_2017_pt.dbc starts
CM_ "toyota_prius_2017_pt.dbc starts";
CM_ "toyota_prius_2017_pt.dbc starts 
CM_ "toyota_prius_2017_pt.dbc starts ";
CM_ "toyota_prius_2017_pt.dbc starts h
CM_ "toyota_prius_2017_pt.dbc starts";
CM_ "toyota_prius_2017_pt.dbc starts 
CM_ "toyota_prius_2017_pt.dbc starts ";
CM_ "toyota_prius_2017_pt.dbc starts h
CM_ "toyota_prius_2017_pt.dbc starts ";
CM_ "toyota_prius_2017_pt.dbc starts h
CM_ "toyota_prius_2017_pt.dbc starts h";
CM_ "toyota_prius_2017_pt.dbc starts he
CM_ "toyota_prius_2017_pt.dbc start";
CM_ "toyota_prius_2017_pt.dbc starts
CM_ "toyota_prius_2017_pt.dbc start";
CM_ "toyota_prius_2017_pt.dbc starts
CM_ "toyota_prius_2017_pt.dbc starts";
CM_ "toyota_prius_2017_pt.dbc starts 
CM_ "toyota_prius_2017_pt.dbc starts ";
CM_ "toyota_prius_2017_pt.dbc starts h
CM_ "toyota_prius_2017_pt.dbc starts";
CM_ "toyota_prius_2017_pt.dbc starts 
CM_ "toyota_prius_2017_pt.dbc starts ";
CM_ "toyota_prius_2017_pt.dbc starts h
CM_ "toyota_prius_2017_pt.dbc starts ";
CM_ "toyota_prius_2017_pt.dbc starts h
CM_ "toyota_prius_2017_pt.dbc starts h";
CM_ "toyota_prius_2017_pt.dbc starts he
CM_ "toyota_prius_2017_pt.dbc starts";
CM_ "toyota_prius_2017_pt.dbc starts 
CM_ "toyota_prius_2017_pt.dbc starts ";
CM_ "toyota_prius_2017_pt.dbc starts h
CM_ "toyota_prius_2017_pt.dbc starts ";
CM_ "toyota_prius_2017_pt.dbc starts h
CM_ "toyota_prius_2017_pt.dbc starts h";
CM_ "toyota_prius_2017_pt.dbc starts he
CM_ "toyota_prius_2017_pt.dbc starts ";
CM_ "toyota_prius_2017_pt.dbc starts h
CM_ "toyota_prius_2017_pt.dbc starts h";
CM_ "toyota_prius_2017_pt.dbc starts he
CM_ "toyota_prius_2017_pt.dbc starts h";
CM_ "toyota_prius_2017_pt.dbc starts he
CM_ "toyota_prius_2017_pt.dbc starts he";
CM_ "toyota_prius_2017_pt.dbc starts her
CM_ "toyota_prius_2017_pt.dbc star";
CM_ "toyota_prius_2017_pt.dbc start
CM_ "toyota_prius_2017_pt.dbc start";
CM_ "toyota_prius_2017_pt.dbc starts
CM_ "toyota_prius_2017_pt.dbc star";
CM_ "toyota_prius_2017_pt.dbc start
CM_ "toyota_prius_2017_pt.dbc start";
CM_ "toyota_prius_2017_pt.dbc starts
CM_ "toyota_prius_2017_pt.dbc start";
CM_ "toyota_prius_2017_pt.dbc starts
CM_ "toyota_prius_2017_pt.dbc start";
CM_ "toyota_prius_2017_pt.dbc starts
CM_ "toyota_prius_2017_pt.dbc starts";
CM_ "toyota_prius_2017_pt.dbc starts 
CM_ "toyota_prius_2017_pt.dbc starts ";
CM_ "toyota_prius_2017_pt.dbc starts h
CM_ "toyota_prius_2017_pt.dbc start";
CM_ "toyota_prius_2017_pt.dbc starts
CM_ "toyota_prius_2017_pt.dbc start";
CM_ "toyota_prius_2017_pt.dbc starts
CM_ "toyota_prius_2017_pt.dbc starts";
CM_ "toyota_prius_2017_pt.dbc starts 
CM_ "toyota_prius_2017_pt.dbc starts ";
CM_ "toyota_prius_2017_pt.dbc starts h
CM_ "toyota_prius_2017_pt.dbc starts";
CM_ "toyota_prius_2017_pt.dbc starts 
CM_ "toyota_prius_2017_pt.dbc starts ";
CM_ "toyota_prius_2017_pt.dbc starts h
CM_ "toyota_prius_2017_pt.dbc starts ";
CM_ "toyota_prius_2017_pt.dbc starts h
CM_ "toyota_prius_2017_pt.dbc starts h";
CM_ "toyota_prius_2017_pt.dbc starts he
CM_ "toyota_prius_2017_pt.dbc start";
CM_ "toyota_prius_2017_pt.dbc starts
CM_ "toyota_prius_2017_pt.dbc start";
CM_ "toyota_prius_2017_pt.dbc starts
CM_ "toyota_prius_2017_pt.dbc starts";
CM_ "toyota_prius_2017_pt.dbc starts 
CM_ "toyota_prius_2017_pt.dbc starts ";
CM_ "toyota_prius_2017_pt.dbc starts h
CM_ "toyota_prius_2017_pt.dbc starts";
CM_ "toyota_prius_2017_pt.dbc starts 
CM_ "toyota_prius_2017_pt.dbc starts ";
CM_ "toyota_prius_2017_pt.dbc starts h
CM_ "toyota_prius_2017_pt.dbc starts ";
CM_ "toyota_prius_2017_pt.dbc starts h
CM_ "toyota_prius_2017_pt.dbc starts h";
CM_ "toyota_prius_2017_pt.dbc starts he
CM_ "toyota_prius_2017_pt.dbc starts";
CM_ "toyota_prius_2017_pt.dbc starts 
CM_ "toyota_prius_2017_pt.dbc starts ";
CM_ "toyota_prius_2017_pt.dbc starts h
CM_ "toyota_prius_2017_pt.dbc starts ";
CM_ "toyota_prius_2017_pt.dbc starts h
CM_ "toyota_prius_2017_pt.dbc starts h";
CM_ "toyota_prius_2017_pt.dbc starts he
CM_ "toyota_prius_2017_pt.dbc starts ";
CM_ "toyota_prius_2017_pt.dbc starts h
CM_ "toyota_prius_2017_pt.dbc starts h";
CM_ "toyota_prius_2017_pt.dbc starts he
CM_ "toyota_prius_2017_pt.dbc starts h";
CM_ "toyota_prius_2017_pt.dbc starts he
CM_ "toyota_prius_2017_pt.dbc starts he";
CM_ "toyota_prius_2017_pt.dbc starts her
CM_ "toyota_prius_2017_pt.dbc start";
CM_ "toyota_prius_2017_pt.dbc starts
CM_ "toyota_prius_2017_pt.dbc start";
CM_ "toyota_prius_2017_pt.dbc starts
CM_ "toyota_prius_2017_pt.dbc starts";
CM_ "toyota_prius_2017_pt.dbc starts 
CM_ "toyota_prius_2017_pt.dbc starts ";
CM_ "toyota_prius_2017_pt.dbc starts h
CM_ "toyota_prius_2017_pt.dbc starts";
CM_ "toyota_prius_2017_pt.dbc starts 
CM_ "toyota_prius_2017_pt.dbc starts ";
CM_ "toyota_prius_2017_pt.dbc starts h
CM_ "toyota_prius_2017_pt.dbc starts ";
CM_ "toyota_prius_2017_pt.dbc starts h
CM_ "toyota_prius_2017_pt.dbc starts h";
CM_ "toyota_prius_2017_pt.dbc starts he
CM_ "toyota_prius_2017_pt.dbc starts";
CM_ "toyota_prius_2017_pt.dbc starts 
CM_ "toyota_prius_2017_pt.dbc starts ";
CM_ "toyota_prius_2017_pt.dbc starts h
CM_ "toyota_prius_2017_pt.dbc starts ";
CM_ "toyota_prius_2017_pt.dbc starts h
CM_ "toyota_prius_2017_pt.dbc starts h";
CM_ "toyota_prius_2017_pt.dbc starts he
CM_ "toyota_prius_2017_pt.dbc starts ";
CM_ "toyota_prius_2017_pt.dbc starts h
CM_ "toyota_prius_2017_pt.dbc starts h";
CM_ "toyota_prius_2017_pt.dbc starts he
CM_ "toyota_prius_2017_pt.dbc starts h";
CM_ "toyota_prius_2017_pt.dbc starts he
CM_ "toyota_prius_2017_pt.dbc starts he";
CM_ "toyota_prius_2017_pt.dbc starts her
CM_ "toyota_prius_2017_pt.dbc starts";
CM_ "toyota_prius_2017_pt.dbc starts 
CM_ "toyota_prius_2017_pt.dbc starts ";
CM_ "toyota_prius_2017_pt.dbc starts h
CM_ "toyota_prius_2017_pt.dbc starts ";
CM_ "toyota_prius_2017_pt.dbc starts h
CM_ "toyota_prius_2017_pt.dbc starts h";
CM_ "toyota_prius_2017_pt.dbc starts he
CM_ "toyota_prius_2017_pt.dbc starts ";
CM_ "toyota_prius_2017_pt.dbc starts h
CM_ "toyota_prius_2017_pt.dbc starts h";
CM_ "toyota_prius_2017_pt.dbc starts he
CM_ "toyota_prius_2017_pt.dbc starts h";
CM_ "toyota_prius_2017_pt.dbc starts he
CM_ "toyota_prius_2017_pt.dbc starts he";
CM_ "toyota_prius_2017_pt.dbc starts her
CM_ "toyota_prius_2017_pt.dbc starts ";
CM_ "toyota_prius_2017_pt.dbc starts h
CM_ "toyota_prius_2017_pt.dbc starts h";
CM_ "toyota_prius_2017_pt.dbc starts he
CM_ "toyota_prius_2017_pt.dbc starts h";
CM_ "toyota_prius_2017_pt.dbc starts he
CM_ "toyota_prius_2017_pt.dbc starts he";
CM_ "toyota_prius_2017_pt.dbc starts her
CM_ "toyota_prius_2017_pt.dbc starts h";
CM_ "toyota_prius_2017_pt.dbc starts he
CM_ "toyota_prius_2017_pt.dbc starts he";
CM_ "toyota_prius_2017_pt.dbc starts her
CM_ "toyota_prius_2017_pt.dbc starts he";
CM_ "toyota_prius_2017_pt.dbc starts her
CM_ "toyota_prius_2017_pt.dbc starts her";
CM_ "toyota_prius_2017_pt.dbc starts here
CM_ "toyota_prius_2017_pt.dbc star";
CM_ "toyota_prius_2017_pt.dbc start
CM_ "toyota_prius_2017_pt.dbc start";
CM_ "toyota_prius_2017_pt.dbc starts
CM_ "toyota_prius_2017_pt.dbc star";
CM_ "toyota_prius_2017_pt.dbc start
CM_ "toyota_prius_2017_pt.dbc start";
CM_ "toyota_prius_2017_pt.dbc starts
CM_ "toyota_prius_2017_pt.dbc start";
CM_ "toyota_prius_2017_pt.dbc starts
CM_ "toyota_prius_2017_pt.dbc start";
CM_ "toyota_prius_2017_pt.dbc starts
CM_ "toyota_prius_2017_pt.dbc starts";
CM_ "toyota_prius_2017_pt.dbc starts 
CM_ "toyota_prius_2017_pt.dbc starts ";
CM_ "toyota_prius_2017_pt.dbc starts h
CM_ "toyota_prius_2017_pt.dbc start";
CM_ "toyota_prius_2017_pt.dbc starts
CM_ "toyota_prius_2017_pt.dbc start";
CM_ "toyota_prius_2017_pt.dbc starts
CM_ "toyota_prius_2017_pt.dbc starts";
CM_ "toyota_prius_2017_pt.dbc starts 
CM_ "toyota_prius_2017_pt.dbc starts ";
CM_ "toyota_prius_2017_pt.dbc starts h
CM_ "toyota_prius_2017_pt.dbc starts";
CM_ "toyota_prius_2017_pt.dbc starts 
CM_ "toyota_prius_2017_pt.dbc starts ";
CM_ "toyota_prius_2017_pt.dbc starts h
CM_ "toyota_prius_2017_pt.dbc starts ";
CM_ "toyota_prius_2017_pt.dbc starts h
CM_ "toyota_prius_2017_pt.dbc starts h";
CM_ "toyota_prius_2017_pt.dbc starts he
CM_ "toyota_prius_2017_pt.dbc start";
CM_ "toyota_prius_2017_pt.dbc starts
CM_ "toyota_prius_2017_pt.dbc start";
CM_ "toyota_prius_2017_pt.dbc starts
CM_ "toyota_prius_2017_pt.dbc starts";
CM_ "toyota_prius_2017_pt.dbc starts 
CM_ "toyota_prius_2017_pt.dbc starts ";
CM_ "toyota_prius_2017_pt.dbc starts h
CM_ "toyota_prius_2017_pt.dbc starts";
CM_ "toyota_prius_2017_pt.dbc starts 
CM_ "toyota_prius_2017_pt.dbc starts ";
CM_ "toyota_prius_2017_pt.dbc starts h
CM_ "toyota_prius_2017_pt.dbc starts ";
CM_ "toyota_prius_2017_pt.dbc starts h
CM_ "toyota_prius_2017_pt.dbc starts h";
CM_ "toyota_prius_2017_pt.dbc starts he
CM_ "toyota_prius_2017_pt.dbc starts";
CM_ "toyota_prius_2017_pt.dbc starts 
CM_ "toyota_prius_2017_pt.dbc starts ";
CM_ "toyota_prius_2017_pt.dbc starts h
CM_ "toyota_prius_2017_pt.dbc starts ";
CM_ "toyota_prius_2017_pt.dbc starts h
CM_ "toyota_prius_2017_pt.dbc starts h";
CM_ "toyota_prius_2017_pt.dbc starts he
CM_ "toyota_prius_2017_pt.dbc starts ";
CM_ "toyota_prius_2017_pt.dbc starts h
CM_ "toyota_prius_2017_pt.dbc starts h";
CM_ "toyota_prius_2017_pt.dbc starts he
CM_ "toyota_prius_2017_pt.dbc starts h";
CM_ "toyota_prius_2017_pt.dbc starts he
CM_ "toyota_prius_2017_pt.dbc starts he";
CM_ "toyota_prius_2017_pt.dbc starts her
CM_ "toyota_prius_2017_pt.dbc start";
CM_ "toyota_prius_2017_pt.dbc starts
CM_ "toyota_prius_2017_pt.dbc start";
CM_ "toyota_prius_2017_pt.dbc starts
CM_ "toyota_prius_2017_pt.dbc starts";
CM_ "toyota_prius_2017_pt.dbc starts 
CM_ "toyota_prius_2017_pt.dbc starts ";
CM_ "toyota_prius_2017_pt.dbc starts h
CM_ "toyota_prius_2017_pt.dbc starts";
CM_ "toyota_prius_2017_pt.dbc starts 
CM_ "toyota_prius_2017_pt.dbc starts ";
CM_ "toyota_prius_2017_pt.dbc starts h
CM_ "toyota_prius_2017_pt.dbc starts ";
CM_ "toyota_prius_2017_pt.dbc starts h
CM_ "toyota_prius_2017_pt.dbc starts h";
CM_ "toyota_prius_2017_pt.dbc starts he
CM_ "toyota_prius_2017_pt.dbc starts";
CM_ "toyota_prius_2017_pt.dbc starts 
CM_ "toyota_prius_2017_pt.dbc starts ";
CM_ "toyota_prius_2017_pt.dbc starts h
CM_ "toyota_prius_2017_pt.dbc starts ";
CM_ "toyota_prius_2017_pt.dbc starts h
CM_ "toyota_prius_2017_pt.dbc starts h";
CM_ "toyota_prius_2017_pt.dbc starts he
CM_ "toyota_prius_2017_pt.dbc starts ";
CM_ "toyota_prius_2017_pt.dbc starts h
CM_ "toyota_prius_2017_pt.dbc starts h";
CM_ "toyota_prius_2017_pt.dbc starts he
CM_ "toyota_prius_2017_pt.dbc starts h";
CM_ "toyota_prius_2017_pt.dbc starts he
CM_ "toyota_prius_2017_pt.dbc starts he";
CM_ "toyota_prius_2017_pt.dbc starts her
CM_ "toyota_prius_2017_pt.dbc starts";
CM_ "toyota_prius_2017_pt.dbc starts 
CM_ "toyota_prius_2017_pt.dbc starts ";
CM_ "toyota_prius_2017_pt.dbc starts h
CM_ "toyota_prius_2017_pt.dbc starts ";
CM_ "toyota_prius_2017_pt.dbc starts h
CM_ "toyota_prius_2017_pt.dbc starts h";
CM_ "toyota_prius_2017_pt.dbc starts he
CM_ "toyota_prius_2017_pt.dbc starts ";
CM_ "toyota_prius_2017_pt.dbc starts h
CM_ "toyota_prius_2017_pt.dbc starts h";
CM_ "toyota_prius_2017_pt.dbc starts he
CM_ "toyota_prius_2017_pt.dbc starts h";
CM_ "toyota_prius_2017_pt.dbc starts he
CM_ "toyota_prius_2017_pt.dbc starts he";
CM_ "toyota_prius_2017_pt.dbc starts her
CM_ "toyota_prius_2017_pt.dbc starts ";
CM_ "toyota_prius_2017_pt.dbc starts h
CM_ "toyota_prius_2017_pt.dbc starts h";
CM_ "toyota_prius_2017_pt.dbc starts he
CM_ "toyota_prius_2017_pt.dbc starts h";
CM_ "toyota_prius_2017_pt.dbc starts he
CM_ "toyota_prius_2017_pt.dbc starts he";
CM_ "toyota_prius_2017_pt.dbc starts her
CM_ "toyota_prius_2017_pt.dbc starts h";
CM_ "toyota_prius_2017_pt.dbc starts he
CM_ "toyota_prius_2017_pt.dbc starts he";
CM_ "toyota_prius_2017_pt.dbc starts her
CM_ "toyota_prius_2017_pt.dbc starts he";
CM_ "toyota_prius_2017_pt.dbc starts her
CM_ "toyota_prius_2017_pt.dbc starts her";
CM_ "toyota_prius_2017_pt.dbc starts here
CM_ "toyota_prius_2017_pt.dbc start";
CM_ "toyota_prius_2017_pt.dbc starts
CM_ "toyota_prius_2017_pt.dbc start";
CM_ "toyota_prius_2017_pt.dbc starts
CM_ "toyota_prius_2017_pt.dbc starts";
CM_ "toyota_prius_2017_pt.dbc starts 
CM_ "toyota_prius_2017_pt.dbc starts ";
CM_ "toyota_prius_2017_pt.dbc starts h
CM_ "toyota_prius_2017_pt.dbc starts";
CM_ "toyota_prius_2017_pt.dbc starts 
CM_ "toyota_prius_2017_pt.dbc starts ";
CM_ "toyota_prius_2017_pt.dbc starts h
CM_ "toyota_prius_2017_pt.dbc starts ";
CM_ "toyota_prius_2017_pt.dbc starts h
CM_ "toyota_prius_2017_pt.dbc starts h";
CM_ "toyota_prius_2017_pt.dbc starts he
CM_ "toyota_prius_2017_pt.dbc starts";
CM_ "toyota_prius_2017_pt.dbc starts 
CM_ "toyota_prius_2017_pt.dbc starts ";
CM_ "toyota_prius_2017_pt.dbc starts h
CM_ "toyota_prius_2017_pt.dbc starts ";
CM_ "toyota_prius_2017_pt.dbc starts h
CM_ "toyota_prius_2017_pt.dbc starts h";
CM_ "toyota_prius_2017_pt.dbc starts he
CM_ "toyota_prius_2017_pt.dbc starts ";
CM_ "toyota_prius_2017_pt.dbc starts h
CM_ "toyota_prius_2017_pt.dbc starts h";
CM_ "toyota_prius_2017_pt.dbc starts he
CM_ "toyota_prius_2017_pt.dbc starts h";
CM_ "toyota_prius_2017_pt.dbc starts he
CM_ "toyota_prius_2017_pt.dbc starts he";
CM_ "toyota_prius_2017_pt.dbc starts her
CM_ "toyota_prius_2017_pt.dbc starts";
CM_ "toyota_prius_2017_pt.dbc starts 
CM_ "toyota_prius_2017_pt.dbc starts ";
CM_ "toyota_prius_2017_pt.dbc starts h
CM_ "toyota_prius_2017_pt.dbc starts ";
CM_ "toyota_prius_2017_pt.dbc starts h
CM_ "toyota_prius_2017_pt.dbc starts h";
CM_ "toyota_prius_2017_pt.dbc starts he
CM_ "toyota_prius_2017_pt.dbc starts ";
CM_ "toyota_prius_2017_pt.dbc starts h
CM_ "toyota_prius_2017_pt.dbc starts h";
CM_ "toyota_prius_2017_pt.dbc starts he
CM_ "toyota_prius_2017_pt.dbc starts h";
CM_ "toyota_prius_2017_pt.dbc starts he
CM_ "toyota_prius_2017_pt.dbc starts he";
CM_ "toyota_prius_2017_pt.dbc starts her
CM_ "toyota_prius_2017_pt.dbc starts ";
CM_ "toyota_prius_2017_pt.dbc starts h
CM_ "toyota_prius_2017_pt.dbc starts h";
CM_ "toyota_prius_2017_pt.dbc starts he
CM_ "toyota_prius_2017_pt.dbc starts h";
CM_ "toyota_prius_2017_pt.dbc starts he
CM_ "toyota_prius_2017_pt.dbc starts he";
CM_ "toyota_prius_2017_pt.dbc starts her
CM_ "toyota_prius_2017_pt.dbc starts h";
CM_ "toyota_prius_2017_pt.dbc starts he
CM_ "toyota_prius_2017_pt.dbc starts he";
CM_ "toyota_prius_2017_pt.dbc starts her
CM_ "toyota_prius_2017_pt.dbc starts he";
CM_ "toyota_prius_2017_pt.dbc starts her
CM_ "toyota_prius_2017_pt.dbc starts her";
CM_ "toyota_prius_2017_pt.dbc starts here
CM_ "toyota_prius_2017_pt.dbc starts";
CM_ "toyota_prius_2017_pt.dbc starts 
CM_ "toyota_prius_2017_pt.dbc starts ";
CM_ "toyota_prius_2017_pt.dbc starts h
CM_ "toyota_prius_2017_pt.dbc starts ";
CM_ "toyota_prius_2017_pt.dbc starts h
CM_ "toyota_prius_2017_pt.dbc starts h";
CM_ "toyota_prius_2017_pt.dbc starts he
CM_ "toyota_prius_2017_pt.dbc starts ";
CM_ "toyota_prius_2017_pt.dbc starts h
CM_ "toyota_prius_2017_pt.dbc starts h";
CM_ "toyota_prius_2017_pt.dbc starts he
CM_ "toyota_prius_2017_pt.dbc starts h";
CM_ "toyota_prius_2017_pt.dbc starts he
CM_ "toyota_prius_2017_pt.dbc starts he";
CM_ "toyota_prius_2017_pt.dbc starts her
CM_ "toyota_prius_2017_pt.dbc starts ";
CM_ "toyota_prius_2017_pt.dbc starts h
CM_ "toyota_prius_2017_pt.dbc starts h";
CM_ "toyota_prius_2017_pt.dbc starts he
CM_ "toyota_prius_2017_pt.dbc starts h";
CM_ "toyota_prius_2017_pt.dbc starts he
CM_ "toyota_prius_2017_pt.dbc starts he";
CM_ "toyota_prius_2017_pt.dbc starts her
CM_ "toyota_prius_2017_pt.dbc starts h";
CM_ "toyota_prius_2017_pt.dbc starts he
CM_ "toyota_prius_2017_pt.dbc starts he";
CM_ "toyota_prius_2017_pt.dbc starts her
CM_ "toyota_prius_2017_pt.dbc starts he";
CM_ "toyota_prius_2017_pt.dbc starts her
CM_ "toyota_prius_2017_pt.dbc starts her";
CM_ "toyota_prius_2017_pt.dbc starts here
CM_ "toyota_prius_2017_pt.dbc starts ";
CM_ "toyota_prius_2017_pt.dbc starts h
CM_ "toyota_prius_2017_pt.dbc starts h";
CM_ "toyota_prius_2017_pt.dbc starts he
CM_ "toyota_prius_2017_pt.dbc starts h";
CM_ "toyota_prius_2017_pt.dbc starts he
CM_ "toyota_prius_2017_pt.dbc starts he";
CM_ "toyota_prius_2017_pt.dbc starts her
CM_ "toyota_prius_2017_pt.dbc starts h";
CM_ "toyota_prius_2017_pt.dbc starts he
CM_ "toyota_prius_2017_pt.dbc starts he";
CM_ "toyota_prius_2017_pt.dbc starts her
CM_ "toyota_prius_2017_pt.dbc starts he";
CM_ "toyota_prius_2017_pt.dbc starts her
CM_ "toyota_prius_2017_pt.dbc starts her";
CM_ "toyota_prius_2017_pt.dbc starts here
CM_ "toyota_prius_2017_pt.dbc starts h";
CM_ "toyota_prius_2017_pt.dbc starts he
CM_ "toyota_prius_2017_pt.dbc starts he";
CM_ "toyota_prius_2017_pt.dbc starts her
CM_ "toyota_prius_2017_pt.dbc starts he";
CM_ "toyota_prius_2017_pt.dbc starts her
CM_ "toyota_prius_2017_pt.dbc starts her";
CM_ "toyota_prius_2017_pt.dbc starts here
CM_ "toyota_prius_2017_pt.dbc starts he";
CM_ "toyota_prius_2017_pt.dbc starts her
CM_ "toyota_prius_2017_pt.dbc starts her";
CM_ "toyota_prius_2017_pt.dbc starts here
CM_ "toyota_prius_2017_pt.dbc starts her";
CM_ "toyota_prius_2017_pt.dbc starts here
CM_ "toyota_prius_2017_pt.dbc starts here";
CM_ "toyota_prius_2017_pt.dbc starts here"
BO_ 295 GEAR_PACKET: 8 XXX
SG_ CAR_MOVEMENT : 39|8@0- (1,0) [0|255] ";
